VERSION "created by canmatrix"

NS_ :

BS_:

BU_: BDC_Body CHC DME1 EME FLA NiVi ZGW Kombi Kombi_Basis Diagnosetool_FA_CAN CDC_ZGW DME2 ELV Gliwa_T1_Host FA_CAN_Dummy

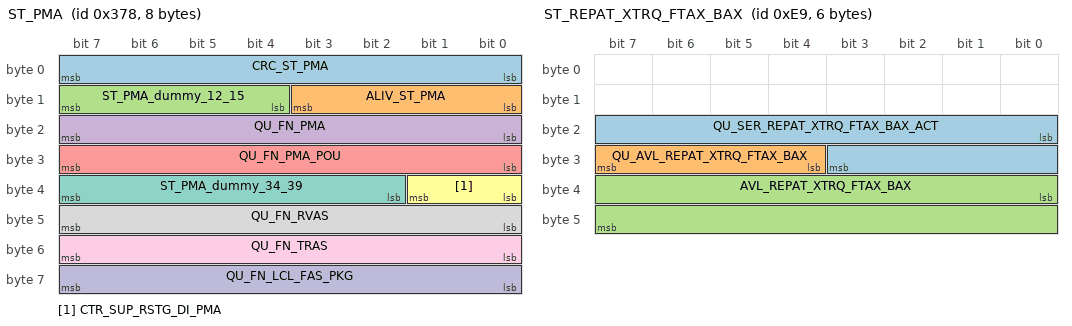
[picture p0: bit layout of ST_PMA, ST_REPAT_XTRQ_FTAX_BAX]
BO_ 888 ST_PMA: 8 ZGW
 SG_ CRC_ST_PMA : 0|8@1+ (1,0) [0|255] "This unit fulfills the required AUTOSAR reference to a unit. No real unit is defined." Vector__XXX
 SG_ ALIV_ST_PMA : 8|4@1+ (1,0) [0|15] "" Vector__XXX
 SG_ ST_PMA_dummy_12_15 : 12|4@1+ (1,0) [-8|7] "" Vector__XXX
 SG_ QU_FN_PMA : 16|8@1+ (1,0) [0|255] "" Vector__XXX
 SG_ QU_FN_PMA_POU : 24|8@1+ (1,0) [0|255] "" Vector__XXX
 SG_ CTR_SUP_RSTG_DI_PMA : 32|2@1+ (1,0) [0|3] "" Vector__XXX
 SG_ ST_PMA_dummy_34_39 : 34|6@1+ (1,0) [-32|31] "" Vector__XXX
 SG_ QU_FN_RVAS : 40|8@1+ (1,0) [0|255] "" Vector__XXX
 SG_ QU_FN_TRAS : 48|8@1+ (1,0) [0|255] "" Vector__XXX
 SG_ QU_FN_LCL_FAS_PKG : 56|8@1+ (1,0) [0|255] "" Vector__XXX

BO_ 1159 ST_PWF_CKM: 2 BDC_Body
 SG_ ST_PWF_SWO_LVG_CKM : 0|2@1+ (1,0) [0|3] "" ZGW

BO_ 669 ST_RCP: 8 ZGW
 SG_ RequestSBRandPreDriveCheck : 36|4@1+ (1,0) [0|15] "" Kombi,Kombi_Basis

BO_ 233 ST_REPAT_XTRQ_FTAX_BAX: 6 ZGW
 SG_ QU_SER_REPAT_XTRQ_FTAX_BAX_ACT : 16|12@1+ (1,0) [0|4095] "" DME1
 SG_ QU_AVL_REPAT_XTRQ_FTAX_BAX : 28|4@1+ (1,0) [0|15] "" DME1
 SG_ AVL_REPAT_XTRQ_FTAX_BAX : 32|16@1+ (1,-2500) [-5000|0] "Nm" DME1

BO_ 924 ST_RLS_ENGSTA_CARS: 8 ZGW
 SG_ ST_RLS_ENGSTA_CARS : 0|4@1+ (1,0) [0|15] "" BDC_Body

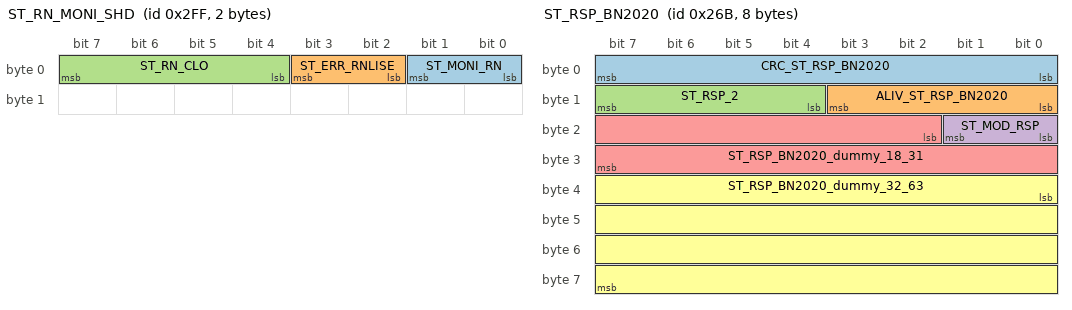
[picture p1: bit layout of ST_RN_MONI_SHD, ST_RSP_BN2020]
BO_ 767 ST_RN_MONI_SHD: 2 BDC_Body
 SG_ ST_MONI_RN : 0|2@1+ (1,0) [0|3] "" ZGW
 SG_ ST_ERR_RNLISE : 2|2@1+ (1,0) [0|3] "" ZGW
 SG_ ST_RN_CLO : 4|4@1+ (1,0) [0|15] "" ZGW

BO_ 619 ST_RSP_BN2020: 8 ZGW
 SG_ CRC_ST_RSP_BN2020 : 0|8@1+ (1,0) [0|255] "This unit fulfills the required AUTOSAR reference to a unit. No real unit is defined." Vector__XXX
 SG_ ALIV_ST_RSP_BN2020 : 8|4@1+ (1,0) [0|14] "This unit fulfills the required AUTOSAR reference to a unit. No real unit is defined." Vector__XXX
 SG_ ST_RSP_2 : 12|4@1+ (1,0) [0|15] "" Vector__XXX
 SG_ ST_MOD_RSP : 16|2@1+ (1,0) [0|3] "" Vector__XXX
 SG_ ST_RSP_BN2020_dummy_18_31 : 18|14@1+ (1,0) [-8192|8191] "" Vector__XXX
 SG_ ST_RSP_BN2020_dummy_32_63 : 32|32@1+ (1,0) [-2147483648|2147483647] "" Vector__XXX

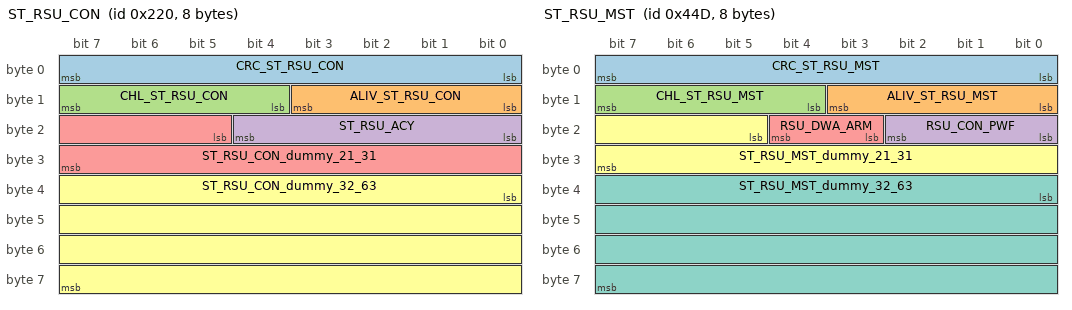
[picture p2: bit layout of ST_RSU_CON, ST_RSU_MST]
BO_ 544 ST_RSU_CON: 8 BDC_Body
 SG_ CRC_ST_RSU_CON : 0|8@1+ (1,0) [0|255] "This unit fulfills the required AUTOSAR reference to a unit. No real unit is defined." Vector__XXX
 SG_ ALIV_ST_RSU_CON : 8|4@1+ (1,0) [0|14] "This unit fulfills the required AUTOSAR reference to a unit. No real unit is defined." Vector__XXX
 SG_ CHL_ST_RSU_CON : 12|4@1+ (1,0) [0|14] "This unit fulfills the required AUTOSAR reference to a unit. No real unit is defined." Vector__XXX
 SG_ ST_RSU_ACY : 16|5@1+ (1,0) [0|31] "" Vector__XXX
 SG_ ST_RSU_CON_dummy_21_31 : 21|11@1+ (1,0) [-1024|1023] "" Vector__XXX
 SG_ ST_RSU_CON_dummy_32_63 : 32|32@1+ (1,0) [-2147483648|2147483647] "" Vector__XXX

BO_ 1101 ST_RSU_MST: 8 ZGW
 SG_ CRC_ST_RSU_MST : 0|8@1+ (1,0) [0|255] "This unit fulfills the required AUTOSAR reference to a unit. No real unit is defined." Vector__XXX
 SG_ ALIV_ST_RSU_MST : 8|4@1+ (1,0) [0|14] "This unit fulfills the required AUTOSAR reference to a unit. No real unit is defined." Vector__XXX
 SG_ CHL_ST_RSU_MST : 12|4@1+ (1,0) [0|14] "This unit fulfills the required AUTOSAR reference to a unit. No real unit is defined." Vector__XXX
 SG_ RSU_CON_PWF : 16|3@1+ (1,0) [0|7] "" Vector__XXX
 SG_ RSU_DWA_ARM : 19|2@1+ (1,0) [0|3] "" Vector__XXX
 SG_ ST_RSU_MST_dummy_21_31 : 21|11@1+ (1,0) [-1024|1023] "" Vector__XXX
 SG_ ST_RSU_MST_dummy_32_63 : 32|32@1+ (1,0) [-2147483648|2147483647] "" Vector__XXX

BO_ 1054 ST_SCHRG: 8 EME
 SG_ Multiplexor M : 0|8@1+ (1,0) [-128|127] "" Vector__XXX

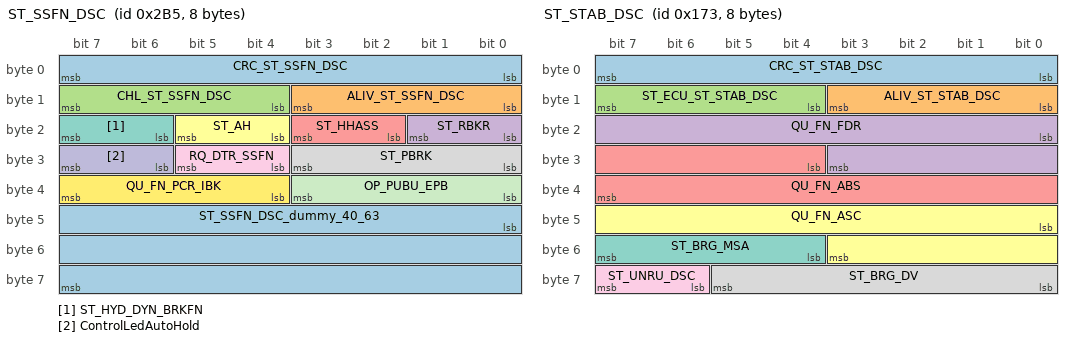
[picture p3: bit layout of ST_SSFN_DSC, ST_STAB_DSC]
BO_ 693 ST_SSFN_DSC: 8 ZGW
 SG_ CRC_ST_SSFN_DSC : 0|8@1+ (1,0) [0|255] "This unit fulfills the required AUTOSAR reference to a unit. No real unit is defined." Vector__XXX
 SG_ ALIV_ST_SSFN_DSC : 8|4@1+ (1,0) [0|14] "This unit fulfills the required AUTOSAR reference to a unit. No real unit is defined." Vector__XXX
 SG_ CHL_ST_SSFN_DSC : 12|4@1+ (1,0) [0|14] "This unit fulfills the required AUTOSAR reference to a unit. No real unit is defined." Vector__XXX
 SG_ ST_RBKR : 16|2@1+ (1,0) [0|3] "" Vector__XXX
 SG_ ST_HHASS : 18|2@1+ (1,0) [0|3] "" Vector__XXX
 SG_ ST_AH : 20|2@1+ (1,0) [0|3] "" Vector__XXX
 SG_ ST_HYD_DYN_BRKFN : 22|2@1+ (1,0) [0|3] "" Vector__XXX
 SG_ ST_PBRK : 24|4@1+ (1,0) [0|15] "" Vector__XXX
 SG_ RQ_DTR_SSFN : 28|2@1+ (1,0) [0|3] "" Vector__XXX
 SG_ ControlLedAutoHold : 30|2@1+ (1,0) [0|3] "" Vector__XXX
 SG_ OP_PUBU_EPB : 32|4@1+ (1,0) [0|15] "" Vector__XXX
 SG_ QU_FN_PCR_IBK : 36|4@1+ (1,0) [0|15] "" Vector__XXX
 SG_ ST_SSFN_DSC_dummy_40_63 : 40|24@1+ (1,0) [-8388608|8388607] "" Vector__XXX

BO_ 371 ST_STAB_DSC: 8 ZGW
 SG_ CRC_ST_STAB_DSC : 0|8@1+ (1,0) [0|255] "This unit fulfills the required AUTOSAR reference to a unit. No real unit is defined." Vector__XXX
 SG_ ALIV_ST_STAB_DSC : 8|4@1+ (1,0) [0|14] "This unit fulfills the required AUTOSAR reference to a unit. No real unit is defined." Vector__XXX
 SG_ ST_ECU_ST_STAB_DSC : 12|4@1+ (1,0) [0|15] "" Vector__XXX
 SG_ QU_FN_FDR : 16|12@1+ (1,0) [0|4095] "" Vector__XXX
 SG_ QU_FN_ABS : 28|12@1+ (1,0) [0|4095] "" Vector__XXX
 SG_ QU_FN_ASC : 40|12@1+ (1,0) [0|4095] "" Vector__XXX
 SG_ ST_BRG_MSA : 52|4@1+ (1,0) [0|15] "" Vector__XXX
 SG_ ST_BRG_DV : 56|6@1+ (1,0) [0|63] "" Vector__XXX
 SG_ ST_UNRU_DSC : 62|2@1+ (1,0) [0|3] "" Vector__XXX

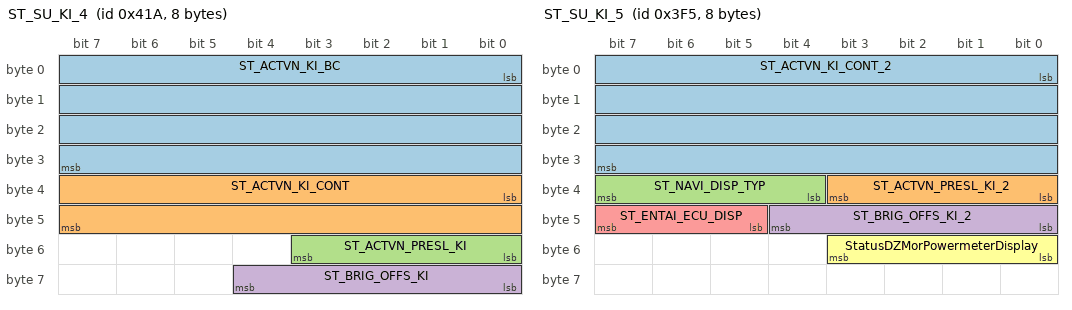
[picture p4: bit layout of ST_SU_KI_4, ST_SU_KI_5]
BO_ 1050 ST_SU_KI_4: 8 Kombi
 SG_ ST_ACTVN_KI_BC : 0|32@1+ (1,0) [0|4294967295] "" ZGW
 SG_ ST_ACTVN_KI_CONT : 32|16@1+ (1,0) [0|65535] "" ZGW
 SG_ ST_ACTVN_PRESL_KI : 48|4@1+ (1,0) [0|15] "" ZGW
 SG_ ST_BRIG_OFFS_KI : 56|5@1+ (1,0) [0|31] "" ZGW

BO_ 1013 ST_SU_KI_5: 8 Kombi
 SG_ ST_ACTVN_KI_CONT_2 : 0|32@1+ (1,0) [0|4294967295] "" ZGW
 SG_ ST_ACTVN_PRESL_KI_2 : 32|4@1+ (1,0) [0|15] "" ZGW
 SG_ ST_NAVI_DISP_TYP : 36|4@1+ (1,0) [0|15] "" ZGW
 SG_ ST_BRIG_OFFS_KI_2 : 40|5@1+ (1,0) [0|31] "" ZGW
 SG_ ST_ENTAI_ECU_DISP : 45|3@1+ (1,0) [0|7] "" ZGW
 SG_ StatusDZMorPowermeterDisplay : 48|4@1+ (1,0) [0|15] "" ZGW

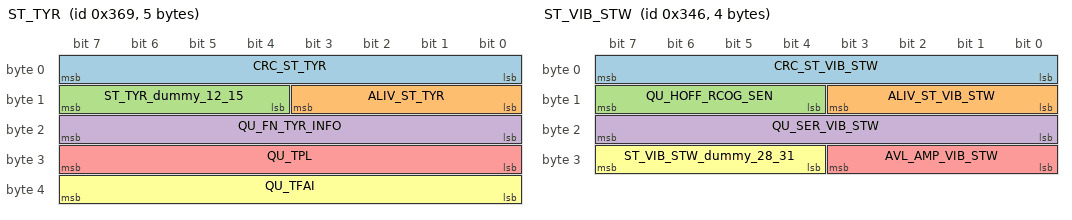
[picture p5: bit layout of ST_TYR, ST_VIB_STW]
BO_ 873 ST_TYR: 5 ZGW
 SG_ CRC_ST_TYR : 0|8@1+ (1,0) [0|255] "This unit fulfills the required AUTOSAR reference to a unit. No real unit is defined." Vector__XXX
 SG_ ALIV_ST_TYR : 8|4@1+ (1,0) [0|14] "This unit fulfills the required AUTOSAR reference to a unit. No real unit is defined." Vector__XXX
 SG_ ST_TYR_dummy_12_15 : 12|4@1+ (1,0) [-8|7] "" Vector__XXX
 SG_ QU_FN_TYR_INFO : 16|8@1+ (1,0) [0|255] "" Vector__XXX
 SG_ QU_TPL : 24|8@1+ (1,0) [0|255] "" Vector__XXX
 SG_ QU_TFAI : 32|8@1+ (1,0) [0|255] "" Vector__XXX

BO_ 905 ST_VA_HVBTC: 4 EME
 SG_ ST_CSOV_AIC : 8|4@1+ (1,0) [0|15] "" ZGW
 SG_ ST_PO_CSOV_AIC : 12|2@1+ (1,0) [0|3] "" ZGW

BO_ 895 ST_VEH_TONE: 2 ZGW
 SG_ ALIV_ST_VEH_TONE : 8|4@1+ (1,0) [0|14] "This unit fulfills the required AUTOSAR reference to a unit. No real unit is defined." Kombi
 SG_ ST_ACY_VEH_TONE : 12|2@1+ (1,0) [0|3] "" Kombi

BO_ 838 ST_VIB_STW: 4 BDC_Body
 SG_ CRC_ST_VIB_STW : 0|8@1+ (1,0) [0|255] "This unit fulfills the required AUTOSAR reference to a unit. No real unit is defined." Vector__XXX
 SG_ ALIV_ST_VIB_STW : 8|4@1+ (1,0) [0|15] "" Vector__XXX
 SG_ QU_HOFF_RCOG_SEN : 12|4@1+ (1,0) [0|15] "" Vector__XXX
 SG_ QU_SER_VIB_STW : 16|8@1+ (1,0) [0|255] "" Vector__XXX
 SG_ AVL_AMP_VIB_STW : 24|4@1+ (1,0) [0|15] "" Vector__XXX
 SG_ ST_VIB_STW_dummy_28_31 : 28|4@1+ (1,0) [-8|7] "" Vector__XXX

BO_ 271 ST_WBK: 8 ZGW
 SG_ QU_FN_BRCHAIN : 16|4@1+ (1,0) [0|15] "" NiVi
 SG_ QU_FN_WACHAIN : 20|4@1+ (1,0) [0|15] "" NiVi

BO_ 889 SU_CLE_DISP_DXP: 2 Kombi
 SG_ SU_FN_FRSG_ASST_DXP : 0|2@1+ (1,0) [0|3] "" FA_CAN_Dummy
 SG_ SU_VL_THO_ECS_DXP : 8|8@1+ (1,0) [1|250] "km/h" FA_CAN_Dummy

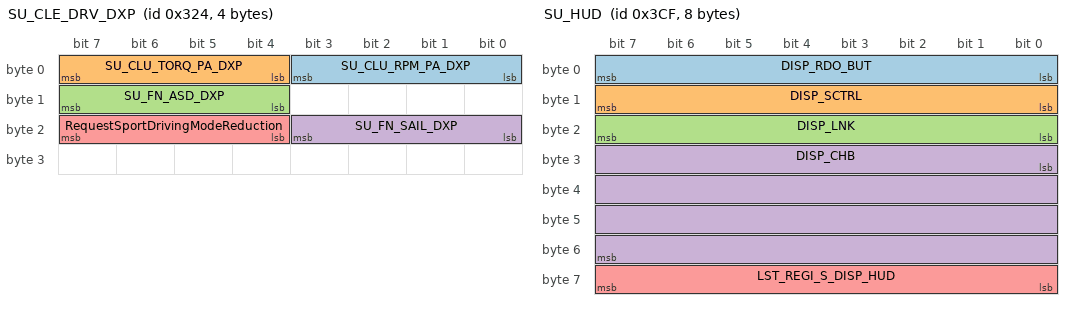
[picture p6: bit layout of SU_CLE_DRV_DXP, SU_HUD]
BO_ 804 SU_CLE_DRV_DXP: 4 DME1
 SG_ SU_CLU_RPM_PA_DXP : 0|4@1+ (1,0) [0|15] "" Vector__XXX
 SG_ SU_CLU_TORQ_PA_DXP : 4|4@1+ (1,0) [0|15] "" ZGW
 SG_ SU_FN_ASD_DXP : 12|4@1+ (1,0) [0|15] "" ZGW
 SG_ SU_FN_SAIL_DXP : 16|4@1+ (1,0) [0|15] "" Vector__XXX
 SG_ RequestSportDrivingModeReduction : 20|4@1+ (10,0) [0|1000] "%" Vector__XXX

BO_ 975 SU_HUD: 8 Kombi
 SG_ DISP_RDO_BUT : 0|8@1+ (1,0) [0|255] "" ZGW
 SG_ DISP_SCTRL : 8|8@1+ (1,0) [0|255] "" ZGW
 SG_ DISP_LNK : 16|8@1+ (1,0) [0|255] "" ZGW
 SG_ DISP_CHB : 24|32@1+ (1,0) [0|4294967295] "" ZGW
 SG_ LST_REGI_S_DISP_HUD : 56|8@1+ (1,0) [0|255] "" ZGW

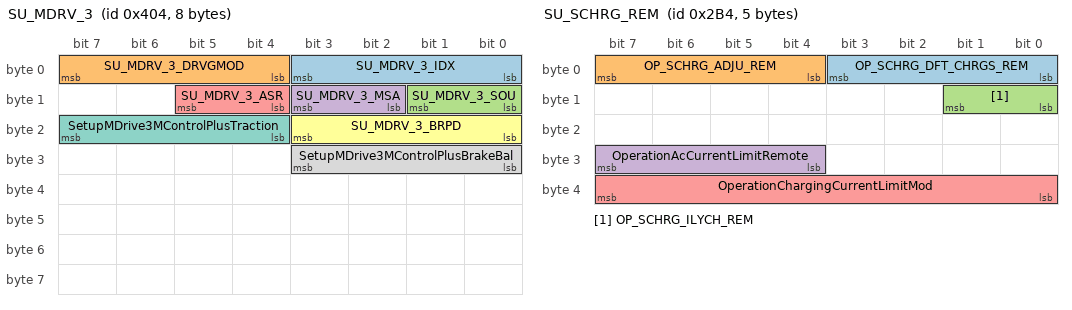
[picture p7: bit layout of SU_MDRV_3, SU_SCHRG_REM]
BO_ 1028 SU_MDRV_3: 8 ZGW
 SG_ SU_MDRV_3_IDX : 0|4@1+ (1,0) [0|15] "" DME2,DME1
 SG_ SU_MDRV_3_DRVGMOD : 4|4@1+ (1,0) [0|15] "" DME2,DME1
 SG_ SU_MDRV_3_SOU : 8|2@1+ (1,0) [0|3] "" DME2,DME1
 SG_ SU_MDRV_3_MSA : 10|2@1+ (1,0) [0|3] "" DME2,DME1
 SG_ SU_MDRV_3_ASR : 12|2@1+ (1,0) [0|3] "" DME2,DME1
 SG_ SU_MDRV_3_BRPD : 16|4@1+ (1,0) [0|15] "" DME2,DME1
 SG_ SetupMDrive3MControlPlusTraction : 20|4@1+ (1,0) [0|15] "" DME1
 SG_ SetupMDrive3MControlPlusBrakeBal : 24|4@1+ (1,0) [0|15] "" DME1

BO_ 1049 SU_PWF_CKM: 2 ZGW
 SG_ SU_PWF_SWO_LVG_CKM : 0|2@1+ (1,0) [0|3] "" BDC_Body

BO_ 737 SU_SCHRG: 8 ZGW
 SG_ Multiplexor M : 0|8@1+ (1,0) [-128|127] "" Vector__XXX

BO_ 646 SU_SCHRG_CERT: 8 ZGW
 SG_ Multiplexor M : 0|8@1+ (1,0) [-128|127] "" Vector__XXX

BO_ 717 SU_SCHRG_KEY: 2 BDC_Body
 SG_ OP_SCHRG_DFT_CHRGS_KEY : 0|4@1+ (1,0) [0|15] "" EME
 SG_ OP_SCHRG_ILYCH_KEY : 4|2@1+ (1,0) [0|3] "" EME

BO_ 692 SU_SCHRG_REM: 5 ZGW
 SG_ OP_SCHRG_DFT_CHRGS_REM : 0|4@1+ (1,0) [0|15] "" EME
 SG_ OP_SCHRG_ADJU_REM : 4|4@1+ (1,0) [0|15] "" EME
 SG_ OP_SCHRG_ILYCH_REM : 8|2@1+ (1,0) [0|3] "" EME
 SG_ OperationAcCurrentLimitRemote : 28|4@1+ (1,0) [0|15] "" EME
 SG_ OperationChargingCurrentLimitMod : 32|8@1+ (1,0) [0|250] "A" EME

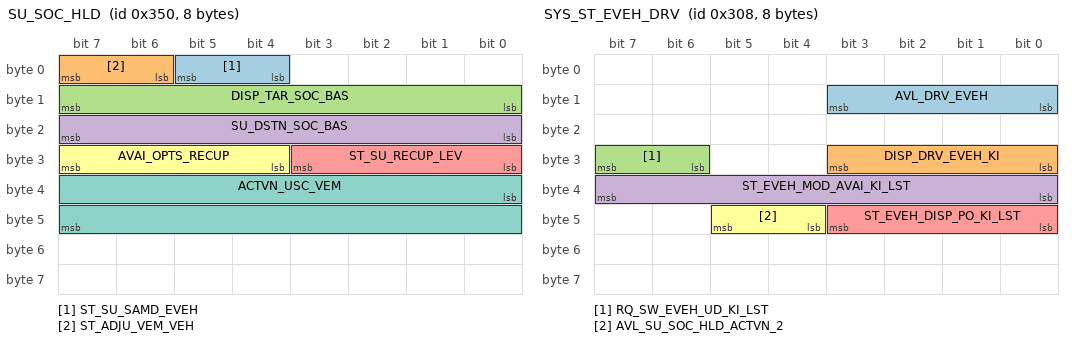
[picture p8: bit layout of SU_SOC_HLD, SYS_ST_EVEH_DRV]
BO_ 848 SU_SOC_HLD: 8 DME1
 SG_ ST_SU_SAMD_EVEH : 4|2@1+ (1,0) [0|3] "" ZGW
 SG_ ST_ADJU_VEM_VEH : 6|2@1+ (1,0) [0|3] "" ZGW
 SG_ DISP_TAR_SOC_BAS : 8|8@1+ (1,0) [0|100] "%" ZGW
 SG_ SU_DSTN_SOC_BAS : 16|8@1+ (1,0) [0|100] "%" EME
 SG_ ST_SU_RECUP_LEV : 24|4@1+ (1,0) [0|15] "" ZGW,Kombi,Kombi_Basis
 SG_ AVAI_OPTS_RECUP : 28|4@1+ (1,0) [0|15] "" ZGW,Kombi,Kombi_Basis
 SG_ ACTVN_USC_VEM : 32|16@1+ (1,0) [0|65535] "" EME

BO_ 776 SYS_ST_EVEH_DRV: 8 ZGW
 SG_ AVL_DRV_EVEH : 8|4@1+ (1,0) [0|15] "" Kombi,Kombi_Basis
 SG_ DISP_DRV_EVEH_KI : 24|4@1+ (1,0) [0|15] "" Kombi
 SG_ RQ_SW_EVEH_UD_KI_LST : 30|2@1+ (1,0) [0|3] "" Kombi,Kombi_Basis
 SG_ ST_EVEH_MOD_AVAI_KI_LST : 32|8@1+ (1,0) [0|255] "" Kombi,Kombi_Basis
 SG_ ST_EVEH_DISP_PO_KI_LST : 40|4@1+ (1,0) [0|15] "" Kombi,Kombi_Basis
 SG_ AVL_SU_SOC_HLD_ACTVN_2 : 44|2@1+ (1,0) [0|3] "" Kombi,Kombi_Basis

BO_ 129 SecurityStatus: 8 BDC_Body
 SG_ DataApplicationSecurityStatus : 0|64@1+ (1,0) [-9223372036854775808|9223372036854775807] "This unit fulfills the required AUTOSAR reference to a unit. No real unit is defined." Diagnosetool_FA_CAN

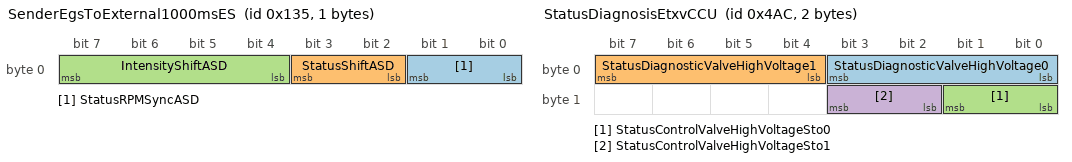
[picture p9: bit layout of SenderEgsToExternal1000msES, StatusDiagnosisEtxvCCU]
BO_ 309 SenderEgsToExternal1000msES: 1 DME1
 SG_ StatusRPMSyncASD : 0|2@1+ (1,0) [0|3] "" ZGW
 SG_ StatusShiftASD : 2|2@1+ (1,0) [0|3] "" ZGW
 SG_ IntensityShiftASD : 4|4@1+ (1,0) [0|10] "This unit fulfills the required AUTOSAR reference to a unit. No real unit is defined." ZGW

BO_ 750 ServiceBrake: 8 Kombi
 SG_ FunctionBrake : 0|4@1+ (1,0) [0|15] "" ZGW

BO_ 347 StatusAlcoholInterlockDevice: 8 BDC_Body
 SG_ StatusAlcoholInterlockDevice : 0|4@1+ (1,0) [0|15] "" Diagnosetool_FA_CAN
 SG_ StatusActivationAlcoholInterlock : 4|2@1+ (1,0) [0|3] "" Diagnosetool_FA_CAN

BO_ 1106 StatusCoolantLevel: 2 ZGW
 SG_ VoltageSensorCoolantLevel : 0|12@1+ (1.62,0) [0.00|10692.00] "mV" DME1

BO_ 1196 StatusDiagnosisEtxvCCU: 2 EME
 SG_ StatusDiagnosticValveHighVoltage0 : 0|4@1+ (1,0) [0|15] "" ZGW
 SG_ StatusDiagnosticValveHighVoltage1 : 4|4@1+ (1,0) [0|15] "" ZGW
 SG_ StatusControlValveHighVoltageSto0 : 8|2@1+ (1,0) [0|3] "" ZGW
 SG_ StatusControlValveHighVoltageSto1 : 10|2@1+ (1,0) [0|3] "" ZGW

BO_ 1095 StatusKeyAction: 8 BDC_Body
 SG_ StatusKeyFunction : 0|8@1+ (1,0) [0|255] "" ZGW
 SG_ StatusKeyId : 8|24@1+ (1,0) [0|16777215] "" ZGW

BO_ 702 StatusPowertrainErrorSourceInfor: 8 DME1
 SG_ StatusPowertrainErrorSource : 16|16@1+ (1,0) [0|65535] "" Diagnosetool_FA_CAN

BO_ 1197 StatusTemperatureAndDiagnosisFun: 8 EME
 SG_ StatusDiagnosisFunctionalValve1S0 : 0|8@1+ (1,0) [0|255] "" ZGW
 SG_ StatusDiagnosisFunctionalValve1S1 : 8|8@1+ (1,0) [0|255] "" ZGW
 SG_ StatusDiagnosisFunctionalCPIHigh : 16|8@1+ (1,0) [0|255] "" ZGW
 SG_ ActualValueTemperatureHighVoltag0 : 24|8@1+ (0.5,-40) [-60|3] "°C" ZGW
 SG_ ActualValueTemperatureHighVoltag1 : 32|8@1+ (0.5,-40) [-60|3] "°C" ZGW
 SG_ ActualValueTemperatureHighVoltag2 : 40|8@1+ (0.5,-40) [-60|3] "°C" ZGW
 SG_ ActualValueTemperatureHeatExchan : 48|10@1+ (0.125,-40) [-45.000|-29.250] "°C" ZGW
 SG_ RequestValveHighVoltageStorage1 : 58|2@1+ (1,0) [0|3] "" ZGW

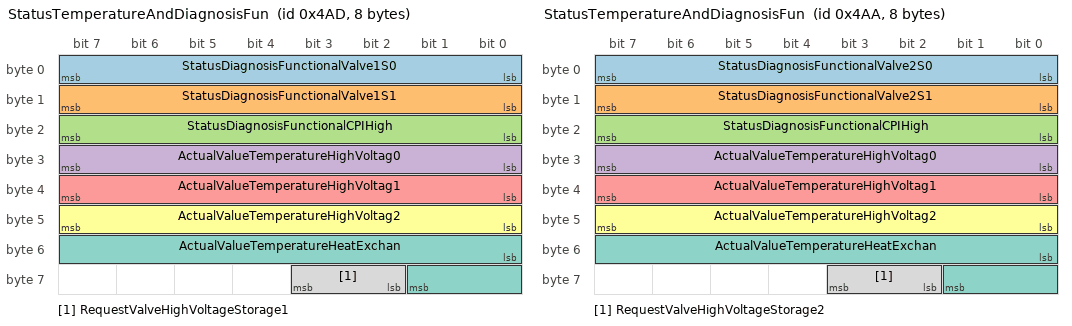
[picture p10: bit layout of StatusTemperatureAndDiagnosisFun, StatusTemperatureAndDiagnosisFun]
BO_ 1194 StatusTemperatureAndDiagnosisFun: 8 EME
 SG_ StatusDiagnosisFunctionalValve2S0 : 0|8@1+ (1,0) [0|255] "" ZGW
 SG_ StatusDiagnosisFunctionalValve2S1 : 8|8@1+ (1,0) [0|255] "" ZGW
 SG_ StatusDiagnosisFunctionalCPIHigh : 16|8@1+ (1,0) [0|255] "" ZGW
 SG_ ActualValueTemperatureHighVoltag0 : 24|8@1+ (0.5,-40) [-60|3] "°C" ZGW
 SG_ ActualValueTemperatureHighVoltag1 : 32|8@1+ (0.5,-40) [-60|3] "°C" ZGW
 SG_ ActualValueTemperatureHighVoltag2 : 40|8@1+ (0.5,-40) [-60|3] "°C" ZGW
 SG_ ActualValueTemperatureHeatExchan : 48|10@1+ (0.125,-40) [-45.000|-29.250] "°C" ZGW
 SG_ RequestValveHighVoltageStorage2 : 58|2@1+ (1,0) [0|3] "" ZGW

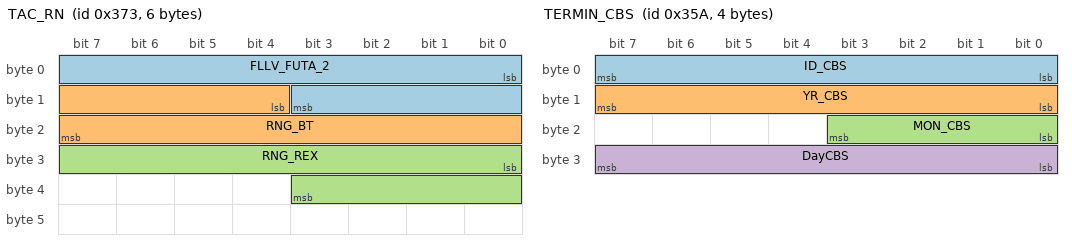
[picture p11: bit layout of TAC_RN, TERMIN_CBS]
BO_ 883 TAC_RN: 6 Kombi
 SG_ FLLV_FUTA_2 : 0|12@1+ (0.025,0) [0.000|2.550] "l" ZGW,DME2,DME1
 SG_ RNG_BT : 12|12@1+ (1,0) [0|4092] "km" ZGW,DME2,DME1
 SG_ RNG_REX : 24|12@1+ (1,0) [0|4092] "km" ZGW,DME2,DME1

BO_ 858 TERMIN_CBS: 4 ZGW
 SG_ ID_CBS : 0|8@1+ (1,0) [0|255] "" Kombi,Kombi_Basis
 SG_ YR_CBS : 8|8@1+ (1,0) [0|99] "This unit fulfills the required AUTOSAR reference to a unit. No real unit is defined." Kombi,Kombi_Basis
 SG_ MON_CBS : 16|4@1+ (1,0) [1|12] "This unit fulfills the required AUTOSAR reference to a unit. No real unit is defined." Kombi,Kombi_Basis
 SG_ DayCBS : 24|8@1+ (1,0) [1|31] "This unit fulfills the required AUTOSAR reference to a unit. No real unit is defined." Kombi,Kombi_Basis

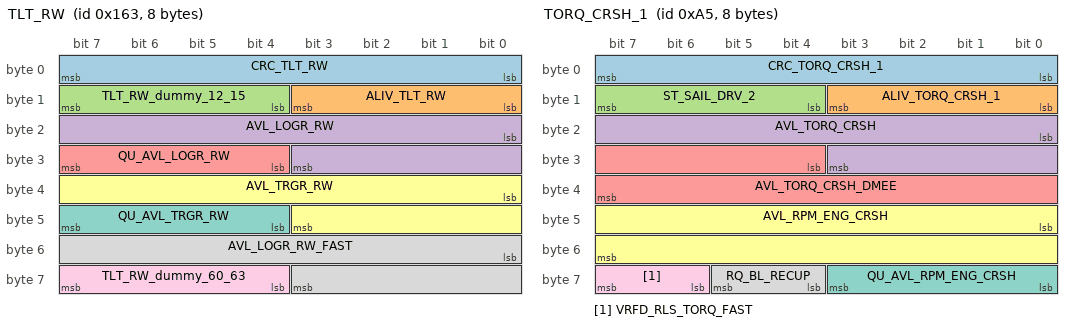
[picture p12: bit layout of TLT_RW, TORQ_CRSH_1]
BO_ 355 TLT_RW: 8 ZGW
 SG_ CRC_TLT_RW : 0|8@1+ (1,0) [0|255] "This unit fulfills the required AUTOSAR reference to a unit. No real unit is defined." Vector__XXX
 SG_ ALIV_TLT_RW : 8|4@1+ (1,0) [0|14] "This unit fulfills the required AUTOSAR reference to a unit. No real unit is defined." Vector__XXX
 SG_ TLT_RW_dummy_12_15 : 12|4@1+ (1,0) [-8|7] "" Vector__XXX
 SG_ AVL_LOGR_RW : 16|12@1+ (0.05,-64) [-67.20|-60.80] "°" Vector__XXX
 SG_ QU_AVL_LOGR_RW : 28|4@1+ (1,0) [0|15] "" Vector__XXX
 SG_ AVL_TRGR_RW : 32|12@1+ (0.05,-64) [-67.20|-60.80] "°" Vector__XXX
 SG_ QU_AVL_TRGR_RW : 44|4@1+ (1,0) [0|15] "" Vector__XXX
 SG_ AVL_LOGR_RW_FAST : 48|12@1+ (0.05,-64) [-67.20|-60.80] "°" Vector__XXX
 SG_ TLT_RW_dummy_60_63 : 60|4@1+ (1,0) [-8|7] "" Vector__XXX

BO_ 165 TORQ_CRSH_1: 8 DME1
 SG_ CRC_TORQ_CRSH_1 : 0|8@1+ (1,0) [0|255] "This unit fulfills the required AUTOSAR reference to a unit. No real unit is defined." Vector__XXX
 SG_ ALIV_TORQ_CRSH_1 : 8|4@1+ (1,0) [0|14] "This unit fulfills the required AUTOSAR reference to a unit. No real unit is defined." Vector__XXX
 SG_ ST_SAIL_DRV_2 : 12|4@1+ (1,0) [0|15] "" Vector__XXX
 SG_ AVL_TORQ_CRSH : 16|12@1+ (0.5,-1023.5) [-1535.25|-511.75] "Nm" Vector__XXX
 SG_ AVL_TORQ_CRSH_DMEE : 28|12@1+ (0.5,-1023.5) [-1535.25|-511.75] "Nm" Vector__XXX
 SG_ AVL_RPM_ENG_CRSH : 40|16@1+ (0.25,0) [0.00|3000.00] "1/min" Vector__XXX
 SG_ QU_AVL_RPM_ENG_CRSH : 56|4@1+ (1,0) [0|15] "" Vector__XXX
 SG_ RQ_BL_RECUP : 60|2@1+ (1,0) [0|3] "" Vector__XXX
 SG_ VRFD_RLS_TORQ_FAST : 62|2@1+ (1,0) [0|3] "" Vector__XXX

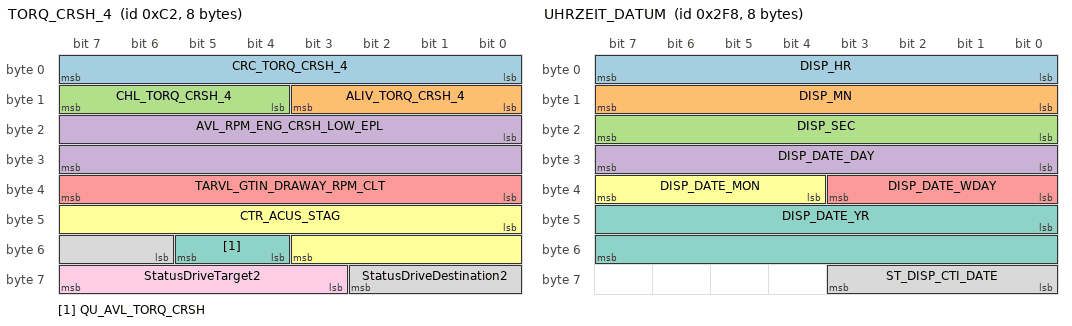
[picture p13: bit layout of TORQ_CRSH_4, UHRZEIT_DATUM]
BO_ 194 TORQ_CRSH_4: 8 DME1
 SG_ CRC_TORQ_CRSH_4 : 0|8@1+ (1,0) [0|255] "This unit fulfills the required AUTOSAR reference to a unit. No real unit is defined." Vector__XXX
 SG_ ALIV_TORQ_CRSH_4 : 8|4@1+ (1,0) [0|14] "This unit fulfills the required AUTOSAR reference to a unit. No real unit is defined." Vector__XXX
 SG_ CHL_TORQ_CRSH_4 : 12|4@1+ (1,0) [0|14] "This unit fulfills the required AUTOSAR reference to a unit. No real unit is defined." Vector__XXX
 SG_ AVL_RPM_ENG_CRSH_LOW_EPL : 16|16@1+ (1,-900) [-1800|63732] "1/min" Vector__XXX
 SG_ TARVL_GTIN_DRAWAY_RPM_CLT : 32|8@1+ (10,500) [5500|25500] "1/min" Vector__XXX
 SG_ CTR_ACUS_STAG : 40|12@1+ (1,0) [0|4092] "This unit fulfills the required AUTOSAR reference to a unit. No real unit is defined." Vector__XXX
 SG_ QU_AVL_TORQ_CRSH : 52|2@1+ (1,0) [0|3] "" Vector__XXX
 SG_ StatusDriveDestination2 : 54|5@1+ (1,0) [0|31] "" Vector__XXX
 SG_ StatusDriveTarget2 : 59|5@1+ (1,0) [0|31] "" Vector__XXX

BO_ 760 UHRZEIT_DATUM: 8 Kombi
 SG_ DISP_HR : 0|8@1+ (1,0) [0|23] "h" Vector__XXX
 SG_ DISP_MN : 8|8@1+ (1,0) [0|59] "min" Vector__XXX
 SG_ DISP_SEC : 16|8@1+ (1,0) [0|59] "s" Vector__XXX
 SG_ DISP_DATE_DAY : 24|8@1+ (1,0) [1|31] "This unit fulfills the required AUTOSAR reference to a unit. No real unit is defined." Vector__XXX
 SG_ DISP_DATE_WDAY : 32|4@1+ (1,0) [0|15] "" Vector__XXX
 SG_ DISP_DATE_MON : 36|4@1+ (1,0) [1|12] "This unit fulfills the required AUTOSAR reference to a unit. No real unit is defined." Vector__XXX
 SG_ DISP_DATE_YR : 40|16@1+ (1,0) [1|65534] "This unit fulfills the required AUTOSAR reference to a unit. No real unit is defined." Vector__XXX
 SG_ ST_DISP_CTI_DATE : 56|4@1+ (1,0) [0|15] "" Vector__XXX

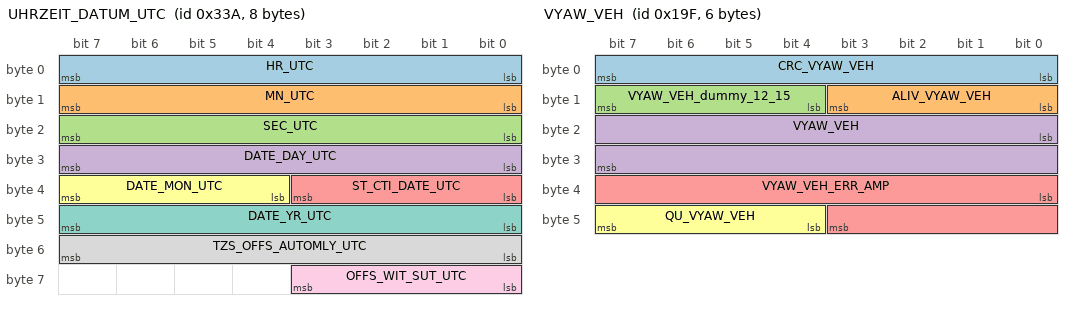
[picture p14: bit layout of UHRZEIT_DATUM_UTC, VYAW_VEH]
BO_ 826 UHRZEIT_DATUM_UTC: 8 Kombi
 SG_ HR_UTC : 0|8@1+ (1,0) [0|23] "h" CDC_ZGW,BDC_Body,ZGW
 SG_ MN_UTC : 8|8@1+ (1,0) [0|59] "min" CDC_ZGW,BDC_Body,ZGW
 SG_ SEC_UTC : 16|8@1+ (1,0) [0|59] "This unit fulfills the required AUTOSAR reference to a unit. No real unit is defined." CDC_ZGW,BDC_Body,ZGW
 SG_ DATE_DAY_UTC : 24|8@1+ (1,1) [2|32] "This unit fulfills the required AUTOSAR reference to a unit. No real unit is defined." CDC_ZGW,BDC_Body,ZGW
 SG_ ST_CTI_DATE_UTC : 32|4@1+ (1,0) [0|15] "" CDC_ZGW,BDC_Body,ZGW
 SG_ DATE_MON_UTC : 36|4@1+ (1,1) [2|13] "This unit fulfills the required AUTOSAR reference to a unit. No real unit is defined." CDC_ZGW,BDC_Body,ZGW
 SG_ DATE_YR_UTC : 40|8@1+ (1,1) [2|253] "This unit fulfills the required AUTOSAR reference to a unit. No real unit is defined." CDC_ZGW,BDC_Body,ZGW
 SG_ TZS_OFFS_AUTOMLY_UTC : 48|8@1+ (0.25,-20) [-25.00|-9.25] "h" ZGW
 SG_ OFFS_WIT_SUT_UTC : 56|4@1+ (0.5,-3) [-4.5|-1.5] "h" ZGW

BO_ 772 U_BN: 6 DME1
 SG_ U_IBS : 16|16@1+ (0.001,0) [0.000|0.065532] "V" ZGW,CHC
 SG_ ST_STRY_U_PWMG : 32|4@1+ (1,0) [0|15] "" ZGW,DME1

BO_ 415 VYAW_VEH: 6 ZGW
 SG_ CRC_VYAW_VEH : 0|8@1+ (1,0) [0|255] "This unit fulfills the required AUTOSAR reference to a unit. No real unit is defined." Vector__XXX
 SG_ ALIV_VYAW_VEH : 8|4@1+ (1,0) [0|14] "This unit fulfills the required AUTOSAR reference to a unit. No real unit is defined." Vector__XXX
 SG_ VYAW_VEH_dummy_12_15 : 12|4@1+ (1,0) [-8|7] "" Vector__XXX
 SG_ VYAW_VEH : 16|16@1+ (0.005,-163.84) [-164.65920|-163.02085] "°/s" Vector__XXX
 SG_ VYAW_VEH_ERR_AMP : 32|12@1+ (0.0125,0) [0.0000|0.6250] "°/s" Vector__XXX
 SG_ QU_VYAW_VEH : 44|4@1+ (1,0) [0|15] "" Vector__XXX

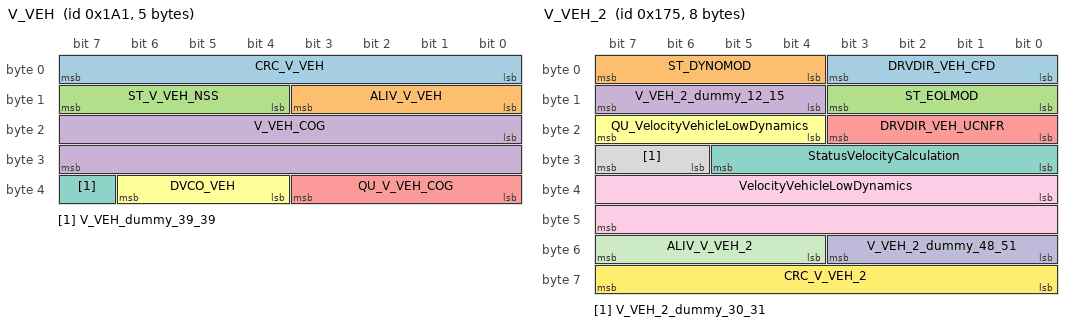
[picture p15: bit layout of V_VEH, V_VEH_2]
BO_ 417 V_VEH: 5 ZGW
 SG_ CRC_V_VEH : 0|8@1+ (1,0) [0|255] "This unit fulfills the required AUTOSAR reference to a unit. No real unit is defined." Vector__XXX
 SG_ ALIV_V_VEH : 8|4@1+ (1,0) [0|14] "This unit fulfills the required AUTOSAR reference to a unit. No real unit is defined." Vector__XXX
 SG_ ST_V_VEH_NSS : 12|4@1+ (1,0) [0|15] "" Vector__XXX
 SG_ V_VEH_COG : 16|16@1+ (0.015625,0) [0.000000|5.468750] "km/h" Vector__XXX
 SG_ QU_V_VEH_COG : 32|4@1+ (1,0) [0|15] "" Vector__XXX
 SG_ DVCO_VEH : 36|3@1+ (1,0) [0|7] "" Vector__XXX
 SG_ V_VEH_dummy_39_39 : 39|1@1+ (1,0) [-1|0] "" Vector__XXX

BO_ 373 V_VEH_2: 8 ZGW
 SG_ DRVDIR_VEH_CFD : 0|4@1+ (1,0) [0|15] "" Vector__XXX
 SG_ ST_DYNOMOD : 4|4@1+ (1,0) [0|15] "" Vector__XXX
 SG_ ST_EOLMOD : 8|4@1+ (1,0) [0|15] "" Vector__XXX
 SG_ V_VEH_2_dummy_12_15 : 12|4@1+ (1,0) [-8|7] "" Vector__XXX
 SG_ DRVDIR_VEH_UCNFR : 16|4@1+ (1,0) [0|15] "" Vector__XXX
 SG_ QU_VelocityVehicleLowDynamics : 20|4@1+ (1,0) [0|15] "" Vector__XXX
 SG_ StatusVelocityCalculation : 24|6@1+ (1,0) [0|63] "" Vector__XXX
 SG_ V_VEH_2_dummy_30_31 : 30|2@1+ (1,0) [-2|1] "" Vector__XXX
 SG_ VelocityVehicleLowDynamics : 32|16@1+ (0.015625,0) [0.000000|5.468750] "km/h" Vector__XXX
 SG_ V_VEH_2_dummy_48_51 : 48|4@1+ (1,0) [-8|7] "" Vector__XXX
 SG_ ALIV_V_VEH_2 : 52|4@1+ (1,0) [0|14] "This unit fulfills the required AUTOSAR reference to a unit. No real unit is defined." Vector__XXX
 SG_ CRC_V_VEH_2 : 56|8@1+ (1,0) [0|255] "This unit fulfills the required AUTOSAR reference to a unit. No real unit is defined." Vector__XXX

BO_ 1037 WEL_STAG: 8 Kombi
 SG_ ST_STAGMST : 0|8@1+ (1,0) [0|255] "" ZGW
 SG_ TR_STAG_HU : 8|8@1+ (1,0) [0|255] "" ZGW

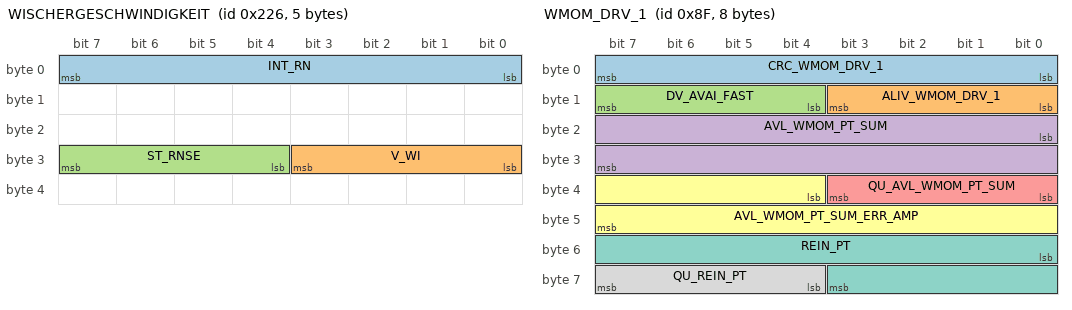
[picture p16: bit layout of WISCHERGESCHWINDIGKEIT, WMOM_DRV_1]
BO_ 550 WISCHERGESCHWINDIGKEIT: 5 BDC_Body
 SG_ INT_RN : 0|8@1+ (0.5,0) [0|63.5] "%" CDC_ZGW,ZGW,FLA
 SG_ V_WI : 24|4@1+ (2,33) [103|155] "1/min" CDC_ZGW,FLA,DME2,DME1,ZGW,NiVi
 SG_ ST_RNSE : 28|4@1+ (1,0) [0|15] "" ZGW,FLA

BO_ 143 WMOM_DRV_1: 8 DME1
 SG_ CRC_WMOM_DRV_1 : 0|8@1+ (1,0) [0|255] "This unit fulfills the required AUTOSAR reference to a unit. No real unit is defined." Vector__XXX
 SG_ ALIV_WMOM_DRV_1 : 8|4@1+ (1,0) [0|15] "" Vector__XXX
 SG_ DV_AVAI_FAST : 12|4@1+ (1,0) [0|15] "" Vector__XXX
 SG_ AVL_WMOM_PT_SUM : 16|16@1+ (1,-32000) [-64000|0] "Nm" Vector__XXX
 SG_ QU_AVL_WMOM_PT_SUM : 32|4@1+ (1,0) [0|15] "" Vector__XXX
 SG_ AVL_WMOM_PT_SUM_ERR_AMP : 36|12@1+ (4,0) [0|64000] "Nm" Vector__XXX
 SG_ REIN_PT : 48|12@1+ (0.125,0) [0.000|63.96875] "This unit fulfills the required AUTOSAR reference to a unit. No real unit is defined." Vector__XXX
 SG_ QU_REIN_PT : 60|4@1+ (1,0) [0|15] "" Vector__XXX

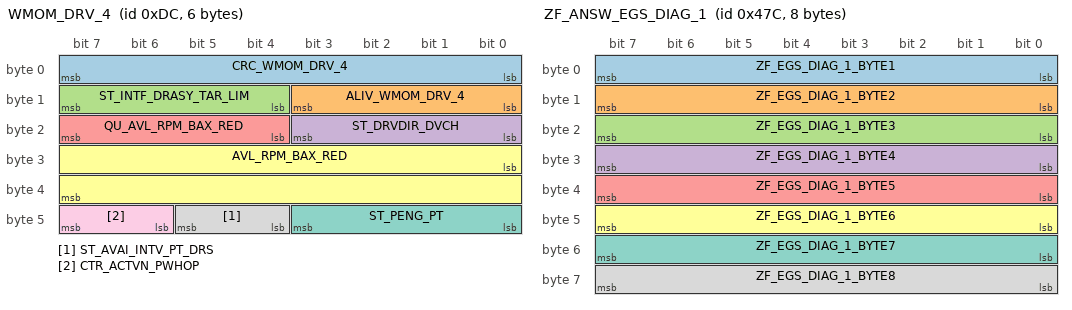
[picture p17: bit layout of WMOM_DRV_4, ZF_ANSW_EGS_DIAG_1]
BO_ 220 WMOM_DRV_4: 6 DME1
 SG_ CRC_WMOM_DRV_4 : 0|8@1+ (1,0) [0|255] "This unit fulfills the required AUTOSAR reference to a unit. No real unit is defined." Vector__XXX
 SG_ ALIV_WMOM_DRV_4 : 8|4@1+ (1,0) [0|14] "This unit fulfills the required AUTOSAR reference to a unit. No real unit is defined." Vector__XXX
 SG_ ST_INTF_DRASY_TAR_LIM : 12|4@1+ (1,0) [0|15] "" Vector__XXX
 SG_ ST_DRVDIR_DVCH : 16|4@1+ (1,0) [0|15] "" Vector__XXX
 SG_ QU_AVL_RPM_BAX_RED : 20|4@1+ (1,0) [0|15] "" Vector__XXX
 SG_ AVL_RPM_BAX_RED : 24|16@1+ (1,-2000) [-4000|12000] "1/min" Vector__XXX
 SG_ ST_PENG_PT : 40|4@1+ (1,0) [0|15] "" Vector__XXX
 SG_ ST_AVAI_INTV_PT_DRS : 44|2@1+ (1,0) [0|3] "" Vector__XXX
 SG_ CTR_ACTVN_PWHOP : 46|2@1+ (1,0) [0|3] "" Vector__XXX

BO_ 1985 XCPIFMDAQ1: 8 DME1
 SG_ XCPDummysignalIFMDAQ1 : 0|8@1+ (1,0) [0|255] "This unit fulfills the required AUTOSAR reference to a unit. No real unit is defined." ZGW

BO_ 1986 XCPIFMDAQ2: 8 DME1
 SG_ XCPDummysignalIFMDAQ2 : 0|8@1+ (1,0) [0|255] "This unit fulfills the required AUTOSAR reference to a unit. No real unit is defined." ZGW

BO_ 1987 XCPIFMDAQ3: 8 DME1
 SG_ XCPDummysignalIFMDAQ3 : 0|8@1+ (1,0) [0|255] "This unit fulfills the required AUTOSAR reference to a unit. No real unit is defined." ZGW

BO_ 1974 XCPIFMRequest: 8 ZGW
 SG_ XCPDummysignalIFMRequest : 0|8@1+ (1,0) [0|255] "This unit fulfills the required AUTOSAR reference to a unit. No real unit is defined." DME1

BO_ 1984 XCPIFMResponse: 8 DME1
 SG_ XCPDummysignalIFMResponse : 0|8@1+ (1,0) [0|255] "This unit fulfills the required AUTOSAR reference to a unit. No real unit is defined." ZGW

BO_ 1148 ZF_ANSW_EGS_DIAG_1: 8 DME1
 SG_ ZF_EGS_DIAG_1_BYTE1 : 0|8@1+ (1,0) [0|255] "This unit fulfills the required AUTOSAR reference to a unit. No real unit is defined." ZGW
 SG_ ZF_EGS_DIAG_1_BYTE2 : 8|8@1+ (1,0) [0|255] "This unit fulfills the required AUTOSAR reference to a unit. No real unit is defined." ZGW
 SG_ ZF_EGS_DIAG_1_BYTE3 : 16|8@1+ (1,0) [0|255] "This unit fulfills the required AUTOSAR reference to a unit. No real unit is defined." ZGW
 SG_ ZF_EGS_DIAG_1_BYTE4 : 24|8@1+ (1,0) [0|255] "This unit fulfills the required AUTOSAR reference to a unit. No real unit is defined." ZGW
 SG_ ZF_EGS_DIAG_1_BYTE5 : 32|8@1+ (1,0) [0|255] "This unit fulfills the required AUTOSAR reference to a unit. No real unit is defined." ZGW
 SG_ ZF_EGS_DIAG_1_BYTE6 : 40|8@1+ (1,0) [0|255] "This unit fulfills the required AUTOSAR reference to a unit. No real unit is defined." ZGW
 SG_ ZF_EGS_DIAG_1_BYTE7 : 48|8@1+ (1,0) [0|255] "This unit fulfills the required AUTOSAR reference to a unit. No real unit is defined." ZGW
 SG_ ZF_EGS_DIAG_1_BYTE8 : 56|8@1+ (1,0) [0|255] "This unit fulfills the required AUTOSAR reference to a unit. No real unit is defined." ZGW

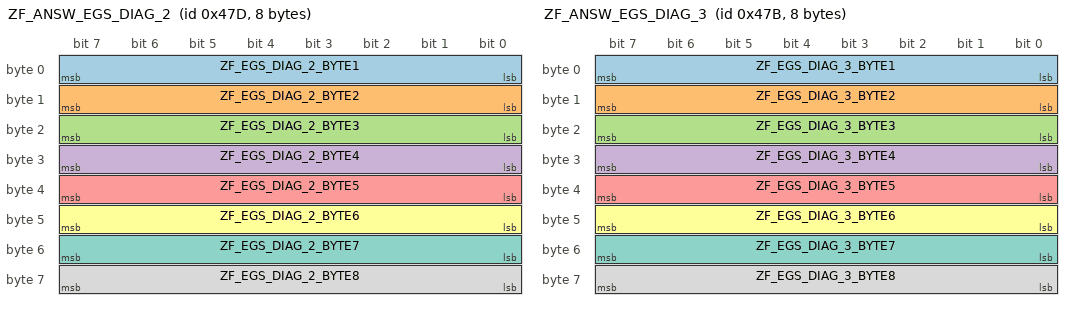
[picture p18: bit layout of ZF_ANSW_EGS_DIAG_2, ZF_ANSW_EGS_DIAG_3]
BO_ 1149 ZF_ANSW_EGS_DIAG_2: 8 DME1
 SG_ ZF_EGS_DIAG_2_BYTE1 : 0|8@1+ (1,0) [0|255] "This unit fulfills the required AUTOSAR reference to a unit. No real unit is defined." ZGW
 SG_ ZF_EGS_DIAG_2_BYTE2 : 8|8@1+ (1,0) [0|255] "This unit fulfills the required AUTOSAR reference to a unit. No real unit is defined." ZGW
 SG_ ZF_EGS_DIAG_2_BYTE3 : 16|8@1+ (1,0) [0|255] "This unit fulfills the required AUTOSAR reference to a unit. No real unit is defined." ZGW
 SG_ ZF_EGS_DIAG_2_BYTE4 : 24|8@1+ (1,0) [0|255] "This unit fulfills the required AUTOSAR reference to a unit. No real unit is defined." ZGW
 SG_ ZF_EGS_DIAG_2_BYTE5 : 32|8@1+ (1,0) [0|255] "This unit fulfills the required AUTOSAR reference to a unit. No real unit is defined." ZGW
 SG_ ZF_EGS_DIAG_2_BYTE6 : 40|8@1+ (1,0) [0|255] "This unit fulfills the required AUTOSAR reference to a unit. No real unit is defined." ZGW
 SG_ ZF_EGS_DIAG_2_BYTE7 : 48|8@1+ (1,0) [0|255] "This unit fulfills the required AUTOSAR reference to a unit. No real unit is defined." ZGW
 SG_ ZF_EGS_DIAG_2_BYTE8 : 56|8@1+ (1,0) [0|255] "This unit fulfills the required AUTOSAR reference to a unit. No real unit is defined." ZGW

BO_ 1147 ZF_ANSW_EGS_DIAG_3: 8 DME1
 SG_ ZF_EGS_DIAG_3_BYTE1 : 0|8@1+ (1,0) [0|255] "This unit fulfills the required AUTOSAR reference to a unit. No real unit is defined." ZGW
 SG_ ZF_EGS_DIAG_3_BYTE2 : 8|8@1+ (1,0) [0|255] "This unit fulfills the required AUTOSAR reference to a unit. No real unit is defined." ZGW
 SG_ ZF_EGS_DIAG_3_BYTE3 : 16|8@1+ (1,0) [0|255] "This unit fulfills the required AUTOSAR reference to a unit. No real unit is defined." ZGW
 SG_ ZF_EGS_DIAG_3_BYTE4 : 24|8@1+ (1,0) [0|255] "This unit fulfills the required AUTOSAR reference to a unit. No real unit is defined." ZGW
 SG_ ZF_EGS_DIAG_3_BYTE5 : 32|8@1+ (1,0) [0|255] "This unit fulfills the required AUTOSAR reference to a unit. No real unit is defined." ZGW
 SG_ ZF_EGS_DIAG_3_BYTE6 : 40|8@1+ (1,0) [0|255] "This unit fulfills the required AUTOSAR reference to a unit. No real unit is defined." ZGW
 SG_ ZF_EGS_DIAG_3_BYTE7 : 48|8@1+ (1,0) [0|255] "This unit fulfills the required AUTOSAR reference to a unit. No real unit is defined." ZGW
 SG_ ZF_EGS_DIAG_3_BYTE8 : 56|8@1+ (1,0) [0|255] "This unit fulfills the required AUTOSAR reference to a unit. No real unit is defined." ZGW

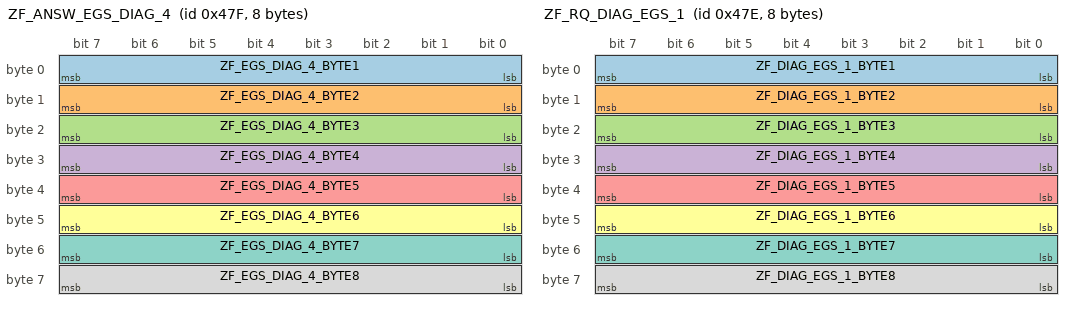
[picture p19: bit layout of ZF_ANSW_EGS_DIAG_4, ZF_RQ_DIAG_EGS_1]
BO_ 1151 ZF_ANSW_EGS_DIAG_4: 8 DME1
 SG_ ZF_EGS_DIAG_4_BYTE1 : 0|8@1+ (1,0) [0|255] "This unit fulfills the required AUTOSAR reference to a unit. No real unit is defined." ZGW
 SG_ ZF_EGS_DIAG_4_BYTE2 : 8|8@1+ (1,0) [0|255] "This unit fulfills the required AUTOSAR reference to a unit. No real unit is defined." ZGW
 SG_ ZF_EGS_DIAG_4_BYTE3 : 16|8@1+ (1,0) [0|255] "This unit fulfills the required AUTOSAR reference to a unit. No real unit is defined." ZGW
 SG_ ZF_EGS_DIAG_4_BYTE4 : 24|8@1+ (1,0) [0|255] "This unit fulfills the required AUTOSAR reference to a unit. No real unit is defined." ZGW
 SG_ ZF_EGS_DIAG_4_BYTE5 : 32|8@1+ (1,0) [0|255] "This unit fulfills the required AUTOSAR reference to a unit. No real unit is defined." ZGW
 SG_ ZF_EGS_DIAG_4_BYTE6 : 40|8@1+ (1,0) [0|255] "This unit fulfills the required AUTOSAR reference to a unit. No real unit is defined." ZGW
 SG_ ZF_EGS_DIAG_4_BYTE7 : 48|8@1+ (1,0) [0|255] "This unit fulfills the required AUTOSAR reference to a unit. No real unit is defined." ZGW
 SG_ ZF_EGS_DIAG_4_BYTE8 : 56|8@1+ (1,0) [0|255] "This unit fulfills the required AUTOSAR reference to a unit. No real unit is defined." ZGW

BO_ 1150 ZF_RQ_DIAG_EGS_1: 8 ZGW
 SG_ ZF_DIAG_EGS_1_BYTE1 : 0|8@1+ (1,0) [0|255] "This unit fulfills the required AUTOSAR reference to a unit. No real unit is defined." DME1
 SG_ ZF_DIAG_EGS_1_BYTE2 : 8|8@1+ (1,0) [0|255] "This unit fulfills the required AUTOSAR reference to a unit. No real unit is defined." DME1
 SG_ ZF_DIAG_EGS_1_BYTE3 : 16|8@1+ (1,0) [0|255] "This unit fulfills the required AUTOSAR reference to a unit. No real unit is defined." DME1
 SG_ ZF_DIAG_EGS_1_BYTE4 : 24|8@1+ (1,0) [0|255] "This unit fulfills the required AUTOSAR reference to a unit. No real unit is defined." DME1
 SG_ ZF_DIAG_EGS_1_BYTE5 : 32|8@1+ (1,0) [0|255] "This unit fulfills the required AUTOSAR reference to a unit. No real unit is defined." DME1
 SG_ ZF_DIAG_EGS_1_BYTE6 : 40|8@1+ (1,0) [0|255] "This unit fulfills the required AUTOSAR reference to a unit. No real unit is defined." DME1
 SG_ ZF_DIAG_EGS_1_BYTE7 : 48|8@1+ (1,0) [0|255] "This unit fulfills the required AUTOSAR reference to a unit. No real unit is defined." DME1
 SG_ ZF_DIAG_EGS_1_BYTE8 : 56|8@1+ (1,0) [0|255] "This unit fulfills the required AUTOSAR reference to a unit. No real unit is defined." DME1

BO_TX_BU_ 1050 : Kombi,Kombi_Basis;
BO_TX_BU_ 1013 : Kombi,Kombi_Basis;
BO_TX_BU_ 889 : Kombi,Kombi_Basis;
BO_TX_BU_ 975 : Kombi,Kombi_Basis;
BO_TX_BU_ 750 : Kombi,Kombi_Basis;
BO_TX_BU_ 760 : Kombi,Kombi_Basis;
BO_TX_BU_ 826 : Kombi,Kombi_Basis;
BO_TX_BU_ 772 : DME1,ZGW;
BO_TX_BU_ 1037 : Kombi,Kombi_Basis;
CM_ BO_ 737  "�bermittlung Benutzereinstellungen intelligentes Laden von HU an HvPM
==========
Transmission of user settings for Intelligent Charging from HU to HvPM";
CM_ BO_ 646  "Diese Schnittstelle wurde f�r die Funktion Intelligentes Laden 2.0 (mit PLC) eingef�hrt und wird in SP2015 nicht applikativ umgesetzt. Die Signale d�rfen in SP2015 nicht ausgewertet werden, da Signalinhalt nicht korrekt durch Sender bef�llt.
(Gilt f�r alle Signale der PDU)";
CM_ BO_ 826  "Mit der Nachricht wird die UTC-Zeit verteilt. Diese Zeit ist nicht f�r Anzeige bestimmt. Je nach Verf�gbarkeit der UTC-Signale kann es vorkommen, dass mit dieser Nachricht die lokale Werkszeit oder die vom Kunden eingestellte Zeit verteilt wird.
==========
The UTC time is distributed with the message. This time is not intended for display. Depending on the availability of the UTC signals, the local working time or the time set by the customer can be distributed with this message.";
CM_ BO_ 1985  "XCP-Dummyframe f�r die Kommunikation vom IFM zum Master
==========
XCP dummy frame for communication from IFM to master";
CM_ BO_ 1986  "XCP-Dummyframe f�r die Kommunikation vom IFM zum Master
==========
XCP dummy frame for communication from IFM to master";
CM_ BO_ 1987  "XCP-Dummyframe f�r die Kommunikation vom IFM zum Master
==========
XCP dummy frame for communication from IFM to master";
CM_ BO_ 1974  "XCP-Dummyframe f�r die Kommunikation vom Master zum IFM
==========
XCP dummy frame for communication from the master to IFM";
CM_ BO_ 1984  "XCP-Dummyframe f�r die Kommunikation vom IFM zum Master
==========
XCP dummy frame for communication from IFM to master";

BA_DEF_ BO_ "FrameTriggeringName" STRING;
BA_DEF_ BO_ "GenMsgCycleTime" INT 0 65535;
BA_DEF_ BO_ "GenMsgDelayTime" INT 0 65535;
BA_DEF_ BO_ "GenMsgSendType" ENUM  "cyclicX","spontanX","cyclicIfActiveX","spontanWithDelay","cyclicAndSpontanX","cyclicAndSpontanWithDelay","spontanWithRepitition","cyclicIfActiveAndSpontanWD","cyclicIfActiveFast","cyclicWithRepeatOnDemand","none";
BA_DEF_ BO_ "GenMsgStartValue" STRING;
BA_DEF_ BO_ "PduName" STRING;
BA_DEF_ BO_ "SystemMessageLongSymbol" STRING;
BA_DEF_ SG_ "CompuMethodName" STRING;
BA_DEF_ SG_ "GenSigStartValue" FLOAT 0 100000000000;
BA_DEF_ SG_ "ISignalName" STRING;
BA_DEF_ SG_ "LongName" STRING;
BA_DEF_ SG_ "SysSignalName" STRING;
BA_DEF_ SG_ "SystemSignalLongSymbol" STRING;
BA_ "FrameTriggeringName" BO_ 888 "frTrig_CAN_963411742_888_963393850_963411732_963424759_FA_CAN";
BA_ "GenMsgCycleTime" BO_ 888 500;
BA_ "GenMsgDelayTime" BO_ 888 50;
BA_ "GenMsgSendType" BO_ 888 4;
BA_ "GenMsgStartValue" BO_ 888 "0080000080000000";
BA_ "PduName" BO_ 888 "ST_PMA";
BA_ "FrameTriggeringName" BO_ 1159 "frTrig_CAN_963411872_1159_963389560_963411732_963424759_FA_CAN";
BA_ "GenMsgCycleTime" BO_ 1159 5000;
BA_ "GenMsgDelayTime" BO_ 1159 100;
BA_ "GenMsgSendType" BO_ 1159 4;
BA_ "GenMsgStartValue" BO_ 1159 "0000";
BA_ "PduName" BO_ 1159 "ST_PWF_CKM";
BA_ "FrameTriggeringName" BO_ 669 "frTrig_CAN_963412065_669_963391417_963411732_963424759_FA_CAN";
BA_ "GenMsgCycleTime" BO_ 669 100;
BA_ "GenMsgDelayTime" BO_ 669 100;
BA_ "GenMsgSendType" BO_ 669 4;
BA_ "GenMsgStartValue" BO_ 669 "0000000000000000";
BA_ "PduName" BO_ 669 "ST_RCP";
BA_ "FrameTriggeringName" BO_ 233 "frTrig_CAN_963411882_233_963402808_963411732_963424759_FA_CAN";
BA_ "GenMsgCycleTime" BO_ 233 20;
BA_ "GenMsgSendType" BO_ 233 0;
BA_ "GenMsgStartValue" BO_ 233 "00000000c409";
BA_ "PduName" BO_ 233 "ST_REPAT_XTRQ_FTAX_BAX";
BA_ "FrameTriggeringName" BO_ 924 "frTrig_CAN_963411913_924_963389563_963411732_963424759_FA_CAN";
BA_ "GenMsgDelayTime" BO_ 924 100;
BA_ "GenMsgSendType" BO_ 924 1;
BA_ "GenMsgStartValue" BO_ 924 "0000000000000000";
BA_ "PduName" BO_ 924 "ST_RLS_ENGSTA_CARS";
BA_ "FrameTriggeringName" BO_ 767 "frTrig_CAN_963411972_767_963391131_963411732_963424759_FA_CAN";
BA_ "GenMsgCycleTime" BO_ 767 5000;
BA_ "GenMsgDelayTime" BO_ 767 100;
BA_ "GenMsgSendType" BO_ 767 4;
BA_ "GenMsgStartValue" BO_ 767 "0000";
BA_ "PduName" BO_ 767 "ST_RN_MONI_SHD";
BA_ "FrameTriggeringName" BO_ 619 "frTrig_CAN_963412137_619_963402600_963411732_963424759_FA_CAN";
BA_ "GenMsgCycleTime" BO_ 619 250;
BA_ "GenMsgDelayTime" BO_ 619 50;
BA_ "GenMsgSendType" BO_ 619 4;
BA_ "GenMsgStartValue" BO_ 619 "0000008000000080";
BA_ "PduName" BO_ 619 "ST_RSP_BN2020";
BA_ "FrameTriggeringName" BO_ 544 "frTrig_CAN_963411754_544_963403189_963411732_963424759_FA_CAN";
BA_ "GenMsgCycleTime" BO_ 544 1000;
BA_ "GenMsgDelayTime" BO_ 544 100;
BA_ "GenMsgSendType" BO_ 544 4;
BA_ "GenMsgStartValue" BO_ 544 "0000008000000080";
BA_ "PduName" BO_ 544 "ST_RSU_CON";
BA_ "FrameTriggeringName" BO_ 1101 "frTrig_CAN_963411933_1101_963395958_963411732_963424759_FA_CAN";
BA_ "GenMsgCycleTime" BO_ 1101 1000;
BA_ "GenMsgDelayTime" BO_ 1101 100;
BA_ "GenMsgSendType" BO_ 1101 4;
BA_ "GenMsgStartValue" BO_ 1101 "0000008000000080";
BA_ "PduName" BO_ 1101 "ST_RSU_MST";
BA_ "FrameTriggeringName" BO_ 1054 "frTrig_CAN_963411969_1054_963401109_963411732_963424759_FA_CAN";
BA_ "GenMsgSendType" BO_ 1054 1;
BA_ "GenMsgStartValue" BO_ 1054 "0000000000000000";
BA_ "PduName" BO_ 1054 "ST_SCHRG";
BA_ "FrameTriggeringName" BO_ 693 "frTrig_CAN_963411782_693_963391189_963411732_963424759_FA_CAN";
BA_ "GenMsgCycleTime" BO_ 693 1000;
BA_ "GenMsgDelayTime" BO_ 693 40;
BA_ "GenMsgSendType" BO_ 693 4;
BA_ "GenMsgStartValue" BO_ 693 "0000000000000080";
BA_ "PduName" BO_ 693 "ST_SSFN_DSC";
BA_ "FrameTriggeringName" BO_ 371 "frTrig_CAN_963412083_371_963400653_963411732_963424759_FA_CAN";
BA_ "GenMsgCycleTime" BO_ 371 50;
BA_ "GenMsgDelayTime" BO_ 371 10;
BA_ "GenMsgSendType" BO_ 371 4;
BA_ "GenMsgStartValue" BO_ 371 "0000000000000000";
BA_ "PduName" BO_ 371 "ST_STAB_DSC";
BA_ "FrameTriggeringName" BO_ 1050 "frTrig_CAN_963411934_1050_963403059_963411732_963424759_FA_CAN";
BA_ "GenMsgCycleTime" BO_ 1050 5000;
BA_ "GenMsgDelayTime" BO_ 1050 200;
BA_ "GenMsgSendType" BO_ 1050 4;
BA_ "GenMsgStartValue" BO_ 1050 "0000000000000000";
BA_ "PduName" BO_ 1050 "ST_SU_KI_4";
BA_ "FrameTriggeringName" BO_ 1013 "frTrig_CAN_963412039_1013_963399079_963411732_963424759_FA_CAN";
BA_ "GenMsgCycleTime" BO_ 1013 5000;
BA_ "GenMsgDelayTime" BO_ 1013 200;
BA_ "GenMsgSendType" BO_ 1013 4;
BA_ "GenMsgStartValue" BO_ 1013 "0000000000000000";
BA_ "PduName" BO_ 1013 "ST_SU_KI_5";
BA_ "FrameTriggeringName" BO_ 873 "frTrig_CAN_963412162_873_963402771_963411732_963424759_FA_CAN";
BA_ "GenMsgCycleTime" BO_ 873 5000;
BA_ "GenMsgDelayTime" BO_ 873 200;
BA_ "GenMsgSendType" BO_ 873 4;
BA_ "GenMsgStartValue" BO_ 873 "0080000000";
BA_ "PduName" BO_ 873 "ST_TYR";
BA_ "FrameTriggeringName" BO_ 905 "frTrig_CAN_963411936_905_963394239_963411732_963424759_FA_CAN";
BA_ "GenMsgCycleTime" BO_ 905 1000;
BA_ "GenMsgDelayTime" BO_ 905 200;
BA_ "GenMsgSendType" BO_ 905 4;
BA_ "GenMsgStartValue" BO_ 905 "00000000";
BA_ "PduName" BO_ 905 "ST_VA_HVBTC";
BA_ "FrameTriggeringName" BO_ 895 "frTrig_CAN_963412139_895_963402831_963411732_963424759_FA_CAN";
BA_ "GenMsgCycleTime" BO_ 895 200;
BA_ "GenMsgSendType" BO_ 895 0;
BA_ "GenMsgStartValue" BO_ 895 "0000";
BA_ "PduName" BO_ 895 "ST_VEH_TONE";
BA_ "FrameTriggeringName" BO_ 838 "frTrig_CAN_963411939_838_963389155_963411732_963424759_FA_CAN";
BA_ "GenMsgCycleTime" BO_ 838 500;
BA_ "GenMsgDelayTime" BO_ 838 100;
BA_ "GenMsgSendType" BO_ 838 4;
BA_ "GenMsgStartValue" BO_ 838 "00000080";
BA_ "PduName" BO_ 838 "ST_VIB_STW";
BA_ "FrameTriggeringName" BO_ 271 "frTrig_CAN_963412147_271_963396221_963411732_963424759_FA_CAN";
BA_ "GenMsgCycleTime" BO_ 271 20;
BA_ "GenMsgSendType" BO_ 271 0;
BA_ "GenMsgStartValue" BO_ 271 "0000000000000000";
BA_ "PduName" BO_ 271 "ST_WBK";
BA_ "FrameTriggeringName" BO_ 889 "frTrig_CAN_963412049_889_963389575_963411732_963424759_FA_CAN";
BA_ "GenMsgCycleTime" BO_ 889 1000;
BA_ "GenMsgDelayTime" BO_ 889 200;
BA_ "GenMsgSendType" BO_ 889 4;
BA_ "GenMsgStartValue" BO_ 889 "0001";
BA_ "PduName" BO_ 889 "SU_CLE_DISP_DXP";
BA_ "FrameTriggeringName" BO_ 804 "frTrig_CAN_963411980_804_963405673_963411732_963424759_FA_CAN";
BA_ "GenMsgCycleTime" BO_ 804 1000;
BA_ "GenMsgDelayTime" BO_ 804 200;
BA_ "GenMsgSendType" BO_ 804 4;
BA_ "GenMsgStartValue" BO_ 804 "00000000";
BA_ "PduName" BO_ 804 "SU_CLE_DRV_DXP";
BA_ "FrameTriggeringName" BO_ 975 "frTrig_CAN_963412025_975_963401206_963411732_963424759_FA_CAN";
BA_ "GenMsgCycleTime" BO_ 975 5000;
BA_ "GenMsgDelayTime" BO_ 975 200;
BA_ "GenMsgSendType" BO_ 975 4;
BA_ "GenMsgStartValue" BO_ 975 "0000000000000000";
BA_ "PduName" BO_ 975 "SU_HUD";
BA_ "FrameTriggeringName" BO_ 1028 "frTrig_CAN_963412145_1028_963391840_963411732_963424759_FA_CAN";
BA_ "GenMsgDelayTime" BO_ 1028 200;
BA_ "GenMsgSendType" BO_ 1028 1;
BA_ "GenMsgStartValue" BO_ 1028 "0000000000000000";
BA_ "PduName" BO_ 1028 "SU_MDRV_3";
BA_ "FrameTriggeringName" BO_ 1049 "frTrig_CAN_963411857_1049_963391766_963411732_963424759_FA_CAN";
BA_ "GenMsgDelayTime" BO_ 1049 200;
BA_ "GenMsgSendType" BO_ 1049 1;
BA_ "GenMsgStartValue" BO_ 1049 "0000";
BA_ "PduName" BO_ 1049 "SU_PWF_CKM";
BA_ "FrameTriggeringName" BO_ 737 "frTrig_CAN_963411788_737_963389421_963411732_963424759_FA_CAN";
BA_ "GenMsgSendType" BO_ 737 1;
BA_ "GenMsgStartValue" BO_ 737 "0000000000000000";
BA_ "PduName" BO_ 737 "SU_SCHRG";
BA_ "FrameTriggeringName" BO_ 646 "frTrig_CAN_963412080_646_963399090_963411732_963424759_FA_CAN";
BA_ "GenMsgSendType" BO_ 646 1;
BA_ "GenMsgStartValue" BO_ 646 "0000000000000000";
BA_ "PduName" BO_ 646 "SU_SCHRG_CERT";
BA_ "FrameTriggeringName" BO_ 717 "frTrig_CAN_963411786_717_963389417_963411732_963424759_FA_CAN";
BA_ "GenMsgDelayTime" BO_ 717 100;
BA_ "GenMsgSendType" BO_ 717 1;
BA_ "GenMsgStartValue" BO_ 717 "0000";
BA_ "PduName" BO_ 717 "SU_SCHRG_KEY";
BA_ "FrameTriggeringName" BO_ 692 "frTrig_CAN_963411957_692_963398922_963411732_963424759_FA_CAN";
BA_ "GenMsgDelayTime" BO_ 692 100;
BA_ "GenMsgSendType" BO_ 692 1;
BA_ "GenMsgStartValue" BO_ 692 "0000000000";
BA_ "PduName" BO_ 692 "SU_SCHRG_REM";
BA_ "FrameTriggeringName" BO_ 848 "frTrig_CAN_963411898_848_963405202_963411732_963424759_FA_CAN";
BA_ "GenMsgCycleTime" BO_ 848 1000;
BA_ "GenMsgDelayTime" BO_ 848 20;
BA_ "GenMsgSendType" BO_ 848 4;
BA_ "GenMsgStartValue" BO_ 848 "0000000000000000";
BA_ "PduName" BO_ 848 "SU_SOC_HLD";
BA_ "FrameTriggeringName" BO_ 776 "frTrig_CAN_963412074_776_963400881_963411732_963424759_FA_CAN";
BA_ "GenMsgCycleTime" BO_ 776 1000;
BA_ "GenMsgDelayTime" BO_ 776 40;
BA_ "GenMsgSendType" BO_ 776 4;
BA_ "GenMsgStartValue" BO_ 776 "0000000000000000";
BA_ "PduName" BO_ 776 "SYS_ST_EVEH_DRV";
BA_ "FrameTriggeringName" BO_ 129 "frTrig_CAN_963412041_129_963399082_963411732_963424759_FA_CAN";
BA_ "GenMsgDelayTime" BO_ 129 5;
BA_ "GenMsgSendType" BO_ 129 1;
BA_ "GenMsgStartValue" BO_ 129 "0000000000000000";
BA_ "PduName" BO_ 129 "SecurityStatus";
BA_ "FrameTriggeringName" BO_ 309 "frTrig_CAN_963412121_309_963401225_963411732_963424759_FA_CAN";
BA_ "GenMsgCycleTime" BO_ 309 1000;
BA_ "GenMsgDelayTime" BO_ 309 10;
BA_ "GenMsgSendType" BO_ 309 4;
BA_ "GenMsgStartValue" BO_ 309 "00";
BA_ "PduName" BO_ 309 "SenderEgsToExternal1000msES";
BA_ "FrameTriggeringName" BO_ 750 "frTrig_CAN_963411886_750_963396213_963411732_963424759_FA_CAN";
BA_ "GenMsgDelayTime" BO_ 750 50;
BA_ "GenMsgSendType" BO_ 750 1;
BA_ "GenMsgStartValue" BO_ 750 "0000000000000000";
BA_ "PduName" BO_ 750 "ServiceBrake";
BA_ "FrameTriggeringName" BO_ 347 "frTrig_CAN_963412029_347_963393537_963411732_963424759_FA_CAN";
BA_ "GenMsgCycleTime" BO_ 347 10000;
BA_ "GenMsgDelayTime" BO_ 347 100;
BA_ "GenMsgSendType" BO_ 347 4;
BA_ "GenMsgStartValue" BO_ 347 "0000000000000000";
BA_ "PduName" BO_ 347 "StatusAlcoholInterlockDevice";
BA_ "FrameTriggeringName" BO_ 1106 "frTrig_CAN_963411905_1106_963403362_963411732_963424759_FA_CAN";
BA_ "GenMsgCycleTime" BO_ 1106 1000;
BA_ "GenMsgSendType" BO_ 1106 0;
BA_ "GenMsgStartValue" BO_ 1106 "0000";
BA_ "PduName" BO_ 1106 "StatusCoolantLevel";
BA_ "FrameTriggeringName" BO_ 1196 "frTrig_CAN_963412108_1196_963398929_963411732_963424759_FA_CAN";
BA_ "GenMsgCycleTime" BO_ 1196 1000;
BA_ "GenMsgSendType" BO_ 1196 0;
BA_ "GenMsgStartValue" BO_ 1196 "0000";
BA_ "PduName" BO_ 1196 "StatusDiagnosisEtxvCCU";
BA_ "FrameTriggeringName" BO_ 1095 "frTrig_CAN_963411821_1095_963389434_963411732_963424759_FA_CAN";
BA_ "GenMsgDelayTime" BO_ 1095 200;
BA_ "GenMsgSendType" BO_ 1095 1;
BA_ "GenMsgStartValue" BO_ 1095 "0000000000000000";
BA_ "PduName" BO_ 1095 "StatusKeyAction";
BA_ "FrameTriggeringName" BO_ 702 "frTrig_CAN_963412172_702_963389592_963411732_963424759_FA_CAN";
BA_ "GenMsgDelayTime" BO_ 702 100;
BA_ "GenMsgSendType" BO_ 702 1;
BA_ "GenMsgStartValue" BO_ 702 "0000000000000000";
BA_ "PduName" BO_ 702 "StatusPowertrainErrorSourceInformation";
BA_ "SystemMessageLongSymbol" BO_ 702 "StatusPowertrainErrorSourceInformation";
BA_ "FrameTriggeringName" BO_ 1197 "frTrig_CAN_963412109_1197_963396547_963411732_963424759_FA_CAN";
BA_ "GenMsgCycleTime" BO_ 1197 1000;
BA_ "GenMsgSendType" BO_ 1197 0;
BA_ "GenMsgStartValue" BO_ 1197 "000000505050d803";
BA_ "PduName" BO_ 1197 "StatusTemperatureAndDiagnosisFunctionalHVS1";
BA_ "SystemMessageLongSymbol" BO_ 1197 "StatusTemperatureAndDiagnosisFunctionalHVS1";
BA_ "FrameTriggeringName" BO_ 1194 "frTrig_CAN_963412110_1194_963398925_963411732_963424759_FA_CAN";
BA_ "GenMsgCycleTime" BO_ 1194 1000;
BA_ "GenMsgSendType" BO_ 1194 0;
BA_ "GenMsgStartValue" BO_ 1194 "000000505050d803";
BA_ "PduName" BO_ 1194 "StatusTemperatureAndDiagnosisFunctionalHVS2";
BA_ "SystemMessageLongSymbol" BO_ 1194 "StatusTemperatureAndDiagnosisFunctionalHVS2";
BA_ "FrameTriggeringName" BO_ 883 "frTrig_CAN_963412157_883_963389463_963411732_963424759_FA_CAN";
BA_ "GenMsgCycleTime" BO_ 883 1000;
BA_ "GenMsgDelayTime" BO_ 883 200;
BA_ "GenMsgSendType" BO_ 883 4;
BA_ "GenMsgStartValue" BO_ 883 "000000000000";
BA_ "PduName" BO_ 883 "TAC_RNG";
BA_ "FrameTriggeringName" BO_ 858 "frTrig_CAN_963412033_858_963391956_963411732_963424759_FA_CAN";
BA_ "GenMsgDelayTime" BO_ 858 100;
BA_ "GenMsgSendType" BO_ 858 1;
BA_ "GenMsgStartValue" BO_ 858 "00000101";
BA_ "PduName" BO_ 858 "TERMIN_CBS";
BA_ "FrameTriggeringName" BO_ 355 "frTrig_CAN_963411986_355_963388941_963411732_963424759_FA_CAN";
BA_ "GenMsgCycleTime" BO_ 355 100;
BA_ "GenMsgSendType" BO_ 355 0;
BA_ "GenMsgStartValue" BO_ 355 "0080c00fc00fc08f";
BA_ "PduName" BO_ 355 "TLT_RW";
BA_ "FrameTriggeringName" BO_ 165 "frTrig_CAN_963412169_165_963393483_963411732_963424759_FA_CAN";
BA_ "GenMsgCycleTime" BO_ 165 10;
BA_ "GenMsgSendType" BO_ 165 0;
BA_ "GenMsgStartValue" BO_ 165 "0000000cc0000000";
BA_ "PduName" BO_ 165 "TORQ_CRSH_1";
BA_ "FrameTriggeringName" BO_ 194 "frTrig_CAN_963412062_194_963401009_963411732_963424759_FA_CAN";
BA_ "GenMsgCycleTime" BO_ 194 20;
BA_ "GenMsgSendType" BO_ 194 0;
BA_ "GenMsgStartValue" BO_ 194 "00008403f4000000";
BA_ "PduName" BO_ 194 "TORQ_CRSH_4";
BA_ "FrameTriggeringName" BO_ 760 "frTrig_CAN_963412007_760_963391212_963411732_963424759_FA_CAN";
BA_ "GenMsgCycleTime" BO_ 760 5000;
BA_ "GenMsgDelayTime" BO_ 760 200;
BA_ "GenMsgSendType" BO_ 760 4;
BA_ "GenMsgStartValue" BO_ 760 "0000000110010000";
BA_ "PduName" BO_ 760 "UHRZEIT_DATUM";
BA_ "FrameTriggeringName" BO_ 826 "frTrig_CAN_963412089_826_963396538_963411732_963424759_FA_CAN";
BA_ "GenMsgDelayTime" BO_ 826 200;
BA_ "GenMsgSendType" BO_ 826 1;
BA_ "GenMsgStartValue" BO_ 826 "000000011001ec0d";
BA_ "PduName" BO_ 826 "UHRZEIT_DATUM_UTC";
BA_ "FrameTriggeringName" BO_ 772 "frTrig_CAN_963411777_772_963405065_963411732_963424759_FA_CAN";
BA_ "GenMsgCycleTime" BO_ 772 200;
BA_ "GenMsgSendType" BO_ 772 0;
BA_ "GenMsgStartValue" BO_ 772 "000000000000";
BA_ "PduName" BO_ 772 "U_BN";
BA_ "FrameTriggeringName" BO_ 415 "frTrig_CAN_963412044_415_963396138_963411732_963424759_FA_CAN";
BA_ "GenMsgCycleTime" BO_ 415 20;
BA_ "GenMsgSendType" BO_ 415 0;
BA_ "GenMsgStartValue" BO_ 415 "00805cff0000";
BA_ "PduName" BO_ 415 "VYAW_VEH";
BA_ "FrameTriggeringName" BO_ 417 "frTrig_CAN_963411917_417_963400649_963411732_963424759_FA_CAN";
BA_ "GenMsgCycleTime" BO_ 417 20;
BA_ "GenMsgSendType" BO_ 417 0;
BA_ "GenMsgStartValue" BO_ 417 "0000000080";
BA_ "PduName" BO_ 417 "V_VEH";
BA_ "FrameTriggeringName" BO_ 373 "frTrig_CAN_963411867_373_963388859_963411732_963424759_FA_CAN";
BA_ "GenMsgCycleTime" BO_ 373 1000;
BA_ "GenMsgSendType" BO_ 373 0;
BA_ "GenMsgStartValue" BO_ 373 "0080008000000800";
BA_ "PduName" BO_ 373 "V_VEH_2";
BA_ "FrameTriggeringName" BO_ 1037 "frTrig_CAN_963411908_1037_963399060_963411732_963424759_FA_CAN";
BA_ "GenMsgCycleTime" BO_ 1037 1000;
BA_ "GenMsgDelayTime" BO_ 1037 200;
BA_ "GenMsgSendType" BO_ 1037 4;
BA_ "GenMsgStartValue" BO_ 1037 "0000000000000000";
BA_ "PduName" BO_ 1037 "WEL_STAG";
BA_ "FrameTriggeringName" BO_ 550 "frTrig_CAN_963411848_550_963398371_963411732_963424759_FA_CAN";
BA_ "GenMsgCycleTime" BO_ 550 8000;
BA_ "GenMsgDelayTime" BO_ 550 100;
BA_ "GenMsgSendType" BO_ 550 4;
BA_ "GenMsgStartValue" BO_ 550 "0000000300";
BA_ "PduName" BO_ 550 "WISCHERGESCHWINDIGKEIT";
BA_ "FrameTriggeringName" BO_ 143 "frTrig_CAN_963412032_143_963398936_963411732_963424759_FA_CAN";
BA_ "GenMsgCycleTime" BO_ 143 40;
BA_ "GenMsgSendType" BO_ 143 0;
BA_ "GenMsgStartValue" BO_ 143 "0000007d00000000";
BA_ "PduName" BO_ 143 "WMOM_DRV_1";
BA_ "FrameTriggeringName" BO_ 220 "frTrig_CAN_963411746_220_963391425_963411732_963424759_FA_CAN";
BA_ "GenMsgCycleTime" BO_ 220 20;
BA_ "GenMsgSendType" BO_ 220 0;
BA_ "GenMsgStartValue" BO_ 220 "000000d00700";
BA_ "PduName" BO_ 220 "WMOM_DRV_4";
BA_ "FrameTriggeringName" BO_ 1985 "frTrig_CAN_963411756_1985_963396385_963411732_963424759_FA_CAN";
BA_ "GenMsgDelayTime" BO_ 1985 10;
BA_ "GenMsgSendType" BO_ 1985 1;
BA_ "GenMsgStartValue" BO_ 1985 "0000000000000000";
BA_ "PduName" BO_ 1985 "XCPIFMDAQ1";
BA_ "FrameTriggeringName" BO_ 1986 "frTrig_CAN_963411757_1986_963389324_963411732_963424759_FA_CAN";
BA_ "GenMsgDelayTime" BO_ 1986 10;
BA_ "GenMsgSendType" BO_ 1986 1;
BA_ "GenMsgStartValue" BO_ 1986 "0000000000000000";
BA_ "PduName" BO_ 1986 "XCPIFMDAQ2";
BA_ "FrameTriggeringName" BO_ 1987 "frTrig_CAN_963411758_1987_963391662_963411732_963424759_FA_CAN";
BA_ "GenMsgDelayTime" BO_ 1987 10;
BA_ "GenMsgSendType" BO_ 1987 1;
BA_ "GenMsgStartValue" BO_ 1987 "0000000000000000";
BA_ "PduName" BO_ 1987 "XCPIFMDAQ3";
BA_ "FrameTriggeringName" BO_ 1974 "frTrig_CAN_963411759_1974_963398778_963411732_963424759_FA_CAN";
BA_ "GenMsgDelayTime" BO_ 1974 10;
BA_ "GenMsgSendType" BO_ 1974 1;
BA_ "GenMsgStartValue" BO_ 1974 "0000000000000000";
BA_ "PduName" BO_ 1974 "XCPIFMRequest";
BA_ "FrameTriggeringName" BO_ 1984 "frTrig_CAN_963411760_1984_963403109_963411732_963424759_FA_CAN";
BA_ "GenMsgDelayTime" BO_ 1984 10;
BA_ "GenMsgSendType" BO_ 1984 1;
BA_ "GenMsgStartValue" BO_ 1984 "0000000000000000";
BA_ "PduName" BO_ 1984 "XCPIFMResponse";
BA_ "FrameTriggeringName" BO_ 1148 "frTrig_CAN_963412002_1148_963396398_963411732_963424759_FA_CAN";
BA_ "GenMsgDelayTime" BO_ 1148 10;
BA_ "GenMsgSendType" BO_ 1148 1;
BA_ "GenMsgStartValue" BO_ 1148 "0000000000000000";
BA_ "PduName" BO_ 1148 "ZF_ANSW_EGS_DIAG_1";
BA_ "FrameTriggeringName" BO_ 1149 "frTrig_CAN_963412090_1149_963403127_963411732_963424759_FA_CAN";
BA_ "GenMsgDelayTime" BO_ 1149 10;
BA_ "GenMsgSendType" BO_ 1149 1;
BA_ "GenMsgStartValue" BO_ 1149 "0000000000000000";
BA_ "PduName" BO_ 1149 "ZF_ANSW_EGS_DIAG_2";
BA_ "FrameTriggeringName" BO_ 1147 "frTrig_CAN_963411824_1147_963401025_963411732_963424759_FA_CAN";
BA_ "GenMsgDelayTime" BO_ 1147 10;
BA_ "GenMsgSendType" BO_ 1147 1;
BA_ "GenMsgStartValue" BO_ 1147 "0000000000000000";
BA_ "PduName" BO_ 1147 "ZF_ANSW_EGS_DIAG_3";
BA_ "FrameTriggeringName" BO_ 1151 "frTrig_CAN_963412012_1151_963403123_963411732_963424759_FA_CAN";
BA_ "GenMsgDelayTime" BO_ 1151 10;
BA_ "GenMsgSendType" BO_ 1151 1;
BA_ "GenMsgStartValue" BO_ 1151 "0000000000000000";
BA_ "PduName" BO_ 1151 "ZF_ANSW_EGS_DIAG_4";
BA_ "FrameTriggeringName" BO_ 1150 "frTrig_CAN_963411893_1150_963389346_963411732_963424759_FA_CAN";
BA_ "GenMsgDelayTime" BO_ 1150 10;
BA_ "GenMsgSendType" BO_ 1150 1;
BA_ "GenMsgStartValue" BO_ 1150 "0000000000000000";
BA_ "PduName" BO_ 1150 "ZF_RQ_DIAG_EGS_1";
BA_ "CompuMethodName" SG_ 888 CRC_ST_PMA "CRC8";
BA_ "ISignalName" SG_ 888 CRC_ST_PMA "CRC_ST_PMA";
BA_ "LongName" SG_ 888 CRC_ST_PMA "CRC_Status_Parkassistent";
BA_ "SysSignalName" SG_ 888 CRC_ST_PMA "CRC_ST_PMA";
BA_ "CompuMethodName" SG_ 888 ALIV_ST_PMA "ALIV_COU_4";
BA_ "ISignalName" SG_ 888 ALIV_ST_PMA "ALIV_ST_PMA";
BA_ "LongName" SG_ 888 ALIV_ST_PMA "Alive_Status_Parkassistent";
BA_ "SysSignalName" SG_ 888 ALIV_ST_PMA "ALIV_ST_PMA";
BA_ "ISignalName" SG_ 888 ST_PMA_dummy_12_15 "ST_PMA_dummy_12_15";
BA_ "LongName" SG_ 888 ST_PMA_dummy_12_15 "ST_PMA_dummy_12_15";
BA_ "SysSignalName" SG_ 888 ST_PMA_dummy_12_15 "ST_PMA_dummy_12_15";
BA_ "CompuMethodName" SG_ 888 QU_FN_PMA "QU_FN_PMA";
BA_ "ISignalName" SG_ 888 QU_FN_PMA "QU_FN_PMA";
BA_ "LongName" SG_ 888 QU_FN_PMA "Qualifier_Funktion_Parkassistent";
BA_ "SysSignalName" SG_ 888 QU_FN_PMA "QU_FN_PMA";
BA_ "CompuMethodName" SG_ 888 QU_FN_PMA_POU "QU_FN_PMA_POU";
BA_ "ISignalName" SG_ 888 QU_FN_PMA_POU "QU_FN_PMA_POU";
BA_ "LongName" SG_ 888 QU_FN_PMA_POU "Qualifier_Funktion_Parkassistent_Ausparken";
BA_ "SysSignalName" SG_ 888 QU_FN_PMA_POU "QU_FN_PMA_POU";
BA_ "CompuMethodName" SG_ 888 CTR_SUP_RSTG_DI_PMA "CTR_SUP_RSTG_DI_PMA";
BA_ "ISignalName" SG_ 888 CTR_SUP_RSTG_DI_PMA "CTR_SUP_RSTG_DI_PMA";
BA_ "LongName" SG_ 888 CTR_SUP_RSTG_DI_PMA "Steuerung_Unterdrückung_Rückstellung_Blinker_Parkassistent";
BA_ "SysSignalName" SG_ 888 CTR_SUP_RSTG_DI_PMA "CTR_SUP_RSTG_DI_PMA";
BA_ "ISignalName" SG_ 888 ST_PMA_dummy_34_39 "ST_PMA_dummy_34_39";
BA_ "LongName" SG_ 888 ST_PMA_dummy_34_39 "ST_PMA_dummy_34_39";
BA_ "SysSignalName" SG_ 888 ST_PMA_dummy_34_39 "ST_PMA_dummy_34_39";
BA_ "CompuMethodName" SG_ 888 QU_FN_RVAS "QU_FN_RVAS";
BA_ "ISignalName" SG_ 888 QU_FN_RVAS "QU_FN_RVAS";
BA_ "LongName" SG_ 888 QU_FN_RVAS "Qualifier_Funktion_Rueckfahrassistent";
BA_ "SysSignalName" SG_ 888 QU_FN_RVAS "QU_FN_RVAS";
BA_ "CompuMethodName" SG_ 888 QU_FN_TRAS "QU_FN_TRAS";
BA_ "ISignalName" SG_ 888 QU_FN_TRAS "QU_FN_TRAS";
BA_ "LongName" SG_ 888 QU_FN_TRAS "Qualifier_Funktion_Anhängerassistent";
BA_ "SysSignalName" SG_ 888 QU_FN_TRAS "QU_FN_TRAS";
BA_ "CompuMethodName" SG_ 888 QU_FN_LCL_FAS_PKG "QU_FN_LCL_FAS_PKG";
BA_ "ISignalName" SG_ 888 QU_FN_LCL_FAS_PKG "QU_FN_LCL_FAS_PKG";
BA_ "LongName" SG_ 888 QU_FN_LCL_FAS_PKG "Qualifier_Funktion_Lokal_Fahrerassistenz_Parken";
BA_ "SysSignalName" SG_ 888 QU_FN_LCL_FAS_PKG "QU_FN_LCL_FAS_PKG";
BA_ "CompuMethodName" SG_ 1159 ST_PWF_SWO_LVG_CKM "PWF_SWO_LVG_CKM";
BA_ "ISignalName" SG_ 1159 ST_PWF_SWO_LVG_CKM "ST_PWF_SWO_LVG_CKM";
BA_ "LongName" SG_ 1159 ST_PWF_SWO_LVG_CKM "Status_PWF_Abschaltung_Wohnen_CKM";
BA_ "SysSignalName" SG_ 1159 ST_PWF_SWO_LVG_CKM "ST_PWF_SWO_LVG_CKM";
BA_ "CompuMethodName" SG_ 669 RequestSBRandPreDriveCheck "RequestSBRandPreDriveCheck";
BA_ "ISignalName" SG_ 669 RequestSBRandPreDriveCheck "RequestSBRandPreDriveCheck";
BA_ "LongName" SG_ 669 RequestSBRandPreDriveCheck "RequestSBRandPreDriveCheck";
BA_ "SysSignalName" SG_ 669 RequestSBRandPreDriveCheck "RequestSBRandPreDriveCheck";
BA_ "CompuMethodName" SG_ 233 QU_SER_REPAT_XTRQ_FTAX_BAX_ACT "QU_SER_REPAT_XTRQ_FTAX_BAX_ACT";
BA_ "ISignalName" SG_ 233 QU_SER_REPAT_XTRQ_FTAX_BAX_ACT "QU_SER_REPAT_XTRQ_FTAX_BAX_ACT";
BA_ "LongName" SG_ 233 QU_SER_REPAT_XTRQ_FTAX_BAX_ACT "Qualifier_Service_Verteilung_Längsmoment_Vorderachse_Hinterachse_Stellglied";
BA_ "SysSignalName" SG_ 233 QU_SER_REPAT_XTRQ_FTAX_BAX_ACT "QU_SER_REPAT_XTRQ_FTAX_BAX_ACT";
BA_ "CompuMethodName" SG_ 233 QU_AVL_REPAT_XTRQ_FTAX_BAX "QU_AVL_REPAT_XTRQ_FTAX_BAX";
BA_ "ISignalName" SG_ 233 QU_AVL_REPAT_XTRQ_FTAX_BAX "QU_AVL_REPAT_XTRQ_FTAX_BAX";
BA_ "LongName" SG_ 233 QU_AVL_REPAT_XTRQ_FTAX_BAX "Qualifier_Ist_Verteilung_Längsmoment_Vorderachse_Hinterachse";
BA_ "SysSignalName" SG_ 233 QU_AVL_REPAT_XTRQ_FTAX_BAX "QU_AVL_REPAT_XTRQ_FTAX_BAX";
BA_ "CompuMethodName" SG_ 233 AVL_REPAT_XTRQ_FTAX_BAX "AVL_REPAT_TORQ_LN";
BA_ "GenSigStartValue" SG_ 233 AVL_REPAT_XTRQ_FTAX_BAX 2500;
BA_ "ISignalName" SG_ 233 AVL_REPAT_XTRQ_FTAX_BAX "AVL_REPAT_XTRQ_FTAX_BAX";
BA_ "LongName" SG_ 233 AVL_REPAT_XTRQ_FTAX_BAX "Ist_Verteilung_Längsmoment_Vorderachse_Hinterachse";
BA_ "SysSignalName" SG_ 233 AVL_REPAT_XTRQ_FTAX_BAX "AVL_REPAT_XTRQ_FTAX_BAX";
BA_ "CompuMethodName" SG_ 924 ST_RLS_ENGSTA_CARS "ST_RLS_ENGSTA_CARS";
BA_ "ISignalName" SG_ 924 ST_RLS_ENGSTA_CARS "ST_RLS_ENGSTA_CARS";
BA_ "LongName" SG_ 924 ST_RLS_ENGSTA_CARS "Status_Freigabe_Motorstart_CarSharing";
BA_ "SysSignalName" SG_ 924 ST_RLS_ENGSTA_CARS "ST_RLS_ENGSTA_CARS";
BA_ "CompuMethodName" SG_ 767 ST_MONI_RN "ST_MONI_RN";
BA_ "ISignalName" SG_ 767 ST_MONI_RN "ST_MONI_RN";
BA_ "LongName" SG_ 767 ST_MONI_RN "Status_Überwachung_Regen";
BA_ "SysSignalName" SG_ 767 ST_MONI_RN "ST_MONI_RN";
BA_ "CompuMethodName" SG_ 767 ST_ERR_RNLISE "ST_ERR_RNLISE";
BA_ "ISignalName" SG_ 767 ST_ERR_RNLISE "ST_ERR_RNLISE";
BA_ "LongName" SG_ 767 ST_ERR_RNLISE "Status_Fehler_Regen-Licht-Sensor";
BA_ "SysSignalName" SG_ 767 ST_ERR_RNLISE "ST_ERR_RNLISE";
BA_ "CompuMethodName" SG_ 767 ST_RN_CLO "ST_RN_CLO";
BA_ "ISignalName" SG_ 767 ST_RN_CLO "ST_RN_CLO";
BA_ "LongName" SG_ 767 ST_RN_CLO "Status_Regen_Schließen";
BA_ "SysSignalName" SG_ 767 ST_RN_CLO "ST_RN_CLO";
BA_ "CompuMethodName" SG_ 619 CRC_ST_RSP_BN2020 "CRC8";
BA_ "ISignalName" SG_ 619 CRC_ST_RSP_BN2020 "CRC_ST_RSP_BN2020";
BA_ "LongName" SG_ 619 CRC_ST_RSP_BN2020 "CRC_Status_Heckspoiler_BN2020";
BA_ "SysSignalName" SG_ 619 CRC_ST_RSP_BN2020 "CRC_ST_RSP_BN2020";
BA_ "CompuMethodName" SG_ 619 ALIV_ST_RSP_BN2020 "ALIV_4_BIT_UInt";
BA_ "ISignalName" SG_ 619 ALIV_ST_RSP_BN2020 "ALIV_ST_RSP_BN2020";
BA_ "LongName" SG_ 619 ALIV_ST_RSP_BN2020 "Alive_Status_Heckspoiler_BN2020";
BA_ "SysSignalName" SG_ 619 ALIV_ST_RSP_BN2020 "ALIV_ST_RSP_BN2020";
BA_ "CompuMethodName" SG_ 619 ST_RSP_2 "ST_RSP_2";
BA_ "ISignalName" SG_ 619 ST_RSP_2 "ST_RSP_2";
BA_ "LongName" SG_ 619 ST_RSP_2 "Status_Heckspoiler_2";
BA_ "SysSignalName" SG_ 619 ST_RSP_2 "ST_RSP_2";
BA_ "CompuMethodName" SG_ 619 ST_MOD_RSP "ST_MOD_RSP";
BA_ "ISignalName" SG_ 619 ST_MOD_RSP "ST_MOD_RSP";
BA_ "LongName" SG_ 619 ST_MOD_RSP "Status_Modus_Heckspoiler";
BA_ "SysSignalName" SG_ 619 ST_MOD_RSP "ST_MOD_RSP";
BA_ "ISignalName" SG_ 619 ST_RSP_BN2020_dummy_18_31 "ST_RSP_BN2020_dummy_18_31";
BA_ "LongName" SG_ 619 ST_RSP_BN2020_dummy_18_31 "ST_RSP_BN2020_dummy_18_31";
BA_ "SysSignalName" SG_ 619 ST_RSP_BN2020_dummy_18_31 "ST_RSP_BN2020_dummy_18_31";
BA_ "ISignalName" SG_ 619 ST_RSP_BN2020_dummy_32_63 "ST_RSP_BN2020_dummy_32_63";
BA_ "LongName" SG_ 619 ST_RSP_BN2020_dummy_32_63 "ST_RSP_BN2020_dummy_32_63";
BA_ "SysSignalName" SG_ 619 ST_RSP_BN2020_dummy_32_63 "ST_RSP_BN2020_dummy_32_63";
BA_ "CompuMethodName" SG_ 544 CRC_ST_RSU_CON "CRC8";
BA_ "ISignalName" SG_ 544 CRC_ST_RSU_CON "CRC_ST_RSU_CON";
BA_ "LongName" SG_ 544 CRC_ST_RSU_CON "CRC_Status_RSU_Zustand";
BA_ "SysSignalName" SG_ 544 CRC_ST_RSU_CON "CRC_ST_RSU_CON";
BA_ "CompuMethodName" SG_ 544 ALIV_ST_RSU_CON "ALIV_4_BIT_Unsigned_Integer";
BA_ "ISignalName" SG_ 544 ALIV_ST_RSU_CON "ALIV_ST_RSU_CON";
BA_ "LongName" SG_ 544 ALIV_ST_RSU_CON "Alive_Status_RSU_Zustand";
BA_ "SysSignalName" SG_ 544 ALIV_ST_RSU_CON "ALIV_ST_RSU_CON";
BA_ "CompuMethodName" SG_ 544 CHL_ST_RSU_CON "CHL_4_UInt";
BA_ "ISignalName" SG_ 544 CHL_ST_RSU_CON "CHL_ST_RSU_CON";
BA_ "LongName" SG_ 544 CHL_ST_RSU_CON "CHL_Status_RSU_Zustand";
BA_ "SysSignalName" SG_ 544 CHL_ST_RSU_CON "CHL_ST_RSU_CON";
BA_ "CompuMethodName" SG_ 544 ST_RSU_ACY "ST_RSU_ACY";
BA_ "ISignalName" SG_ 544 ST_RSU_ACY "ST_RSU_ACY";
BA_ "LongName" SG_ 544 ST_RSU_ACY "Status_RSU_Aktivität";
BA_ "SysSignalName" SG_ 544 ST_RSU_ACY "ST_RSU_ACY";
BA_ "ISignalName" SG_ 544 ST_RSU_CON_dummy_21_31 "ST_RSU_CON_dummy_21_31";
BA_ "LongName" SG_ 544 ST_RSU_CON_dummy_21_31 "ST_RSU_CON_dummy_21_31";
BA_ "SysSignalName" SG_ 544 ST_RSU_CON_dummy_21_31 "ST_RSU_CON_dummy_21_31";
BA_ "ISignalName" SG_ 544 ST_RSU_CON_dummy_32_63 "ST_RSU_CON_dummy_32_63";
BA_ "LongName" SG_ 544 ST_RSU_CON_dummy_32_63 "ST_RSU_CON_dummy_32_63";
BA_ "SysSignalName" SG_ 544 ST_RSU_CON_dummy_32_63 "ST_RSU_CON_dummy_32_63";
BA_ "CompuMethodName" SG_ 1101 CRC_ST_RSU_MST "CRC8";
BA_ "ISignalName" SG_ 1101 CRC_ST_RSU_MST "CRC_ST_RSU_MST";
BA_ "LongName" SG_ 1101 CRC_ST_RSU_MST "CRC_Status_RSU_Master";
BA_ "SysSignalName" SG_ 1101 CRC_ST_RSU_MST "CRC_ST_RSU_MST";
BA_ "CompuMethodName" SG_ 1101 ALIV_ST_RSU_MST "ALIV_4_BIT_Unsigned_Integer";
BA_ "ISignalName" SG_ 1101 ALIV_ST_RSU_MST "ALIV_ST_RSU_MST";
BA_ "LongName" SG_ 1101 ALIV_ST_RSU_MST "Alive_Status_RSU_Master";
BA_ "SysSignalName" SG_ 1101 ALIV_ST_RSU_MST "ALIV_ST_RSU_MST";
BA_ "CompuMethodName" SG_ 1101 CHL_ST_RSU_MST "CHL_4_UInt";
BA_ "ISignalName" SG_ 1101 CHL_ST_RSU_MST "CHL_ST_RSU_MST";
BA_ "LongName" SG_ 1101 CHL_ST_RSU_MST "CHL_Status_RSU_Master";
BA_ "SysSignalName" SG_ 1101 CHL_ST_RSU_MST "CHL_ST_RSU_MST";
BA_ "CompuMethodName" SG_ 1101 RSU_CON_PWF "RSU_CON_PWF";
BA_ "ISignalName" SG_ 1101 RSU_CON_PWF "RSU_CON_PWF";
BA_ "LongName" SG_ 1101 RSU_CON_PWF "RSU_Zustand_PWF";
BA_ "SysSignalName" SG_ 1101 RSU_CON_PWF "RSU_CON_PWF";
BA_ "CompuMethodName" SG_ 1101 RSU_DWA_ARM "RSU_DWA_ARM";
BA_ "ISignalName" SG_ 1101 RSU_DWA_ARM "RSU_DWA_ARM";
BA_ "LongName" SG_ 1101 RSU_DWA_ARM "RSU_DWA_Schärfen";
BA_ "SysSignalName" SG_ 1101 RSU_DWA_ARM "RSU_DWA_ARM";
BA_ "ISignalName" SG_ 1101 ST_RSU_MST_dummy_21_31 "ST_RSU_MST_dummy_21_31";
BA_ "LongName" SG_ 1101 ST_RSU_MST_dummy_21_31 "ST_RSU_MST_dummy_21_31";
BA_ "SysSignalName" SG_ 1101 ST_RSU_MST_dummy_21_31 "ST_RSU_MST_dummy_21_31";
BA_ "ISignalName" SG_ 1101 ST_RSU_MST_dummy_32_63 "ST_RSU_MST_dummy_32_63";
BA_ "LongName" SG_ 1101 ST_RSU_MST_dummy_32_63 "ST_RSU_MST_dummy_32_63";
BA_ "SysSignalName" SG_ 1101 ST_RSU_MST_dummy_32_63 "ST_RSU_MST_dummy_32_63";
BA_ "CompuMethodName" SG_ 693 CRC_ST_SSFN_DSC "CRC8";
BA_ "ISignalName" SG_ 693 CRC_ST_SSFN_DSC "CRC_ST_SSFN_DSC";
BA_ "LongName" SG_ 693 CRC_ST_SSFN_DSC "CRC_Status_Stillstandsfunktionen_DSC";
BA_ "SysSignalName" SG_ 693 CRC_ST_SSFN_DSC "CRC_ST_SSFN_DSC";
BA_ "CompuMethodName" SG_ 693 ALIV_ST_SSFN_DSC "ALIV_4_BIT_Unsigned_Integer";
BA_ "ISignalName" SG_ 693 ALIV_ST_SSFN_DSC "ALIV_ST_SSFN_DSC";
BA_ "LongName" SG_ 693 ALIV_ST_SSFN_DSC "Alive_Status_Stillstandsfunktionen_DSC";
BA_ "SysSignalName" SG_ 693 ALIV_ST_SSFN_DSC "ALIV_ST_SSFN_DSC";
BA_ "CompuMethodName" SG_ 693 CHL_ST_SSFN_DSC "CHL_4_UInt";
BA_ "ISignalName" SG_ 693 CHL_ST_SSFN_DSC "CHL_ST_SSFN_DSC";
BA_ "LongName" SG_ 693 CHL_ST_SSFN_DSC "CHL_Status_Stillstandsfunktionen_DSC";
BA_ "SysSignalName" SG_ 693 CHL_ST_SSFN_DSC "CHL_ST_SSFN_DSC";
BA_ "CompuMethodName" SG_ 693 ST_RBKR "ST_RBKR";
BA_ "ISignalName" SG_ 693 ST_RBKR "ST_RBKR";
BA_ "LongName" SG_ 693 ST_RBKR "Status_Rückrollgefahr";
BA_ "SysSignalName" SG_ 693 ST_RBKR "ST_RBKR";
BA_ "CompuMethodName" SG_ 693 ST_HHASS "ST_HHASS";
BA_ "ISignalName" SG_ 693 ST_HHASS "ST_HHASS";
BA_ "LongName" SG_ 693 ST_HHASS "Status_Anfahrassistent";
BA_ "SysSignalName" SG_ 693 ST_HHASS "ST_HHASS";
BA_ "CompuMethodName" SG_ 693 ST_AH "ST_AH";
BA_ "ISignalName" SG_ 693 ST_AH "ST_AH";
BA_ "LongName" SG_ 693 ST_AH "Status_AutoH";
BA_ "SysSignalName" SG_ 693 ST_AH "ST_AH";
BA_ "CompuMethodName" SG_ 693 ST_HYD_DYN_BRKFN "ST_HYD_DYN_BRKFN";
BA_ "ISignalName" SG_ 693 ST_HYD_DYN_BRKFN "ST_HYD_DYN_BRKFN";
BA_ "LongName" SG_ 693 ST_HYD_DYN_BRKFN "Status_Hydraulik_Dynamisch_Bremsfunktion";
BA_ "SysSignalName" SG_ 693 ST_HYD_DYN_BRKFN "ST_HYD_DYN_BRKFN";
BA_ "CompuMethodName" SG_ 693 ST_PBRK "ST_PBRK";
BA_ "ISignalName" SG_ 693 ST_PBRK "ST_PBRK";
BA_ "LongName" SG_ 693 ST_PBRK "Status_Parkbremse";
BA_ "SysSignalName" SG_ 693 ST_PBRK "ST_PBRK";
BA_ "CompuMethodName" SG_ 693 RQ_DTR_SSFN "RQ_DTR_SSFN";
BA_ "ISignalName" SG_ 693 RQ_DTR_SSFN "RQ_DTR_SSFN";
BA_ "LongName" SG_ 693 RQ_DTR_SSFN "Anforderung_Antriebsmomentenreduzierung_Stillstandsfunktionen";
BA_ "SysSignalName" SG_ 693 RQ_DTR_SSFN "RQ_DTR_SSFN";
BA_ "CompuMethodName" SG_ 693 ControlLedAutoHold "ControlLedAutoHold";
BA_ "ISignalName" SG_ 693 ControlLedAutoHold "ControlLedAutoHold";
BA_ "LongName" SG_ 693 ControlLedAutoHold "ControlLedAutoHold";
BA_ "SysSignalName" SG_ 693 ControlLedAutoHold "ControlLedAutoHold";
BA_ "CompuMethodName" SG_ 693 OP_PUBU_EPB "OP_PUBU_EPB";
BA_ "ISignalName" SG_ 693 OP_PUBU_EPB "OP_PUBU_EPB";
BA_ "LongName" SG_ 693 OP_PUBU_EPB "Bedienung_Taster_EPB";
BA_ "SysSignalName" SG_ 693 OP_PUBU_EPB "OP_PUBU_EPB";
BA_ "CompuMethodName" SG_ 693 QU_FN_PCR_IBK "QU_FN_PCR_IBK";
BA_ "ISignalName" SG_ 693 QU_FN_PCR_IBK "QU_FN_PCR_IBK";
BA_ "LongName" SG_ 693 QU_FN_PCR_IBK "Qualifier_Funktion_PostCrash_iBrake";
BA_ "SysSignalName" SG_ 693 QU_FN_PCR_IBK "QU_FN_PCR_IBK";
BA_ "ISignalName" SG_ 693 ST_SSFN_DSC_dummy_40_63 "ST_SSFN_DSC_dummy_40_63";
BA_ "LongName" SG_ 693 ST_SSFN_DSC_dummy_40_63 "ST_SSFN_DSC_dummy_40_63";
BA_ "SysSignalName" SG_ 693 ST_SSFN_DSC_dummy_40_63 "ST_SSFN_DSC_dummy_40_63";
BA_ "CompuMethodName" SG_ 371 CRC_ST_STAB_DSC "CRC8";
BA_ "ISignalName" SG_ 371 CRC_ST_STAB_DSC "CRC_ST_STAB_DSC";
BA_ "LongName" SG_ 371 CRC_ST_STAB_DSC "CRC_Status_Stabilisierung_DSC";
BA_ "SysSignalName" SG_ 371 CRC_ST_STAB_DSC "CRC_ST_STAB_DSC";
BA_ "CompuMethodName" SG_ 371 ALIV_ST_STAB_DSC "Aliv_4";
BA_ "ISignalName" SG_ 371 ALIV_ST_STAB_DSC "ALIV_ST_STAB_DSC";
BA_ "LongName" SG_ 371 ALIV_ST_STAB_DSC "Alive_Status_Stabilisierung_DSC";
BA_ "SysSignalName" SG_ 371 ALIV_ST_STAB_DSC "ALIV_ST_STAB_DSC";
BA_ "CompuMethodName" SG_ 371 ST_ECU_ST_STAB_DSC "ST_ECU_RES";
BA_ "ISignalName" SG_ 371 ST_ECU_ST_STAB_DSC "ST_ECU_ST_STAB_DSC";
BA_ "LongName" SG_ 371 ST_ECU_ST_STAB_DSC "Status_STG_Status_Stabilisierung_DSC";
BA_ "SysSignalName" SG_ 371 ST_ECU_ST_STAB_DSC "ST_ECU_ST_STAB_DSC";
BA_ "CompuMethodName" SG_ 371 QU_FN_FDR "QU_FN_FDR";
BA_ "ISignalName" SG_ 371 QU_FN_FDR "QU_FN_FDR";
BA_ "LongName" SG_ 371 QU_FN_FDR "Qualifier_Funktion_FDR";
BA_ "SysSignalName" SG_ 371 QU_FN_FDR "QU_FN_FDR";
BA_ "CompuMethodName" SG_ 371 QU_FN_ABS "QU_FN_ABS";
BA_ "ISignalName" SG_ 371 QU_FN_ABS "QU_FN_ABS";
BA_ "LongName" SG_ 371 QU_FN_ABS "Qualifier_Funktion_ABS";
BA_ "SysSignalName" SG_ 371 QU_FN_ABS "QU_FN_ABS";
BA_ "CompuMethodName" SG_ 371 QU_FN_ASC "QU_FN_ASC";
BA_ "ISignalName" SG_ 371 QU_FN_ASC "QU_FN_ASC";
BA_ "LongName" SG_ 371 QU_FN_ASC "Qualifier_Funktion_ASC";
BA_ "SysSignalName" SG_ 371 QU_FN_ASC "QU_FN_ASC";
BA_ "CompuMethodName" SG_ 371 ST_BRG_MSA "ST_BRG_MSA";
BA_ "ISignalName" SG_ 371 ST_BRG_MSA "ST_BRG_MSA";
BA_ "LongName" SG_ 371 ST_BRG_MSA "Status_Bremsung_MSA";
BA_ "SysSignalName" SG_ 371 ST_BRG_MSA "ST_BRG_MSA";
BA_ "CompuMethodName" SG_ 371 ST_BRG_DV "ST_BRG_DV";
BA_ "ISignalName" SG_ 371 ST_BRG_DV "ST_BRG_DV";
BA_ "LongName" SG_ 371 ST_BRG_DV "Status_Bremsung_Fahrer";
BA_ "SysSignalName" SG_ 371 ST_BRG_DV "ST_BRG_DV";
BA_ "CompuMethodName" SG_ 371 ST_UNRU_DSC "ST_UNRU_DSC";
BA_ "ISignalName" SG_ 371 ST_UNRU_DSC "ST_UNRU_DSC";
BA_ "LongName" SG_ 371 ST_UNRU_DSC "Status_Aggregatlauf_DSC";
BA_ "SysSignalName" SG_ 371 ST_UNRU_DSC "ST_UNRU_DSC";
BA_ "CompuMethodName" SG_ 1050 ST_ACTVN_KI_BC "ACTVN_KI_BC";
BA_ "ISignalName" SG_ 1050 ST_ACTVN_KI_BC "ST_ACTVN_KI_BC";
BA_ "LongName" SG_ 1050 ST_ACTVN_KI_BC "Status_Aktivierung_Kombi_BC";
BA_ "SysSignalName" SG_ 1050 ST_ACTVN_KI_BC "ST_ACTVN_KI_BC";
BA_ "CompuMethodName" SG_ 1050 ST_ACTVN_KI_CONT "ST_ACTVN_KI_CONT";
BA_ "ISignalName" SG_ 1050 ST_ACTVN_KI_CONT "ST_ACTVN_KI_CONT";
BA_ "LongName" SG_ 1050 ST_ACTVN_KI_CONT "Status_Aktivierung_Kombi_Inhalt";
BA_ "SysSignalName" SG_ 1050 ST_ACTVN_KI_CONT "ST_ACTVN_KI_CONT";
BA_ "CompuMethodName" SG_ 1050 ST_ACTVN_PRESL_KI "ACTVN_PRESL_KI";
BA_ "ISignalName" SG_ 1050 ST_ACTVN_PRESL_KI "ST_ACTVN_PRESL_KI";
BA_ "LongName" SG_ 1050 ST_ACTVN_PRESL_KI "Status_Aktivierung_Vorwahl_Kombi";
BA_ "SysSignalName" SG_ 1050 ST_ACTVN_PRESL_KI "ST_ACTVN_PRESL_KI";
BA_ "CompuMethodName" SG_ 1050 ST_BRIG_OFFS_KI "BRIG_OFFS_KI";
BA_ "ISignalName" SG_ 1050 ST_BRIG_OFFS_KI "ST_BRIG_OFFS_KI";
BA_ "LongName" SG_ 1050 ST_BRIG_OFFS_KI "Status_Helligkeit_Offset_Kombi";
BA_ "SysSignalName" SG_ 1050 ST_BRIG_OFFS_KI "ST_BRIG_OFFS_KI";
BA_ "CompuMethodName" SG_ 1013 ST_ACTVN_KI_CONT_2 "ST_ACTVN_KI_CONT_2";
BA_ "ISignalName" SG_ 1013 ST_ACTVN_KI_CONT_2 "ST_ACTVN_KI_CONT_2";
BA_ "LongName" SG_ 1013 ST_ACTVN_KI_CONT_2 "Status_Aktivierung_Kombi_Inhalt_2";
BA_ "SysSignalName" SG_ 1013 ST_ACTVN_KI_CONT_2 "ST_ACTVN_KI_CONT_2";
BA_ "CompuMethodName" SG_ 1013 ST_ACTVN_PRESL_KI_2 "ST_ACTVN_PRESL_KI_2";
BA_ "ISignalName" SG_ 1013 ST_ACTVN_PRESL_KI_2 "ST_ACTVN_PRESL_KI_2";
BA_ "LongName" SG_ 1013 ST_ACTVN_PRESL_KI_2 "Status_Aktivierung_Vorwahl_Kombi_2";
BA_ "SysSignalName" SG_ 1013 ST_ACTVN_PRESL_KI_2 "ST_ACTVN_PRESL_KI_2";
BA_ "CompuMethodName" SG_ 1013 ST_NAVI_DISP_TYP "ST_NAVI_DISP_TYP";
BA_ "ISignalName" SG_ 1013 ST_NAVI_DISP_TYP "ST_NAVI_DISP_TYP";
BA_ "LongName" SG_ 1013 ST_NAVI_DISP_TYP "Status_Navigation_Anzeige_Typ";
BA_ "SysSignalName" SG_ 1013 ST_NAVI_DISP_TYP "ST_NAVI_DISP_TYP";
BA_ "CompuMethodName" SG_ 1013 ST_BRIG_OFFS_KI_2 "BRIG_OFFS_KI_2";
BA_ "ISignalName" SG_ 1013 ST_BRIG_OFFS_KI_2 "ST_BRIG_OFFS_KI_2";
BA_ "LongName" SG_ 1013 ST_BRIG_OFFS_KI_2 "Status_Helligkeit_Offset_Kombi_2";
BA_ "SysSignalName" SG_ 1013 ST_BRIG_OFFS_KI_2 "ST_BRIG_OFFS_KI_2";
BA_ "CompuMethodName" SG_ 1013 ST_ENTAI_ECU_DISP "ST_ENTAI_ECU_DISP";
BA_ "ISignalName" SG_ 1013 ST_ENTAI_ECU_DISP "ST_ENTAI_ECU_DISP";
BA_ "LongName" SG_ 1013 ST_ENTAI_ECU_DISP "Status_Entertainment_STG_Anzeige";
BA_ "SysSignalName" SG_ 1013 ST_ENTAI_ECU_DISP "ST_ENTAI_ECU_DISP";
BA_ "CompuMethodName" SG_ 1013 StatusDZMorPowermeterDisplay "DZMorPowermeterDisplay";
BA_ "ISignalName" SG_ 1013 StatusDZMorPowermeterDisplay "StatusDZMorPowermeterDisplay";
BA_ "LongName" SG_ 1013 StatusDZMorPowermeterDisplay "StatusDZMorPowermeterDisplay";
BA_ "SysSignalName" SG_ 1013 StatusDZMorPowermeterDisplay "StatusDZMorPowermeterDisplay";
BA_ "CompuMethodName" SG_ 873 CRC_ST_TYR "CRC8_P_TYR";
BA_ "ISignalName" SG_ 873 CRC_ST_TYR "CRC_ST_TYR";
BA_ "LongName" SG_ 873 CRC_ST_TYR "CRC_Status_Reifen";
BA_ "SysSignalName" SG_ 873 CRC_ST_TYR "CRC_ST_TYR";
BA_ "CompuMethodName" SG_ 873 ALIV_ST_TYR "Aliv_4";
BA_ "ISignalName" SG_ 873 ALIV_ST_TYR "ALIV_ST_TYR";
BA_ "LongName" SG_ 873 ALIV_ST_TYR "Alive_Status_Reifen";
BA_ "SysSignalName" SG_ 873 ALIV_ST_TYR "ALIV_ST_TYR";
BA_ "ISignalName" SG_ 873 ST_TYR_dummy_12_15 "ST_TYR_dummy_12_15";
BA_ "LongName" SG_ 873 ST_TYR_dummy_12_15 "ST_TYR_dummy_12_15";
BA_ "SysSignalName" SG_ 873 ST_TYR_dummy_12_15 "ST_TYR_dummy_12_15";
BA_ "CompuMethodName" SG_ 873 QU_FN_TYR_INFO "QU_FN_TYR_INFO";
BA_ "ISignalName" SG_ 873 QU_FN_TYR_INFO "QU_FN_TYR_INFO";
BA_ "LongName" SG_ 873 QU_FN_TYR_INFO "Qualifier_Funktion_Reifen_Information";
BA_ "SysSignalName" SG_ 873 QU_FN_TYR_INFO "QU_FN_TYR_INFO";
BA_ "CompuMethodName" SG_ 873 QU_TPL "QU_TPL";
BA_ "ISignalName" SG_ 873 QU_TPL "QU_TPL";
BA_ "LongName" SG_ 873 QU_TPL "Qualifier_Reifendruckverlust";
BA_ "SysSignalName" SG_ 873 QU_TPL "QU_TPL";
BA_ "CompuMethodName" SG_ 873 QU_TFAI "QU_TFAI";
BA_ "ISignalName" SG_ 873 QU_TFAI "QU_TFAI";
BA_ "LongName" SG_ 873 QU_TFAI "Qualifier_Reifenplatten";
BA_ "SysSignalName" SG_ 873 QU_TFAI "QU_TFAI";
BA_ "CompuMethodName" SG_ 905 ST_CSOV_AIC "ST_VA_COOL";
BA_ "ISignalName" SG_ 905 ST_CSOV_AIC "ST_CSOV_AIC";
BA_ "LongName" SG_ 905 ST_CSOV_AIC "Status_Kälteabsperrventil_Klima";
BA_ "SysSignalName" SG_ 905 ST_CSOV_AIC "ST_CSOV_AIC";
BA_ "CompuMethodName" SG_ 905 ST_PO_CSOV_AIC "ST_PO_CSOV_AIC";
BA_ "ISignalName" SG_ 905 ST_PO_CSOV_AIC "ST_PO_CSOV_AIC";
BA_ "LongName" SG_ 905 ST_PO_CSOV_AIC "Status_Position_Kälteabsperrventil_Klima";
BA_ "SysSignalName" SG_ 905 ST_PO_CSOV_AIC "ST_PO_CSOV_AIC";
BA_ "CompuMethodName" SG_ 895 ALIV_ST_VEH_TONE "ALIV_4_BIT_Unsigned_Integer";
BA_ "ISignalName" SG_ 895 ALIV_ST_VEH_TONE "ALIV_ST_VEH_TONE";
BA_ "LongName" SG_ 895 ALIV_ST_VEH_TONE "Alive_Status_Fahrzeug_Klang";
BA_ "SysSignalName" SG_ 895 ALIV_ST_VEH_TONE "ALIV_ST_VEH_TONE";
BA_ "CompuMethodName" SG_ 895 ST_ACY_VEH_TONE "ACY_VEH_TONE";
BA_ "ISignalName" SG_ 895 ST_ACY_VEH_TONE "ST_ACY_VEH_TONE";
BA_ "LongName" SG_ 895 ST_ACY_VEH_TONE "Status_Aktivität_Fahrzeug_Klang";
BA_ "SysSignalName" SG_ 895 ST_ACY_VEH_TONE "ST_ACY_VEH_TONE";
BA_ "CompuMethodName" SG_ 838 CRC_ST_VIB_STW "CRC8";
BA_ "ISignalName" SG_ 838 CRC_ST_VIB_STW "CRC_ST_VIB_STW";
BA_ "LongName" SG_ 838 CRC_ST_VIB_STW "CRC_Status_Vibration_Lenkrad";
BA_ "SysSignalName" SG_ 838 CRC_ST_VIB_STW "CRC_ST_VIB_STW";
BA_ "CompuMethodName" SG_ 838 ALIV_ST_VIB_STW "ALIV_COU_4";
BA_ "ISignalName" SG_ 838 ALIV_ST_VIB_STW "ALIV_ST_VIB_STW";
BA_ "LongName" SG_ 838 ALIV_ST_VIB_STW "Alive_Status_Vibration_Lenkrad";
BA_ "SysSignalName" SG_ 838 ALIV_ST_VIB_STW "ALIV_ST_VIB_STW";
BA_ "CompuMethodName" SG_ 838 QU_HOFF_RCOG_SEN "QU_HOFF_RCOG_SEN";
BA_ "ISignalName" SG_ 838 QU_HOFF_RCOG_SEN "QU_HOFF_RCOG_SEN";
BA_ "LongName" SG_ 838 QU_HOFF_RCOG_SEN "Qualifier_Hands-Off_Erkennung_Sensor";
BA_ "SysSignalName" SG_ 838 QU_HOFF_RCOG_SEN "QU_HOFF_RCOG_SEN";
BA_ "CompuMethodName" SG_ 838 QU_SER_VIB_STW "QU_SER_VIB_STW";
BA_ "ISignalName" SG_ 838 QU_SER_VIB_STW "QU_SER_VIB_STW";
BA_ "LongName" SG_ 838 QU_SER_VIB_STW "Qualifier_Service_Vibration_Lenkrad";
BA_ "SysSignalName" SG_ 838 QU_SER_VIB_STW "QU_SER_VIB_STW";
BA_ "CompuMethodName" SG_ 838 AVL_AMP_VIB_STW "AMP_VIB_STW";
BA_ "ISignalName" SG_ 838 AVL_AMP_VIB_STW "AVL_AMP_VIB_STW";
BA_ "LongName" SG_ 838 AVL_AMP_VIB_STW "Ist_Amplitude_Vibration_Lenkrad";
BA_ "SysSignalName" SG_ 838 AVL_AMP_VIB_STW "AVL_AMP_VIB_STW";
BA_ "ISignalName" SG_ 838 ST_VIB_STW_dummy_28_31 "ST_VIB_STW_dummy_28_31";
BA_ "LongName" SG_ 838 ST_VIB_STW_dummy_28_31 "ST_VIB_STW_dummy_28_31";
BA_ "SysSignalName" SG_ 838 ST_VIB_STW_dummy_28_31 "ST_VIB_STW_dummy_28_31";
BA_ "CompuMethodName" SG_ 271 QU_FN_BRCHAIN "QU_FN_BRCHAIN";
BA_ "ISignalName" SG_ 271 QU_FN_BRCHAIN "QU_FN_BRCHAIN";
BA_ "LongName" SG_ 271 QU_FN_BRCHAIN "Qualifier_Funktion_Bremskette";
BA_ "SysSignalName" SG_ 271 QU_FN_BRCHAIN "QU_FN_BRCHAIN";
BA_ "CompuMethodName" SG_ 271 QU_FN_WACHAIN "QU_FN_WACHAIN";
BA_ "ISignalName" SG_ 271 QU_FN_WACHAIN "QU_FN_WACHAIN";
BA_ "LongName" SG_ 271 QU_FN_WACHAIN "Qualifier_Funktion_Warnkette";
BA_ "SysSignalName" SG_ 271 QU_FN_WACHAIN "QU_FN_WACHAIN";
BA_ "CompuMethodName" SG_ 889 SU_FN_FRSG_ASST_DXP "SU_FN_FRSG_ASST_DXP";
BA_ "ISignalName" SG_ 889 SU_FN_FRSG_ASST_DXP "SU_FN_FRSG_ASST_DXP";
BA_ "LongName" SG_ 889 SU_FN_FRSG_ASST_DXP "Konfiguration_Funktion_Vorausschau_Assistent_Fahrerlebnis";
BA_ "SysSignalName" SG_ 889 SU_FN_FRSG_ASST_DXP "SU_FN_FRSG_ASST_DXP";
BA_ "CompuMethodName" SG_ 889 SU_VL_THO_ECS_DXP "SU_VL_THO_ECS_DXP";
BA_ "GenSigStartValue" SG_ 889 SU_VL_THO_ECS_DXP 1;
BA_ "ISignalName" SG_ 889 SU_VL_THO_ECS_DXP "SU_VL_THO_ECS_DXP";
BA_ "LongName" SG_ 889 SU_VL_THO_ECS_DXP "Konfiguration_Wert_Schwelle_ECOGeschwindigkeit_Fahrerlebnis";
BA_ "SysSignalName" SG_ 889 SU_VL_THO_ECS_DXP "SU_VL_THO_ECS_DXP";
BA_ "CompuMethodName" SG_ 804 SU_CLU_RPM_PA_DXP "SU_CLU_RPM_PA_DXP";
BA_ "ISignalName" SG_ 804 SU_CLU_RPM_PA_DXP "SU_CLU_RPM_PA_DXP";
BA_ "LongName" SG_ 804 SU_CLU_RPM_PA_DXP "Konfiguration_Cluster_Drehzahl_Pfad_Fahrerlebnis";
BA_ "SysSignalName" SG_ 804 SU_CLU_RPM_PA_DXP "SU_CLU_RPM_PA_DXP";
BA_ "CompuMethodName" SG_ 804 SU_CLU_TORQ_PA_DXP "SU_CLU_TORQ_PA_DXP";
BA_ "ISignalName" SG_ 804 SU_CLU_TORQ_PA_DXP "SU_CLU_TORQ_PA_DXP";
BA_ "LongName" SG_ 804 SU_CLU_TORQ_PA_DXP "Konfiguration_Cluster_Drehmoment_Pfad_Fahrerlebnis";
BA_ "SysSignalName" SG_ 804 SU_CLU_TORQ_PA_DXP "SU_CLU_TORQ_PA_DXP";
BA_ "CompuMethodName" SG_ 804 SU_FN_ASD_DXP "SU_FN_ASD_DXP";
BA_ "ISignalName" SG_ 804 SU_FN_ASD_DXP "SU_FN_ASD_DXP";
BA_ "LongName" SG_ 804 SU_FN_ASD_DXP "Konfiguration_Funktion_ASD_Fahrerlebnis";
BA_ "SysSignalName" SG_ 804 SU_FN_ASD_DXP "SU_FN_ASD_DXP";
BA_ "CompuMethodName" SG_ 804 SU_FN_SAIL_DXP "SU_FN_SAIL_DXP";
BA_ "ISignalName" SG_ 804 SU_FN_SAIL_DXP "SU_FN_SAIL_DXP";
BA_ "LongName" SG_ 804 SU_FN_SAIL_DXP "setup_function_sailing_driving-experience";
BA_ "SysSignalName" SG_ 804 SU_FN_SAIL_DXP "SU_FN_SAIL_DXP";
BA_ "CompuMethodName" SG_ 804 RequestSportDrivingModeReduction "RequestSportDrivingModeReductionRate";
BA_ "ISignalName" SG_ 804 RequestSportDrivingModeReduction "RequestSportDrivingModeReductionRate";
BA_ "LongName" SG_ 804 RequestSportDrivingModeReduction "RequestSportDrivingModeReductionRate";
BA_ "SysSignalName" SG_ 804 RequestSportDrivingModeReduction "RequestSportDrivingModeReductionRate";
BA_ "SystemSignalLongSymbol" SG_ 804 RequestSportDrivingModeReduction "RequestSportDrivingModeReductionRate";
BA_ "CompuMethodName" SG_ 975 DISP_RDO_BUT "DISP_RDO_BUT";
BA_ "ISignalName" SG_ 975 DISP_RDO_BUT "DISP_RDO_BUT";
BA_ "LongName" SG_ 975 DISP_RDO_BUT "Anzeige_Radio_Taste";
BA_ "SysSignalName" SG_ 975 DISP_RDO_BUT "DISP_RDO_BUT";
BA_ "CompuMethodName" SG_ 975 DISP_SCTRL "DISP_SCTRL";
BA_ "ISignalName" SG_ 975 DISP_SCTRL "DISP_SCTRL";
BA_ "LongName" SG_ 975 DISP_SCTRL "Anzeige_Schieberegler";
BA_ "SysSignalName" SG_ 975 DISP_SCTRL "DISP_SCTRL";
BA_ "CompuMethodName" SG_ 975 DISP_LNK "DISP_LNK";
BA_ "ISignalName" SG_ 975 DISP_LNK "DISP_LNK";
BA_ "LongName" SG_ 975 DISP_LNK "Anzeige_Verknuepfung";
BA_ "SysSignalName" SG_ 975 DISP_LNK "DISP_LNK";
BA_ "CompuMethodName" SG_ 975 DISP_CHB "DISP_CHB";
BA_ "ISignalName" SG_ 975 DISP_CHB "DISP_CHB";
BA_ "LongName" SG_ 975 DISP_CHB "Anzeige_Checkbox";
BA_ "SysSignalName" SG_ 975 DISP_CHB "DISP_CHB";
BA_ "CompuMethodName" SG_ 975 LST_REGI_S_DISP_HUD "LST_REGI_S_DISP_HUD";
BA_ "ISignalName" SG_ 975 LST_REGI_S_DISP_HUD "LST_REGI_S_DISP_HUD";
BA_ "LongName" SG_ 975 LST_REGI_S_DISP_HUD "Liste_Eintrag_Sport_Anzeige_HUD";
BA_ "SysSignalName" SG_ 975 LST_REGI_S_DISP_HUD "LST_REGI_S_DISP_HUD";
BA_ "CompuMethodName" SG_ 1028 SU_MDRV_3_IDX "MDRV_3_IDX";
BA_ "ISignalName" SG_ 1028 SU_MDRV_3_IDX "SU_MDRV_3_IDX";
BA_ "LongName" SG_ 1028 SU_MDRV_3_IDX "Konfiguration_M-Drive_3_Index";
BA_ "SysSignalName" SG_ 1028 SU_MDRV_3_IDX "SU_MDRV_3_IDX";
BA_ "CompuMethodName" SG_ 1028 SU_MDRV_3_DRVGMOD "SU_MDRV_3_DRVGMOD";
BA_ "ISignalName" SG_ 1028 SU_MDRV_3_DRVGMOD "SU_MDRV_3_DRVGMOD";
BA_ "LongName" SG_ 1028 SU_MDRV_3_DRVGMOD "Konfiguration_M-Drive_3_Fahrmodus";
BA_ "SysSignalName" SG_ 1028 SU_MDRV_3_DRVGMOD "SU_MDRV_3_DRVGMOD";
BA_ "CompuMethodName" SG_ 1028 SU_MDRV_3_SOU "SU_MDRV_3_SOU";
BA_ "ISignalName" SG_ 1028 SU_MDRV_3_SOU "SU_MDRV_3_SOU";
BA_ "LongName" SG_ 1028 SU_MDRV_3_SOU "Konfiguration_M-Drive_3_Ton";
BA_ "SysSignalName" SG_ 1028 SU_MDRV_3_SOU "SU_MDRV_3_SOU";
BA_ "CompuMethodName" SG_ 1028 SU_MDRV_3_MSA "SU_MDRV_3_MSA";
BA_ "ISignalName" SG_ 1028 SU_MDRV_3_MSA "SU_MDRV_3_MSA";
BA_ "LongName" SG_ 1028 SU_MDRV_3_MSA "Konfiguration_M-Drive_3_MSA";
BA_ "SysSignalName" SG_ 1028 SU_MDRV_3_MSA "SU_MDRV_3_MSA";
BA_ "CompuMethodName" SG_ 1028 SU_MDRV_3_ASR "SU_MDRV_3_ASR";
BA_ "ISignalName" SG_ 1028 SU_MDRV_3_ASR "SU_MDRV_3_ASR";
BA_ "LongName" SG_ 1028 SU_MDRV_3_ASR "Konfiguration_M-Drive_3_ASR";
BA_ "SysSignalName" SG_ 1028 SU_MDRV_3_ASR "SU_MDRV_3_ASR";
BA_ "CompuMethodName" SG_ 1028 SU_MDRV_3_BRPD "CTR_BRPD_SU";
BA_ "ISignalName" SG_ 1028 SU_MDRV_3_BRPD "SU_MDRV_3_BRPD";
BA_ "LongName" SG_ 1028 SU_MDRV_3_BRPD "Konfiguration_M-Drive_3_Bremspedal";
BA_ "SysSignalName" SG_ 1028 SU_MDRV_3_BRPD "SU_MDRV_3_BRPD";
BA_ "CompuMethodName" SG_ 1028 SetupMDrive3MControlPlusTraction "SetupTractionLevel";
BA_ "ISignalName" SG_ 1028 SetupMDrive3MControlPlusTraction "SetupMDrive3MControlPlusTraction";
BA_ "LongName" SG_ 1028 SetupMDrive3MControlPlusTraction "SetupMDrive3MControlPlusTraction";
BA_ "SysSignalName" SG_ 1028 SetupMDrive3MControlPlusTraction "SetupMDrive3MControlPlusTraction";
BA_ "CompuMethodName" SG_ 1028 SetupMDrive3MControlPlusBrakeBal "SetupBalanceLevel";
BA_ "ISignalName" SG_ 1028 SetupMDrive3MControlPlusBrakeBal "SetupMDrive3MControlPlusBrakeBalance";
BA_ "LongName" SG_ 1028 SetupMDrive3MControlPlusBrakeBal "SetupMDrive3MControlPlusBrakeBalance";
BA_ "SysSignalName" SG_ 1028 SetupMDrive3MControlPlusBrakeBal "SetupMDrive3MControlPlusBrakeBalance";
BA_ "SystemSignalLongSymbol" SG_ 1028 SetupMDrive3MControlPlusBrakeBal "SetupMDrive3MControlPlusBrakeBalance";
BA_ "CompuMethodName" SG_ 1049 SU_PWF_SWO_LVG_CKM "PWF_SWO_LVG_CKM";
BA_ "ISignalName" SG_ 1049 SU_PWF_SWO_LVG_CKM "SU_PWF_SWO_LVG_CKM";
BA_ "LongName" SG_ 1049 SU_PWF_SWO_LVG_CKM "Konfiguration_PWF_Abschaltung_Wohnen_CKM";
BA_ "SysSignalName" SG_ 1049 SU_PWF_SWO_LVG_CKM "SU_PWF_SWO_LVG_CKM";
BA_ "CompuMethodName" SG_ 717 OP_SCHRG_DFT_CHRGS_KEY "OP_SCHRG_DFT_CHRGS_KEY";
BA_ "ISignalName" SG_ 717 OP_SCHRG_DFT_CHRGS_KEY "OP_SCHRG_DFT_CHRGS_KEY";
BA_ "LongName" SG_ 717 OP_SCHRG_DFT_CHRGS_KEY "Bedienung_SCharge_Voreinstellung_Ladeplan_Schlüssel";
BA_ "SysSignalName" SG_ 717 OP_SCHRG_DFT_CHRGS_KEY "OP_SCHRG_DFT_CHRGS_KEY";
BA_ "CompuMethodName" SG_ 717 OP_SCHRG_ILYCH_KEY "OP_SCHRG_ILYCH_KEY";
BA_ "ISignalName" SG_ 717 OP_SCHRG_ILYCH_KEY "OP_SCHRG_ILYCH_KEY";
BA_ "LongName" SG_ 717 OP_SCHRG_ILYCH_KEY "Bedienung_SCharge_Sofortladen_Schlüssel";
BA_ "SysSignalName" SG_ 717 OP_SCHRG_ILYCH_KEY "OP_SCHRG_ILYCH_KEY";
BA_ "CompuMethodName" SG_ 692 OP_SCHRG_DFT_CHRGS_REM "BedienungSChargeVoreinstellungLadeplanRemote";
BA_ "ISignalName" SG_ 692 OP_SCHRG_DFT_CHRGS_REM "OP_SCHRG_DFT_CHRGS_REM";
BA_ "LongName" SG_ 692 OP_SCHRG_DFT_CHRGS_REM "Bedienung_SCharge_Voreinstellung_Ladeplan_Remote";
BA_ "SysSignalName" SG_ 692 OP_SCHRG_DFT_CHRGS_REM "OP_SCHRG_DFT_CHRGS_REM";
BA_ "CompuMethodName" SG_ 692 OP_SCHRG_ADJU_REM "OP_SCHRG_ADJU_REM";
BA_ "ISignalName" SG_ 692 OP_SCHRG_ADJU_REM "OP_SCHRG_ADJU_REM";
BA_ "LongName" SG_ 692 OP_SCHRG_ADJU_REM "Bedienung_SCharge_Einstellung_Remote";
BA_ "SysSignalName" SG_ 692 OP_SCHRG_ADJU_REM "OP_SCHRG_ADJU_REM";
BA_ "CompuMethodName" SG_ 692 OP_SCHRG_ILYCH_REM "OP_SCHRG_ILYCH_REM";
BA_ "ISignalName" SG_ 692 OP_SCHRG_ILYCH_REM "OP_SCHRG_ILYCH_REM";
BA_ "LongName" SG_ 692 OP_SCHRG_ILYCH_REM "Bedienung_SCharge_Sofortladen_Remote";
BA_ "SysSignalName" SG_ 692 OP_SCHRG_ILYCH_REM "OP_SCHRG_ILYCH_REM";
BA_ "CompuMethodName" SG_ 692 OperationAcCurrentLimitRemote "OperationAcCurrentLimitRemote";
BA_ "ISignalName" SG_ 692 OperationAcCurrentLimitRemote "OperationAcCurrentLimitRemote";
BA_ "LongName" SG_ 692 OperationAcCurrentLimitRemote "OperationAcCurrentLimitRemote";
BA_ "SysSignalName" SG_ 692 OperationAcCurrentLimitRemote "OperationAcCurrentLimitRemote";
BA_ "CompuMethodName" SG_ 692 OperationChargingCurrentLimitMod "OperationChargingCurrentLimitMode2Remote";
BA_ "ISignalName" SG_ 692 OperationChargingCurrentLimitMod "OperationChargingCurrentLimitMode2Remote";
BA_ "LongName" SG_ 692 OperationChargingCurrentLimitMod "OperationChargingCurrentLimitMode2Remote";
BA_ "SysSignalName" SG_ 692 OperationChargingCurrentLimitMod "OperationChargingCurrentLimitMode2Remote";
BA_ "SystemSignalLongSymbol" SG_ 692 OperationChargingCurrentLimitMod "OperationChargingCurrentLimitMode2Remote";
BA_ "CompuMethodName" SG_ 848 ST_SU_SAMD_EVEH "SU_SAMD_EVEH";
BA_ "ISignalName" SG_ 848 ST_SU_SAMD_EVEH "ST_SU_SAMD_EVEH";
BA_ "LongName" SG_ 848 ST_SU_SAMD_EVEH "Status_Konfiguration_Aufstartmodus_Elektrisches-Fahrzeug";
BA_ "SysSignalName" SG_ 848 ST_SU_SAMD_EVEH "ST_SU_SAMD_EVEH";
BA_ "CompuMethodName" SG_ 848 ST_ADJU_VEM_VEH "ST_ADJU_VEM_VEH";
BA_ "ISignalName" SG_ 848 ST_ADJU_VEM_VEH "ST_ADJU_VEM_VEH";
BA_ "LongName" SG_ 848 ST_ADJU_VEM_VEH "Status_Einstellung_VEM_Fahrzeug";
BA_ "SysSignalName" SG_ 848 ST_ADJU_VEM_VEH "ST_ADJU_VEM_VEH";
BA_ "CompuMethodName" SG_ 848 DISP_TAR_SOC_BAS "DSTN_SOC_BAS";
BA_ "ISignalName" SG_ 848 DISP_TAR_SOC_BAS "DISP_TAR_SOC_BAS";
BA_ "LongName" SG_ 848 DISP_TAR_SOC_BAS "Anzeige_Soll_SOC_Batterysave";
BA_ "SysSignalName" SG_ 848 DISP_TAR_SOC_BAS "DISP_TAR_SOC_BAS";
BA_ "CompuMethodName" SG_ 848 SU_DSTN_SOC_BAS "SU_DSTN_SOC_BAS";
BA_ "ISignalName" SG_ 848 SU_DSTN_SOC_BAS "SU_DSTN_SOC_BAS";
BA_ "LongName" SG_ 848 SU_DSTN_SOC_BAS "Konfiguration_Ziel_SOC_Batterysave";
BA_ "SysSignalName" SG_ 848 SU_DSTN_SOC_BAS "SU_DSTN_SOC_BAS";
BA_ "CompuMethodName" SG_ 848 ST_SU_RECUP_LEV "SU_RECUP_LEV";
BA_ "ISignalName" SG_ 848 ST_SU_RECUP_LEV "ST_SU_RECUP_LEV";
BA_ "LongName" SG_ 848 ST_SU_RECUP_LEV "Status_Konfiguration_Rekuperation_Niveau";
BA_ "SysSignalName" SG_ 848 ST_SU_RECUP_LEV "ST_SU_RECUP_LEV";
BA_ "CompuMethodName" SG_ 848 AVAI_OPTS_RECUP "AVAI_OPTS_RECUP";
BA_ "ISignalName" SG_ 848 AVAI_OPTS_RECUP "AVAI_OPTS_RECUP";
BA_ "LongName" SG_ 848 AVAI_OPTS_RECUP "Verfügbarkeit_Optionen_Rekuperation";
BA_ "SysSignalName" SG_ 848 AVAI_OPTS_RECUP "AVAI_OPTS_RECUP";
BA_ "CompuMethodName" SG_ 848 ACTVN_USC_VEM "ACTVN_USC_VEM";
BA_ "ISignalName" SG_ 848 ACTVN_USC_VEM "ACTVN_USC_VEM";
BA_ "LongName" SG_ 848 ACTVN_USC_VEM "Aktivierung_Usecase_VEM";
BA_ "SysSignalName" SG_ 848 ACTVN_USC_VEM "ACTVN_USC_VEM";
BA_ "CompuMethodName" SG_ 776 AVL_DRV_EVEH "AVL_DRV_EVEH";
BA_ "ISignalName" SG_ 776 AVL_DRV_EVEH "AVL_DRV_EVEH";
BA_ "LongName" SG_ 776 AVL_DRV_EVEH "Ist_Antrieb_Elektrisches-Fahrzeug";
BA_ "SysSignalName" SG_ 776 AVL_DRV_EVEH "AVL_DRV_EVEH";
BA_ "CompuMethodName" SG_ 776 DISP_DRV_EVEH_KI "DISP_DRV_EVEH_KI";
BA_ "ISignalName" SG_ 776 DISP_DRV_EVEH_KI "DISP_DRV_EVEH_KI";
BA_ "LongName" SG_ 776 DISP_DRV_EVEH_KI "display_drive_electric-vehicle_instrument-pack";
BA_ "SysSignalName" SG_ 776 DISP_DRV_EVEH_KI "DISP_DRV_EVEH_KI";
BA_ "CompuMethodName" SG_ 776 RQ_SW_EVEH_UD_KI_LST "RQ_SW_EVEH_UD_KI_LST";
BA_ "ISignalName" SG_ 776 RQ_SW_EVEH_UD_KI_LST "RQ_SW_EVEH_UD_KI_LST";
BA_ "LongName" SG_ 776 RQ_SW_EVEH_UD_KI_LST "Anforderung_Schalter_Elektrisches-Fahrzeug_Update_Kombi_Liste";
BA_ "SysSignalName" SG_ 776 RQ_SW_EVEH_UD_KI_LST "RQ_SW_EVEH_UD_KI_LST";
BA_ "CompuMethodName" SG_ 776 ST_EVEH_MOD_AVAI_KI_LST "ST_EVEH_MOD_AVAI_KI_LST";
BA_ "ISignalName" SG_ 776 ST_EVEH_MOD_AVAI_KI_LST "ST_EVEH_MOD_AVAI_KI_LST";
BA_ "LongName" SG_ 776 ST_EVEH_MOD_AVAI_KI_LST "Status_Elektrisches-Fahrzeug_Modus_Verfügbarkeit_Kombi_Liste";
BA_ "SysSignalName" SG_ 776 ST_EVEH_MOD_AVAI_KI_LST "ST_EVEH_MOD_AVAI_KI_LST";
BA_ "CompuMethodName" SG_ 776 ST_EVEH_DISP_PO_KI_LST "ST_EVEH_DISP_PO_KI_LST";
BA_ "ISignalName" SG_ 776 ST_EVEH_DISP_PO_KI_LST "ST_EVEH_DISP_PO_KI_LST";
BA_ "LongName" SG_ 776 ST_EVEH_DISP_PO_KI_LST "Status_Elektrisches-Fahrzeug_Anzeige_Position_Kombi_Liste";
BA_ "SysSignalName" SG_ 776 ST_EVEH_DISP_PO_KI_LST "ST_EVEH_DISP_PO_KI_LST";
BA_ "CompuMethodName" SG_ 776 AVL_SU_SOC_HLD_ACTVN_2 "AVL_SU_SOC_HLD_ACTVN_2";
BA_ "ISignalName" SG_ 776 AVL_SU_SOC_HLD_ACTVN_2 "AVL_SU_SOC_HLD_ACTVN_2";
BA_ "LongName" SG_ 776 AVL_SU_SOC_HLD_ACTVN_2 "Ist_Konfiguration_SOC_Hold_Aktivierung_2";
BA_ "SysSignalName" SG_ 776 AVL_SU_SOC_HLD_ACTVN_2 "AVL_SU_SOC_HLD_ACTVN_2";
BA_ "CompuMethodName" SG_ 129 DataApplicationSecurityStatus "DataApplicationSecurityStatus";
BA_ "ISignalName" SG_ 129 DataApplicationSecurityStatus "DataApplicationSecurityStatus";
BA_ "LongName" SG_ 129 DataApplicationSecurityStatus "DataApplicationSecurityStatus";
BA_ "SysSignalName" SG_ 129 DataApplicationSecurityStatus "DataApplicationSecurityStatus";
BA_ "CompuMethodName" SG_ 309 StatusRPMSyncASD "StatusRPMSyncASD";
BA_ "ISignalName" SG_ 309 StatusRPMSyncASD "StatusRPMSyncASD";
BA_ "LongName" SG_ 309 StatusRPMSyncASD "StatusRPMSyncASD";
BA_ "SysSignalName" SG_ 309 StatusRPMSyncASD "StatusRPMSyncASD";
BA_ "CompuMethodName" SG_ 309 StatusShiftASD "StatusShiftASD";
BA_ "ISignalName" SG_ 309 StatusShiftASD "StatusShiftASD";
BA_ "LongName" SG_ 309 StatusShiftASD "StatusShiftASD";
BA_ "SysSignalName" SG_ 309 StatusShiftASD "StatusShiftASD";
BA_ "CompuMethodName" SG_ 309 IntensityShiftASD "IntensityShiftASD";
BA_ "ISignalName" SG_ 309 IntensityShiftASD "IntensityShiftASD";
BA_ "LongName" SG_ 309 IntensityShiftASD "IntensityShiftASD";
BA_ "SysSignalName" SG_ 309 IntensityShiftASD "IntensityShiftASD";
BA_ "CompuMethodName" SG_ 750 FunctionBrake "FunctionBrake";
BA_ "ISignalName" SG_ 750 FunctionBrake "FunctionBrake";
BA_ "LongName" SG_ 750 FunctionBrake "FunctionBrake";
BA_ "SysSignalName" SG_ 750 FunctionBrake "FunctionBrake";
BA_ "CompuMethodName" SG_ 347 StatusAlcoholInterlockDevice "StatusAlcoholInterlockDevice";
BA_ "ISignalName" SG_ 347 StatusAlcoholInterlockDevice "StatusAlcoholInterlockDevice";
BA_ "LongName" SG_ 347 StatusAlcoholInterlockDevice "StatusAlcoholInterlockDevice";
BA_ "SysSignalName" SG_ 347 StatusAlcoholInterlockDevice "StatusAlcoholInterlockDevice";
BA_ "CompuMethodName" SG_ 347 StatusActivationAlcoholInterlock "StatusActivationAlcoholInterlockDevice";
BA_ "ISignalName" SG_ 347 StatusActivationAlcoholInterlock "StatusActivationAlcoholInterlockDevice";
BA_ "LongName" SG_ 347 StatusActivationAlcoholInterlock "StatusActivationAlcoholInterlockDevice";
BA_ "SysSignalName" SG_ 347 StatusActivationAlcoholInterlock "StatusActivationAlcoholInterlockDevice";
BA_ "SystemSignalLongSymbol" SG_ 347 StatusActivationAlcoholInterlock "StatusActivationAlcoholInterlockDevice";
BA_ "CompuMethodName" SG_ 1106 VoltageSensorCoolantLevel "VoltageSensorCoolantLevel";
BA_ "ISignalName" SG_ 1106 VoltageSensorCoolantLevel "VoltageSensorCoolantLevel";
BA_ "LongName" SG_ 1106 VoltageSensorCoolantLevel "VoltageSensorCoolantLevel";
BA_ "SysSignalName" SG_ 1106 VoltageSensorCoolantLevel "VoltageSensorCoolantLevel";
BA_ "CompuMethodName" SG_ 1196 StatusDiagnosticValveHighVoltage0 "StatusDiagnosticValveHighVoltageStorage";
BA_ "ISignalName" SG_ 1196 StatusDiagnosticValveHighVoltage0 "StatusDiagnosticValveHighVoltageStorage1";
BA_ "LongName" SG_ 1196 StatusDiagnosticValveHighVoltage0 "StatusDiagnosticValveHighVoltageStorage1";
BA_ "SysSignalName" SG_ 1196 StatusDiagnosticValveHighVoltage0 "StatusDiagnosticValveHighVoltageStorage1";
BA_ "SystemSignalLongSymbol" SG_ 1196 StatusDiagnosticValveHighVoltage0 "StatusDiagnosticValveHighVoltageStorage1";
BA_ "CompuMethodName" SG_ 1196 StatusDiagnosticValveHighVoltage1 "StatusDiagnosticValveHighVoltageStorage";
BA_ "ISignalName" SG_ 1196 StatusDiagnosticValveHighVoltage1 "StatusDiagnosticValveHighVoltageStorage2";
BA_ "LongName" SG_ 1196 StatusDiagnosticValveHighVoltage1 "StatusDiagnosticValveHighVoltageStorage2";
BA_ "SysSignalName" SG_ 1196 StatusDiagnosticValveHighVoltage1 "StatusDiagnosticValveHighVoltageStorage2";
BA_ "SystemSignalLongSymbol" SG_ 1196 StatusDiagnosticValveHighVoltage1 "StatusDiagnosticValveHighVoltageStorage2";
BA_ "CompuMethodName" SG_ 1196 StatusControlValveHighVoltageSto0 "StatusControlValveHighVoltageStorage";
BA_ "ISignalName" SG_ 1196 StatusControlValveHighVoltageSto0 "StatusControlValveHighVoltageStorage1";
BA_ "LongName" SG_ 1196 StatusControlValveHighVoltageSto0 "StatusControlValveHighVoltageStorage1";
BA_ "SysSignalName" SG_ 1196 StatusControlValveHighVoltageSto0 "StatusControlValveHighVoltageStorage1";
BA_ "SystemSignalLongSymbol" SG_ 1196 StatusControlValveHighVoltageSto0 "StatusControlValveHighVoltageStorage1";
BA_ "CompuMethodName" SG_ 1196 StatusControlValveHighVoltageSto1 "StatusControlValveHighVoltageStorage";
BA_ "ISignalName" SG_ 1196 StatusControlValveHighVoltageSto1 "StatusControlValveHighVoltageStorage2";
BA_ "LongName" SG_ 1196 StatusControlValveHighVoltageSto1 "StatusControlValveHighVoltageStorage2";
BA_ "SysSignalName" SG_ 1196 StatusControlValveHighVoltageSto1 "StatusControlValveHighVoltageStorage2";
BA_ "SystemSignalLongSymbol" SG_ 1196 StatusControlValveHighVoltageSto1 "StatusControlValveHighVoltageStorage2";
BA_ "CompuMethodName" SG_ 1095 StatusKeyFunction "StatusKeyFunction";
BA_ "ISignalName" SG_ 1095 StatusKeyFunction "StatusKeyFunction";
BA_ "LongName" SG_ 1095 StatusKeyFunction "StatusKeyFunction";
BA_ "SysSignalName" SG_ 1095 StatusKeyFunction "StatusKeyFunction";
BA_ "CompuMethodName" SG_ 1095 StatusKeyId "StatusKeyId";
BA_ "ISignalName" SG_ 1095 StatusKeyId "StatusKeyId";
BA_ "LongName" SG_ 1095 StatusKeyId "StatusKeyId";
BA_ "SysSignalName" SG_ 1095 StatusKeyId "StatusKeyId";
BA_ "CompuMethodName" SG_ 702 StatusPowertrainErrorSource "StatusPowertrainErrorSource";
BA_ "ISignalName" SG_ 702 StatusPowertrainErrorSource "StatusPowertrainErrorSource";
BA_ "LongName" SG_ 702 StatusPowertrainErrorSource "StatusPowertrainErrorSource";
BA_ "SysSignalName" SG_ 702 StatusPowertrainErrorSource "StatusPowertrainErrorSource";
BA_ "CompuMethodName" SG_ 1197 StatusDiagnosisFunctionalValve1S0 "StatusDiagnosisFunctional";
BA_ "ISignalName" SG_ 1197 StatusDiagnosisFunctionalValve1S0 "StatusDiagnosisFunctionalValve1StuckUp";
BA_ "LongName" SG_ 1197 StatusDiagnosisFunctionalValve1S0 "StatusDiagnosisFunctionalValve1StuckUp";
BA_ "SysSignalName" SG_ 1197 StatusDiagnosisFunctionalValve1S0 "StatusDiagnosisFunctionalValve1StuckUp";
BA_ "SystemSignalLongSymbol" SG_ 1197 StatusDiagnosisFunctionalValve1S0 "StatusDiagnosisFunctionalValve1StuckUp";
BA_ "CompuMethodName" SG_ 1197 StatusDiagnosisFunctionalValve1S1 "StatusDiagnosisFunctional";
BA_ "ISignalName" SG_ 1197 StatusDiagnosisFunctionalValve1S1 "StatusDiagnosisFunctionalValve1StuckDown";
BA_ "LongName" SG_ 1197 StatusDiagnosisFunctionalValve1S1 "StatusDiagnosisFunctionalValve1StuckDown";
BA_ "SysSignalName" SG_ 1197 StatusDiagnosisFunctionalValve1S1 "StatusDiagnosisFunctionalValve1StuckDown";
BA_ "SystemSignalLongSymbol" SG_ 1197 StatusDiagnosisFunctionalValve1S1 "StatusDiagnosisFunctionalValve1StuckDown";
BA_ "CompuMethodName" SG_ 1197 StatusDiagnosisFunctionalCPIHigh "StatusDiagnosisFunctional";
BA_ "ISignalName" SG_ 1197 StatusDiagnosisFunctionalCPIHigh "StatusDiagnosisFunctionalCPIHighVoltageStorage1";
BA_ "LongName" SG_ 1197 StatusDiagnosisFunctionalCPIHigh "StatusDiagnosisFunctionalCPIHighVoltageStorage1";
BA_ "SysSignalName" SG_ 1197 StatusDiagnosisFunctionalCPIHigh "StatusDiagnosisFunctionalCPIHighVoltageStorage1";
BA_ "SystemSignalLongSymbol" SG_ 1197 StatusDiagnosisFunctionalCPIHigh "StatusDiagnosisFunctionalCPIHighVoltageStorage1";
BA_ "CompuMethodName" SG_ 1197 ActualValueTemperatureHighVoltag0 "ActualValueTemperatureHighVoltageStorage";
BA_ "GenSigStartValue" SG_ 1197 ActualValueTemperatureHighVoltag0 80;
BA_ "ISignalName" SG_ 1197 ActualValueTemperatureHighVoltag0 "ActualValueTemperatureHighVoltageStorageMean1";
BA_ "LongName" SG_ 1197 ActualValueTemperatureHighVoltag0 "ActualValueTemperatureHighVoltageStorageMean1";
BA_ "SysSignalName" SG_ 1197 ActualValueTemperatureHighVoltag0 "ActualValueTemperatureHighVoltageStorageMean1";
BA_ "SystemSignalLongSymbol" SG_ 1197 ActualValueTemperatureHighVoltag0 "ActualValueTemperatureHighVoltageStorageMean1";
BA_ "CompuMethodName" SG_ 1197 ActualValueTemperatureHighVoltag1 "ActualValueTemperatureHighVoltageStorage";
BA_ "GenSigStartValue" SG_ 1197 ActualValueTemperatureHighVoltag1 80;
BA_ "ISignalName" SG_ 1197 ActualValueTemperatureHighVoltag1 "ActualValueTemperatureHighVoltageStorageMinimum1";
BA_ "LongName" SG_ 1197 ActualValueTemperatureHighVoltag1 "ActualValueTemperatureHighVoltageStorageMinimum1";
BA_ "SysSignalName" SG_ 1197 ActualValueTemperatureHighVoltag1 "ActualValueTemperatureHighVoltageStorageMinimum1";
BA_ "SystemSignalLongSymbol" SG_ 1197 ActualValueTemperatureHighVoltag1 "ActualValueTemperatureHighVoltageStorageMinimum1";
BA_ "CompuMethodName" SG_ 1197 ActualValueTemperatureHighVoltag2 "ActualValueTemperatureHighVoltageStorage";
BA_ "GenSigStartValue" SG_ 1197 ActualValueTemperatureHighVoltag2 80;
BA_ "ISignalName" SG_ 1197 ActualValueTemperatureHighVoltag2 "ActualValueTemperatureHighVoltageStorageMaximum1";
BA_ "LongName" SG_ 1197 ActualValueTemperatureHighVoltag2 "ActualValueTemperatureHighVoltageStorageMaximum1";
BA_ "SysSignalName" SG_ 1197 ActualValueTemperatureHighVoltag2 "ActualValueTemperatureHighVoltageStorageMaximum1";
BA_ "SystemSignalLongSymbol" SG_ 1197 ActualValueTemperatureHighVoltag2 "ActualValueTemperatureHighVoltageStorageMaximum1";
BA_ "CompuMethodName" SG_ 1197 ActualValueTemperatureHeatExchan "ActualValueTemperatureHeatExchangerHighVoltageStorage1";
BA_ "GenSigStartValue" SG_ 1197 ActualValueTemperatureHeatExchan -40;
BA_ "ISignalName" SG_ 1197 ActualValueTemperatureHeatExchan "ActualValueTemperatureHeatExchangerHighVoltageStorage1";
BA_ "LongName" SG_ 1197 ActualValueTemperatureHeatExchan "ActualValueTemperatureHeatExchangerHighVoltageStorage1";
BA_ "SysSignalName" SG_ 1197 ActualValueTemperatureHeatExchan "ActualValueTemperatureHeatExchangerHighVoltageStorage1";
BA_ "SystemSignalLongSymbol" SG_ 1197 ActualValueTemperatureHeatExchan "ActualValueTemperatureHeatExchangerHighVoltageStorage1";
BA_ "CompuMethodName" SG_ 1197 RequestValveHighVoltageStorage1 "RequestValveHighVoltageStorage1";
BA_ "ISignalName" SG_ 1197 RequestValveHighVoltageStorage1 "RequestValveHighVoltageStorage1";
BA_ "LongName" SG_ 1197 RequestValveHighVoltageStorage1 "RequestValveHighVoltageStorage1";
BA_ "SysSignalName" SG_ 1197 RequestValveHighVoltageStorage1 "RequestValveHighVoltageStorage1";
BA_ "CompuMethodName" SG_ 1194 StatusDiagnosisFunctionalValve2S0 "StatusDiagnosisFunctional";
BA_ "ISignalName" SG_ 1194 StatusDiagnosisFunctionalValve2S0 "StatusDiagnosisFunctionalValve2StuckUp";
BA_ "LongName" SG_ 1194 StatusDiagnosisFunctionalValve2S0 "StatusDiagnosisFunctionalValve2StuckUp";
BA_ "SysSignalName" SG_ 1194 StatusDiagnosisFunctionalValve2S0 "StatusDiagnosisFunctionalValve2StuckUp";
BA_ "SystemSignalLongSymbol" SG_ 1194 StatusDiagnosisFunctionalValve2S0 "StatusDiagnosisFunctionalValve2StuckUp";
BA_ "CompuMethodName" SG_ 1194 StatusDiagnosisFunctionalValve2S1 "StatusDiagnosisFunctional";
BA_ "ISignalName" SG_ 1194 StatusDiagnosisFunctionalValve2S1 "StatusDiagnosisFunctionalValve2StuckDown";
BA_ "LongName" SG_ 1194 StatusDiagnosisFunctionalValve2S1 "StatusDiagnosisFunctionalValve2StuckDown";
BA_ "SysSignalName" SG_ 1194 StatusDiagnosisFunctionalValve2S1 "StatusDiagnosisFunctionalValve2StuckDown";
BA_ "SystemSignalLongSymbol" SG_ 1194 StatusDiagnosisFunctionalValve2S1 "StatusDiagnosisFunctionalValve2StuckDown";
BA_ "CompuMethodName" SG_ 1194 StatusDiagnosisFunctionalCPIHigh "StatusDiagnosisFunctional";
BA_ "ISignalName" SG_ 1194 StatusDiagnosisFunctionalCPIHigh "StatusDiagnosisFunctionalCPIHighVoltageStorage2";
BA_ "LongName" SG_ 1194 StatusDiagnosisFunctionalCPIHigh "StatusDiagnosisFunctionalCPIHighVoltageStorage2";
BA_ "SysSignalName" SG_ 1194 StatusDiagnosisFunctionalCPIHigh "StatusDiagnosisFunctionalCPIHighVoltageStorage2";
BA_ "SystemSignalLongSymbol" SG_ 1194 StatusDiagnosisFunctionalCPIHigh "StatusDiagnosisFunctionalCPIHighVoltageStorage2";
BA_ "CompuMethodName" SG_ 1194 ActualValueTemperatureHighVoltag0 "ActualValueTemperatureHighVoltageStorage";
BA_ "GenSigStartValue" SG_ 1194 ActualValueTemperatureHighVoltag0 80;
BA_ "ISignalName" SG_ 1194 ActualValueTemperatureHighVoltag0 "ActualValueTemperatureHighVoltageStorageMean2";
BA_ "LongName" SG_ 1194 ActualValueTemperatureHighVoltag0 "ActualValueTemperatureHighVoltageStorageMean2";
BA_ "SysSignalName" SG_ 1194 ActualValueTemperatureHighVoltag0 "ActualValueTemperatureHighVoltageStorageMean2";
BA_ "SystemSignalLongSymbol" SG_ 1194 ActualValueTemperatureHighVoltag0 "ActualValueTemperatureHighVoltageStorageMean2";
BA_ "CompuMethodName" SG_ 1194 ActualValueTemperatureHighVoltag1 "ActualValueTemperatureHighVoltageStorage";
BA_ "GenSigStartValue" SG_ 1194 ActualValueTemperatureHighVoltag1 80;
BA_ "ISignalName" SG_ 1194 ActualValueTemperatureHighVoltag1 "ActualValueTemperatureHighVoltageStorageMinimum2";
BA_ "LongName" SG_ 1194 ActualValueTemperatureHighVoltag1 "ActualValueTemperatureHighVoltageStorageMinimum2";
BA_ "SysSignalName" SG_ 1194 ActualValueTemperatureHighVoltag1 "ActualValueTemperatureHighVoltageStorageMinimum2";
BA_ "SystemSignalLongSymbol" SG_ 1194 ActualValueTemperatureHighVoltag1 "ActualValueTemperatureHighVoltageStorageMinimum2";
BA_ "CompuMethodName" SG_ 1194 ActualValueTemperatureHighVoltag2 "ActualValueTemperatureHighVoltageStorage";
BA_ "GenSigStartValue" SG_ 1194 ActualValueTemperatureHighVoltag2 80;
BA_ "ISignalName" SG_ 1194 ActualValueTemperatureHighVoltag2 "ActualValueTemperatureHighVoltageStorageMaximum2";
BA_ "LongName" SG_ 1194 ActualValueTemperatureHighVoltag2 "ActualValueTemperatureHighVoltageStorageMaximum2";
BA_ "SysSignalName" SG_ 1194 ActualValueTemperatureHighVoltag2 "ActualValueTemperatureHighVoltageStorageMaximum2";
BA_ "SystemSignalLongSymbol" SG_ 1194 ActualValueTemperatureHighVoltag2 "ActualValueTemperatureHighVoltageStorageMaximum2";
BA_ "CompuMethodName" SG_ 1194 ActualValueTemperatureHeatExchan "ActualValueTemperatureHeatExchangerHighVoltageStorage1";
BA_ "GenSigStartValue" SG_ 1194 ActualValueTemperatureHeatExchan -40;
BA_ "ISignalName" SG_ 1194 ActualValueTemperatureHeatExchan "ActualValueTemperatureHeatExchangerHighVoltageStorage2";
BA_ "LongName" SG_ 1194 ActualValueTemperatureHeatExchan "ActualValueTemperatureHeatExchangerHighVoltageStorage2";
BA_ "SysSignalName" SG_ 1194 ActualValueTemperatureHeatExchan "ActualValueTemperatureHeatExchangerHighVoltageStorage2";
BA_ "SystemSignalLongSymbol" SG_ 1194 ActualValueTemperatureHeatExchan "ActualValueTemperatureHeatExchangerHighVoltageStorage2";
BA_ "CompuMethodName" SG_ 1194 RequestValveHighVoltageStorage2 "RequestValveHighVoltageStorage1";
BA_ "ISignalName" SG_ 1194 RequestValveHighVoltageStorage2 "RequestValveHighVoltageStorage2";
BA_ "LongName" SG_ 1194 RequestValveHighVoltageStorage2 "RequestValveHighVoltageStorage2";
BA_ "SysSignalName" SG_ 1194 RequestValveHighVoltageStorage2 "RequestValveHighVoltageStorage2";
BA_ "CompuMethodName" SG_ 883 FLLV_FUTA_2 "FLLV_FUTA_2";
BA_ "ISignalName" SG_ 883 FLLV_FUTA_2 "FLLV_FUTA_2";
BA_ "LongName" SG_ 883 FLLV_FUTA_2 "Füllstand_Tank_2";
BA_ "SysSignalName" SG_ 883 FLLV_FUTA_2 "FLLV_FUTA_2";
BA_ "CompuMethodName" SG_ 883 RNG_BT "RNG_BT";
BA_ "ISignalName" SG_ 883 RNG_BT "RNG_BT";
BA_ "LongName" SG_ 883 RNG_BT "Reichweite_Batterie";
BA_ "SysSignalName" SG_ 883 RNG_BT "RNG_BT";
BA_ "CompuMethodName" SG_ 883 RNG_REX "RNG_REX";
BA_ "ISignalName" SG_ 883 RNG_REX "RNG_REX";
BA_ "LongName" SG_ 883 RNG_REX "Reichweite_Range-Extender";
BA_ "SysSignalName" SG_ 883 RNG_REX "RNG_REX";
BA_ "CompuMethodName" SG_ 858 ID_CBS "ID_CBS";
BA_ "ISignalName" SG_ 858 ID_CBS "ID_CBS";
BA_ "LongName" SG_ 858 ID_CBS "ID_CBS";
BA_ "SysSignalName" SG_ 858 ID_CBS "ID_CBS";
BA_ "CompuMethodName" SG_ 858 YR_CBS "YR_CBS";
BA_ "ISignalName" SG_ 858 YR_CBS "YR_CBS";
BA_ "LongName" SG_ 858 YR_CBS "Jahr_CBS";
BA_ "SysSignalName" SG_ 858 YR_CBS "YR_CBS";
BA_ "CompuMethodName" SG_ 858 MON_CBS "MON_CBS";
BA_ "GenSigStartValue" SG_ 858 MON_CBS 1;
BA_ "ISignalName" SG_ 858 MON_CBS "MON_CBS";
BA_ "LongName" SG_ 858 MON_CBS "Monat_CBS";
BA_ "SysSignalName" SG_ 858 MON_CBS "MON_CBS";
BA_ "CompuMethodName" SG_ 858 DayCBS "DayCBS";
BA_ "GenSigStartValue" SG_ 858 DayCBS 1;
BA_ "ISignalName" SG_ 858 DayCBS "DayCBS";
BA_ "LongName" SG_ 858 DayCBS "DayCBS";
BA_ "SysSignalName" SG_ 858 DayCBS "DayCBS";
BA_ "CompuMethodName" SG_ 355 CRC_TLT_RW "CRC8";
BA_ "ISignalName" SG_ 355 CRC_TLT_RW "CRC_TLT_RW";
BA_ "LongName" SG_ 355 CRC_TLT_RW "CRC_Neigung_Fahrbahn";
BA_ "SysSignalName" SG_ 355 CRC_TLT_RW "CRC_TLT_RW";
BA_ "CompuMethodName" SG_ 355 ALIV_TLT_RW "Aliv_4";
BA_ "ISignalName" SG_ 355 ALIV_TLT_RW "ALIV_TLT_RW";
BA_ "LongName" SG_ 355 ALIV_TLT_RW "Alive_Neigung_Fahrbahn";
BA_ "SysSignalName" SG_ 355 ALIV_TLT_RW "ALIV_TLT_RW";
BA_ "ISignalName" SG_ 355 TLT_RW_dummy_12_15 "TLT_RW_dummy_12_15";
BA_ "LongName" SG_ 355 TLT_RW_dummy_12_15 "TLT_RW_dummy_12_15";
BA_ "SysSignalName" SG_ 355 TLT_RW_dummy_12_15 "TLT_RW_dummy_12_15";
BA_ "CompuMethodName" SG_ 355 AVL_LOGR_RW "AVL_LOGR_RW";
BA_ "GenSigStartValue" SG_ 355 AVL_LOGR_RW -64;
BA_ "ISignalName" SG_ 355 AVL_LOGR_RW "AVL_LOGR_RW";
BA_ "LongName" SG_ 355 AVL_LOGR_RW "Ist_Längsneigung_Fahrbahn";
BA_ "SysSignalName" SG_ 355 AVL_LOGR_RW "AVL_LOGR_RW";
BA_ "CompuMethodName" SG_ 355 QU_AVL_LOGR_RW "QU_AVL_LOGR_RW";
BA_ "ISignalName" SG_ 355 QU_AVL_LOGR_RW "QU_AVL_LOGR_RW";
BA_ "LongName" SG_ 355 QU_AVL_LOGR_RW "Qualifier_Ist_Längsneigung_Fahrbahn";
BA_ "SysSignalName" SG_ 355 QU_AVL_LOGR_RW "QU_AVL_LOGR_RW";
BA_ "CompuMethodName" SG_ 355 AVL_TRGR_RW "AVL_TRGR_VEH";
BA_ "GenSigStartValue" SG_ 355 AVL_TRGR_RW -64;
BA_ "ISignalName" SG_ 355 AVL_TRGR_RW "AVL_TRGR_RW";
BA_ "LongName" SG_ 355 AVL_TRGR_RW "Ist_Querneigung_Fahrbahn";
BA_ "SysSignalName" SG_ 355 AVL_TRGR_RW "AVL_TRGR_RW";
BA_ "CompuMethodName" SG_ 355 QU_AVL_TRGR_RW "QU_AVL_TRGR_RW";
BA_ "ISignalName" SG_ 355 QU_AVL_TRGR_RW "QU_AVL_TRGR_RW";
BA_ "LongName" SG_ 355 QU_AVL_TRGR_RW "Qualifier_Ist_Querneigung_Fahrbahn";
BA_ "SysSignalName" SG_ 355 QU_AVL_TRGR_RW "QU_AVL_TRGR_RW";
BA_ "CompuMethodName" SG_ 355 AVL_LOGR_RW_FAST "AVL_LOGR_RW_FAST";
BA_ "GenSigStartValue" SG_ 355 AVL_LOGR_RW_FAST -64;
BA_ "ISignalName" SG_ 355 AVL_LOGR_RW_FAST "AVL_LOGR_RW_FAST";
BA_ "LongName" SG_ 355 AVL_LOGR_RW_FAST "Ist_Längsneigung_Fahrbahn_Schnell";
BA_ "SysSignalName" SG_ 355 AVL_LOGR_RW_FAST "AVL_LOGR_RW_FAST";
BA_ "ISignalName" SG_ 355 TLT_RW_dummy_60_63 "TLT_RW_dummy_60_63";
BA_ "LongName" SG_ 355 TLT_RW_dummy_60_63 "TLT_RW_dummy_60_63";
BA_ "SysSignalName" SG_ 355 TLT_RW_dummy_60_63 "TLT_RW_dummy_60_63";
BA_ "CompuMethodName" SG_ 165 CRC_TORQ_CRSH_1 "CRC8";
BA_ "ISignalName" SG_ 165 CRC_TORQ_CRSH_1 "CRC_TORQ_CRSH_1";
BA_ "LongName" SG_ 165 CRC_TORQ_CRSH_1 "CRC_Drehmoment_Kurbelwelle_1";
BA_ "SysSignalName" SG_ 165 CRC_TORQ_CRSH_1 "CRC_TORQ_CRSH_1";
BA_ "CompuMethodName" SG_ 165 ALIV_TORQ_CRSH_1 "Aliv_4";
BA_ "ISignalName" SG_ 165 ALIV_TORQ_CRSH_1 "ALIV_TORQ_CRSH_1";
BA_ "LongName" SG_ 165 ALIV_TORQ_CRSH_1 "Alive_Drehmoment_Kurbelwelle_1";
BA_ "SysSignalName" SG_ 165 ALIV_TORQ_CRSH_1 "ALIV_TORQ_CRSH_1";
BA_ "CompuMethodName" SG_ 165 ST_SAIL_DRV_2 "ST_SAIL_DRV_2";
BA_ "ISignalName" SG_ 165 ST_SAIL_DRV_2 "ST_SAIL_DRV_2";
BA_ "LongName" SG_ 165 ST_SAIL_DRV_2 "Status_Segeln_Antrieb_2";
BA_ "SysSignalName" SG_ 165 ST_SAIL_DRV_2 "ST_SAIL_DRV_2";
BA_ "CompuMethodName" SG_ 165 AVL_TORQ_CRSH "TORQ_CRSH_MOST";
BA_ "GenSigStartValue" SG_ 165 AVL_TORQ_CRSH -1024;
BA_ "ISignalName" SG_ 165 AVL_TORQ_CRSH "AVL_TORQ_CRSH";
BA_ "LongName" SG_ 165 AVL_TORQ_CRSH "Ist_Drehmoment_Kurbelwelle";
BA_ "SysSignalName" SG_ 165 AVL_TORQ_CRSH "AVL_TORQ_CRSH";
BA_ "CompuMethodName" SG_ 165 AVL_TORQ_CRSH_DMEE "TORQ_CRSH_neu";
BA_ "GenSigStartValue" SG_ 165 AVL_TORQ_CRSH_DMEE -1024;
BA_ "ISignalName" SG_ 165 AVL_TORQ_CRSH_DMEE "AVL_TORQ_CRSH_DMEE";
BA_ "LongName" SG_ 165 AVL_TORQ_CRSH_DMEE "Ist_Drehmoment_Kurbelwelle_DME/EGS";
BA_ "SysSignalName" SG_ 165 AVL_TORQ_CRSH_DMEE "AVL_TORQ_CRSH_DMEE";
BA_ "CompuMethodName" SG_ 165 AVL_RPM_ENG_CRSH "RPM_ENG";
BA_ "ISignalName" SG_ 165 AVL_RPM_ENG_CRSH "AVL_RPM_ENG_CRSH";
BA_ "LongName" SG_ 165 AVL_RPM_ENG_CRSH "Ist_Drehzahl_Motor_Kurbelwelle";
BA_ "SysSignalName" SG_ 165 AVL_RPM_ENG_CRSH "AVL_RPM_ENG_CRSH";
BA_ "CompuMethodName" SG_ 165 QU_AVL_RPM_ENG_CRSH "QU_AVL_RPM_MOT_CRSH";
BA_ "ISignalName" SG_ 165 QU_AVL_RPM_ENG_CRSH "QU_AVL_RPM_ENG_CRSH";
BA_ "LongName" SG_ 165 QU_AVL_RPM_ENG_CRSH "Qualifier_Ist_Drehzahl_Motor_Kurbelwelle";
BA_ "SysSignalName" SG_ 165 QU_AVL_RPM_ENG_CRSH "QU_AVL_RPM_ENG_CRSH";
BA_ "CompuMethodName" SG_ 165 RQ_BL_RECUP "RQ_BL_RECUP";
BA_ "ISignalName" SG_ 165 RQ_BL_RECUP "RQ_BL_RECUP";
BA_ "LongName" SG_ 165 RQ_BL_RECUP "Anforderung_Bremslicht_Rekuperation";
BA_ "SysSignalName" SG_ 165 RQ_BL_RECUP "RQ_BL_RECUP";
BA_ "CompuMethodName" SG_ 165 VRFD_RLS_TORQ_FAST "VRFD_RLS_TORQ_FAST";
BA_ "ISignalName" SG_ 165 VRFD_RLS_TORQ_FAST "VRFD_RLS_TORQ_FAST";
BA_ "LongName" SG_ 165 VRFD_RLS_TORQ_FAST "Abgesichert_Freigabe_Drehmoment_Schnell";
BA_ "SysSignalName" SG_ 165 VRFD_RLS_TORQ_FAST "VRFD_RLS_TORQ_FAST";
BA_ "CompuMethodName" SG_ 194 CRC_TORQ_CRSH_4 "CRC8";
BA_ "ISignalName" SG_ 194 CRC_TORQ_CRSH_4 "CRC_TORQ_CRSH_4";
BA_ "LongName" SG_ 194 CRC_TORQ_CRSH_4 "CRC_Drehmoment_Kurbelwelle_4";
BA_ "SysSignalName" SG_ 194 CRC_TORQ_CRSH_4 "CRC_TORQ_CRSH_4";
BA_ "CompuMethodName" SG_ 194 ALIV_TORQ_CRSH_4 "ALIV_4_BIT_Unsigned_Integer";
BA_ "ISignalName" SG_ 194 ALIV_TORQ_CRSH_4 "ALIV_TORQ_CRSH_4";
BA_ "LongName" SG_ 194 ALIV_TORQ_CRSH_4 "Alive_Drehmoment_Kurbelwelle_4";
BA_ "SysSignalName" SG_ 194 ALIV_TORQ_CRSH_4 "ALIV_TORQ_CRSH_4";
BA_ "CompuMethodName" SG_ 194 CHL_TORQ_CRSH_4 "CHL_4_UInt";
BA_ "ISignalName" SG_ 194 CHL_TORQ_CRSH_4 "CHL_TORQ_CRSH_4";
BA_ "LongName" SG_ 194 CHL_TORQ_CRSH_4 "CHL_Drehmoment_Kurbelwelle_4";
BA_ "SysSignalName" SG_ 194 CHL_TORQ_CRSH_4 "CHL_TORQ_CRSH_4";
BA_ "CompuMethodName" SG_ 194 AVL_RPM_ENG_CRSH_LOW_EPL "AVL_RPM_ENG_CRSH_LOW_EPL";
BA_ "GenSigStartValue" SG_ 194 AVL_RPM_ENG_CRSH_LOW_EPL 900;
BA_ "ISignalName" SG_ 194 AVL_RPM_ENG_CRSH_LOW_EPL "AVL_RPM_ENG_CRSH_LOW_EPL";
BA_ "LongName" SG_ 194 AVL_RPM_ENG_CRSH_LOW_EPL "Ist_Drehzahl_Motor_Kurbelwelle_Low_extrapoliert";
BA_ "SysSignalName" SG_ 194 AVL_RPM_ENG_CRSH_LOW_EPL "AVL_RPM_ENG_CRSH_LOW_EPL";
BA_ "CompuMethodName" SG_ 194 TARVL_GTIN_DRAWAY_RPM_CLT "TARVL_GTIN_DRAWAY_RPM_CLT";
BA_ "GenSigStartValue" SG_ 194 TARVL_GTIN_DRAWAY_RPM_CLT 500;
BA_ "ISignalName" SG_ 194 TARVL_GTIN_DRAWAY_RPM_CLT "TARVL_GTIN_DRAWAY_RPM_CLT";
BA_ "LongName" SG_ 194 TARVL_GTIN_DRAWAY_RPM_CLT "Sollwert_Einstieg_Anfahren_Drehzahl_Kupplung";
BA_ "SysSignalName" SG_ 194 TARVL_GTIN_DRAWAY_RPM_CLT "TARVL_GTIN_DRAWAY_RPM_CLT";
BA_ "CompuMethodName" SG_ 194 CTR_ACUS_STAG "CTR_ACUS_STAG";
BA_ "ISignalName" SG_ 194 CTR_ACUS_STAG "CTR_ACUS_STAG";
BA_ "LongName" SG_ 194 CTR_ACUS_STAG "Steuerung_Akustisch_Inszenierung";
BA_ "SysSignalName" SG_ 194 CTR_ACUS_STAG "CTR_ACUS_STAG";
BA_ "CompuMethodName" SG_ 194 QU_AVL_TORQ_CRSH "QU_AVL_TORQ_CRSH";
BA_ "ISignalName" SG_ 194 QU_AVL_TORQ_CRSH "QU_AVL_TORQ_CRSH";
BA_ "LongName" SG_ 194 QU_AVL_TORQ_CRSH "Qualifier_Ist_Drehmoment_Kurbelwelle";
BA_ "SysSignalName" SG_ 194 QU_AVL_TORQ_CRSH "QU_AVL_TORQ_CRSH";
BA_ "CompuMethodName" SG_ 194 StatusDriveDestination2 "StatusDriveDestination2";
BA_ "ISignalName" SG_ 194 StatusDriveDestination2 "StatusDriveDestination2";
BA_ "LongName" SG_ 194 StatusDriveDestination2 "StatusDriveDestination2";
BA_ "SysSignalName" SG_ 194 StatusDriveDestination2 "StatusDriveDestination2";
BA_ "CompuMethodName" SG_ 194 StatusDriveTarget2 "StatusDriveDestination2";
BA_ "ISignalName" SG_ 194 StatusDriveTarget2 "StatusDriveTarget2";
BA_ "LongName" SG_ 194 StatusDriveTarget2 "StatusDriveTarget2";
BA_ "SysSignalName" SG_ 194 StatusDriveTarget2 "StatusDriveTarget2";
BA_ "CompuMethodName" SG_ 760 DISP_HR "DISP_HR";
BA_ "ISignalName" SG_ 760 DISP_HR "DISP_HR";
BA_ "LongName" SG_ 760 DISP_HR "Anzeige_Stunde";
BA_ "SysSignalName" SG_ 760 DISP_HR "DISP_HR";
BA_ "CompuMethodName" SG_ 760 DISP_MN "DISP_MN";
BA_ "ISignalName" SG_ 760 DISP_MN "DISP_MN";
BA_ "LongName" SG_ 760 DISP_MN "Anzeige_Minute";
BA_ "SysSignalName" SG_ 760 DISP_MN "DISP_MN";
BA_ "CompuMethodName" SG_ 760 DISP_SEC "DISP_SEC";
BA_ "ISignalName" SG_ 760 DISP_SEC "DISP_SEC";
BA_ "LongName" SG_ 760 DISP_SEC "Anzeige_Sekunde";
BA_ "SysSignalName" SG_ 760 DISP_SEC "DISP_SEC";
BA_ "CompuMethodName" SG_ 760 DISP_DATE_DAY "DISP_DATE_DAY";
BA_ "GenSigStartValue" SG_ 760 DISP_DATE_DAY 1;
BA_ "ISignalName" SG_ 760 DISP_DATE_DAY "DISP_DATE_DAY";
BA_ "LongName" SG_ 760 DISP_DATE_DAY "Anzeige_Datum_Tag";
BA_ "SysSignalName" SG_ 760 DISP_DATE_DAY "DISP_DATE_DAY";
BA_ "CompuMethodName" SG_ 760 DISP_DATE_WDAY "DISP_DATE_WDAY";
BA_ "ISignalName" SG_ 760 DISP_DATE_WDAY "DISP_DATE_WDAY";
BA_ "LongName" SG_ 760 DISP_DATE_WDAY "Anzeige_Datum_Wochentag";
BA_ "SysSignalName" SG_ 760 DISP_DATE_WDAY "DISP_DATE_WDAY";
BA_ "CompuMethodName" SG_ 760 DISP_DATE_MON "DISP_DATE_MON";
BA_ "GenSigStartValue" SG_ 760 DISP_DATE_MON 1;
BA_ "ISignalName" SG_ 760 DISP_DATE_MON "DISP_DATE_MON";
BA_ "LongName" SG_ 760 DISP_DATE_MON "Anzeige_Datum_Monat";
BA_ "SysSignalName" SG_ 760 DISP_DATE_MON "DISP_DATE_MON";
BA_ "CompuMethodName" SG_ 760 DISP_DATE_YR "DISP_DATE_YR";
BA_ "GenSigStartValue" SG_ 760 DISP_DATE_YR 1;
BA_ "ISignalName" SG_ 760 DISP_DATE_YR "DISP_DATE_YR";
BA_ "LongName" SG_ 760 DISP_DATE_YR "Anzeige_Datum_Jahr";
BA_ "SysSignalName" SG_ 760 DISP_DATE_YR "DISP_DATE_YR";
BA_ "CompuMethodName" SG_ 760 ST_DISP_CTI_DATE "ST_DISP_CTI_DATE";
BA_ "ISignalName" SG_ 760 ST_DISP_CTI_DATE "ST_DISP_CTI_DATE";
BA_ "LongName" SG_ 760 ST_DISP_CTI_DATE "Status_Anzeige_Uhrzeit_Datum";
BA_ "SysSignalName" SG_ 760 ST_DISP_CTI_DATE "ST_DISP_CTI_DATE";
BA_ "CompuMethodName" SG_ 826 HR_UTC "HR_UTC";
BA_ "ISignalName" SG_ 826 HR_UTC "HR_UTC";
BA_ "LongName" SG_ 826 HR_UTC "Stunde_UTC";
BA_ "SysSignalName" SG_ 826 HR_UTC "HR_UTC";
BA_ "CompuMethodName" SG_ 826 MN_UTC "MN_UTC";
BA_ "ISignalName" SG_ 826 MN_UTC "MN_UTC";
BA_ "LongName" SG_ 826 MN_UTC "Minute_UTC";
BA_ "SysSignalName" SG_ 826 MN_UTC "MN_UTC";
BA_ "CompuMethodName" SG_ 826 SEC_UTC "SEC_UTC";
BA_ "ISignalName" SG_ 826 SEC_UTC "SEC_UTC";
BA_ "LongName" SG_ 826 SEC_UTC "second_UTC";
BA_ "SysSignalName" SG_ 826 SEC_UTC "SEC_UTC";
BA_ "CompuMethodName" SG_ 826 DATE_DAY_UTC "DATE_DAY_UTC";
BA_ "GenSigStartValue" SG_ 826 DATE_DAY_UTC 1;
BA_ "ISignalName" SG_ 826 DATE_DAY_UTC "DATE_DAY_UTC";
BA_ "LongName" SG_ 826 DATE_DAY_UTC "Datum_Tag_UTC";
BA_ "SysSignalName" SG_ 826 DATE_DAY_UTC "DATE_DAY_UTC";
BA_ "CompuMethodName" SG_ 826 ST_CTI_DATE_UTC "ST_CTI_DATE_UTC";
BA_ "ISignalName" SG_ 826 ST_CTI_DATE_UTC "ST_CTI_DATE_UTC";
BA_ "LongName" SG_ 826 ST_CTI_DATE_UTC "Status_Uhrzeit_Datum_UTC";
BA_ "SysSignalName" SG_ 826 ST_CTI_DATE_UTC "ST_CTI_DATE_UTC";
BA_ "CompuMethodName" SG_ 826 DATE_MON_UTC "DATE_MON_UTC";
BA_ "GenSigStartValue" SG_ 826 DATE_MON_UTC 1;
BA_ "ISignalName" SG_ 826 DATE_MON_UTC "DATE_MON_UTC";
BA_ "LongName" SG_ 826 DATE_MON_UTC "Datum_Monat_UTC";
BA_ "SysSignalName" SG_ 826 DATE_MON_UTC "DATE_MON_UTC";
BA_ "CompuMethodName" SG_ 826 DATE_YR_UTC "DATE_YR_UTC";
BA_ "GenSigStartValue" SG_ 826 DATE_YR_UTC 1;
BA_ "ISignalName" SG_ 826 DATE_YR_UTC "DATE_YR_UTC";
BA_ "LongName" SG_ 826 DATE_YR_UTC "Datum_Jahr_UTC";
BA_ "SysSignalName" SG_ 826 DATE_YR_UTC "DATE_YR_UTC";
BA_ "CompuMethodName" SG_ 826 TZS_OFFS_AUTOMLY_UTC "TZS_OFFS";
BA_ "GenSigStartValue" SG_ 826 TZS_OFFS_AUTOMLY_UTC -20;
BA_ "ISignalName" SG_ 826 TZS_OFFS_AUTOMLY_UTC "TZS_OFFS_AUTOMLY_UTC";
BA_ "LongName" SG_ 826 TZS_OFFS_AUTOMLY_UTC "Zeitzonen_Offset_Automatisch_UTC";
BA_ "SysSignalName" SG_ 826 TZS_OFFS_AUTOMLY_UTC "TZS_OFFS_AUTOMLY_UTC";
BA_ "CompuMethodName" SG_ 826 OFFS_WIT_SUT_UTC "OFFS_WIT_SUT_UTC";
BA_ "GenSigStartValue" SG_ 826 OFFS_WIT_SUT_UTC -3;
BA_ "ISignalName" SG_ 826 OFFS_WIT_SUT_UTC "OFFS_WIT_SUT_UTC";
BA_ "LongName" SG_ 826 OFFS_WIT_SUT_UTC "Offset_Winterzeit_Sommerzeit_UTC";
BA_ "SysSignalName" SG_ 826 OFFS_WIT_SUT_UTC "OFFS_WIT_SUT_UTC";
BA_ "CompuMethodName" SG_ 772 U_IBS "U_IBS";
BA_ "ISignalName" SG_ 772 U_IBS "U_IBS";
BA_ "LongName" SG_ 772 U_IBS "Spannung_IBS";
BA_ "SysSignalName" SG_ 772 U_IBS "U_IBS";
BA_ "CompuMethodName" SG_ 772 ST_STRY_U_PWMG "ST_STRY_U_PWMG";
BA_ "ISignalName" SG_ 772 ST_STRY_U_PWMG "ST_STRY_U_PWMG";
BA_ "LongName" SG_ 772 ST_STRY_U_PWMG "Status_Strategie_Spannung_Powermanagement";
BA_ "SysSignalName" SG_ 772 ST_STRY_U_PWMG "ST_STRY_U_PWMG";
BA_ "CompuMethodName" SG_ 415 CRC_VYAW_VEH "CRC8";
BA_ "ISignalName" SG_ 415 CRC_VYAW_VEH "CRC_VYAW_VEH";
BA_ "LongName" SG_ 415 CRC_VYAW_VEH "CRC_Giergeschwindigkeit_Fahrzeug";
BA_ "SysSignalName" SG_ 415 CRC_VYAW_VEH "CRC_VYAW_VEH";
BA_ "CompuMethodName" SG_ 415 ALIV_VYAW_VEH "Aliv_4";
BA_ "ISignalName" SG_ 415 ALIV_VYAW_VEH "ALIV_VYAW_VEH";
BA_ "LongName" SG_ 415 ALIV_VYAW_VEH "Alive_Giergeschwindigkeit_Fahrzeug";
BA_ "SysSignalName" SG_ 415 ALIV_VYAW_VEH "ALIV_VYAW_VEH";
BA_ "ISignalName" SG_ 415 VYAW_VEH_dummy_12_15 "VYAW_VEH_dummy_12_15";
BA_ "LongName" SG_ 415 VYAW_VEH_dummy_12_15 "VYAW_VEH_dummy_12_15";
BA_ "SysSignalName" SG_ 415 VYAW_VEH_dummy_12_15 "VYAW_VEH_dummy_12_15";
BA_ "CompuMethodName" SG_ 415 VYAW_VEH "VYAW_VEH";
BA_ "GenSigStartValue" SG_ 415 VYAW_VEH -164;
BA_ "ISignalName" SG_ 415 VYAW_VEH "VYAW_VEH";
BA_ "LongName" SG_ 415 VYAW_VEH "Giergeschwindigkeit_Fahrzeug";
BA_ "SysSignalName" SG_ 415 VYAW_VEH "VYAW_VEH";
BA_ "CompuMethodName" SG_ 415 VYAW_VEH_ERR_AMP "VYAW_VEH_ERR_AMP";
BA_ "ISignalName" SG_ 415 VYAW_VEH_ERR_AMP "VYAW_VEH_ERR_AMP";
BA_ "LongName" SG_ 415 VYAW_VEH_ERR_AMP "Giergeschwindigkeit_Fahrzeug_Fehler_Amplitude";
BA_ "SysSignalName" SG_ 415 VYAW_VEH_ERR_AMP "VYAW_VEH_ERR_AMP";
BA_ "CompuMethodName" SG_ 415 QU_VYAW_VEH "QU_VYAW_VEH";
BA_ "ISignalName" SG_ 415 QU_VYAW_VEH "QU_VYAW_VEH";
BA_ "LongName" SG_ 415 QU_VYAW_VEH "Qualifier_Giergeschwindigkeit_Fahrzeug";
BA_ "SysSignalName" SG_ 415 QU_VYAW_VEH "QU_VYAW_VEH";
BA_ "CompuMethodName" SG_ 417 CRC_V_VEH "CRC_V_VEH";
BA_ "ISignalName" SG_ 417 CRC_V_VEH "CRC_V_VEH";
BA_ "LongName" SG_ 417 CRC_V_VEH "CRC_Geschwindigkeit_Fahrzeug";
BA_ "SysSignalName" SG_ 417 CRC_V_VEH "CRC_V_VEH";
BA_ "CompuMethodName" SG_ 417 ALIV_V_VEH "Aliv_4";
BA_ "ISignalName" SG_ 417 ALIV_V_VEH "ALIV_V_VEH";
BA_ "LongName" SG_ 417 ALIV_V_VEH "Alive_Geschwindigkeit_Fahrzeug";
BA_ "SysSignalName" SG_ 417 ALIV_V_VEH "ALIV_V_VEH";
BA_ "CompuMethodName" SG_ 417 ST_V_VEH_NSS "ST_V_VEH_NSS";
BA_ "ISignalName" SG_ 417 ST_V_VEH_NSS "ST_V_VEH_NSS";
BA_ "LongName" SG_ 417 ST_V_VEH_NSS "Status_Geschwindigkeit_Fahrzeug_Stillstandsnah";
BA_ "SysSignalName" SG_ 417 ST_V_VEH_NSS "ST_V_VEH_NSS";
BA_ "CompuMethodName" SG_ 417 V_VEH_COG "V_VEH_COG";
BA_ "ISignalName" SG_ 417 V_VEH_COG "V_VEH_COG";
BA_ "LongName" SG_ 417 V_VEH_COG "Geschwindigkeit_Fahrzeug_Schwerpunkt";
BA_ "SysSignalName" SG_ 417 V_VEH_COG "V_VEH_COG";
BA_ "CompuMethodName" SG_ 417 QU_V_VEH_COG "QU_V_VEH_COG";
BA_ "ISignalName" SG_ 417 QU_V_VEH_COG "QU_V_VEH_COG";
BA_ "LongName" SG_ 417 QU_V_VEH_COG "Qualifier_Geschwindigkeit_Fahrzeug_Schwerpunkt";
BA_ "SysSignalName" SG_ 417 QU_V_VEH_COG "QU_V_VEH_COG";
BA_ "CompuMethodName" SG_ 417 DVCO_VEH "DVCO_VEH";
BA_ "ISignalName" SG_ 417 DVCO_VEH "DVCO_VEH";
BA_ "LongName" SG_ 417 DVCO_VEH "Fahrzustand_Fahrzeug";
BA_ "SysSignalName" SG_ 417 DVCO_VEH "DVCO_VEH";
BA_ "ISignalName" SG_ 417 V_VEH_dummy_39_39 "V_VEH_dummy_39_39";
BA_ "LongName" SG_ 417 V_VEH_dummy_39_39 "V_VEH_dummy_39_39";
BA_ "SysSignalName" SG_ 417 V_VEH_dummy_39_39 "V_VEH_dummy_39_39";
BA_ "CompuMethodName" SG_ 373 DRVDIR_VEH_CFD "DRVDIR_VEH_CFD";
BA_ "ISignalName" SG_ 373 DRVDIR_VEH_CFD "DRVDIR_VEH_CFD";
BA_ "LongName" SG_ 373 DRVDIR_VEH_CFD "Fahrtrichtung_Fahrzeug_Bestätigt";
BA_ "SysSignalName" SG_ 373 DRVDIR_VEH_CFD "DRVDIR_VEH_CFD";
BA_ "CompuMethodName" SG_ 373 ST_DYNOMOD "ST_DYNOMOD";
BA_ "ISignalName" SG_ 373 ST_DYNOMOD "ST_DYNOMOD";
BA_ "LongName" SG_ 373 ST_DYNOMOD "Status_Rollenmodus";
BA_ "SysSignalName" SG_ 373 ST_DYNOMOD "ST_DYNOMOD";
BA_ "CompuMethodName" SG_ 373 ST_EOLMOD "ST_EOLMOD";
BA_ "ISignalName" SG_ 373 ST_EOLMOD "ST_EOLMOD";
BA_ "LongName" SG_ 373 ST_EOLMOD "Status_Bandendemodus";
BA_ "SysSignalName" SG_ 373 ST_EOLMOD "ST_EOLMOD";
BA_ "ISignalName" SG_ 373 V_VEH_2_dummy_12_15 "V_VEH_2_dummy_12_15";
BA_ "LongName" SG_ 373 V_VEH_2_dummy_12_15 "V_VEH_2_dummy_12_15";
BA_ "SysSignalName" SG_ 373 V_VEH_2_dummy_12_15 "V_VEH_2_dummy_12_15";
BA_ "CompuMethodName" SG_ 373 DRVDIR_VEH_UCNFR "DRVDIR_VEH_UCNFR";
BA_ "ISignalName" SG_ 373 DRVDIR_VEH_UCNFR "DRVDIR_VEH_UCNFR";
BA_ "LongName" SG_ 373 DRVDIR_VEH_UCNFR "Fahrtrichtung_Fahrzeug_Unbestätigt";
BA_ "SysSignalName" SG_ 373 DRVDIR_VEH_UCNFR "DRVDIR_VEH_UCNFR";
BA_ "CompuMethodName" SG_ 373 QU_VelocityVehicleLowDynamics "Qualifier_VelocityVehicleLowDynamics";
BA_ "ISignalName" SG_ 373 QU_VelocityVehicleLowDynamics "QU_VelocityVehicleLowDynamics";
BA_ "LongName" SG_ 373 QU_VelocityVehicleLowDynamics "Qualifier_VelocityVehicleLowDynamics";
BA_ "SysSignalName" SG_ 373 QU_VelocityVehicleLowDynamics "QU_VelocityVehicleLowDynamics";
BA_ "CompuMethodName" SG_ 373 StatusVelocityCalculation "StatusVelocityCalculation";
BA_ "ISignalName" SG_ 373 StatusVelocityCalculation "StatusVelocityCalculation";
BA_ "LongName" SG_ 373 StatusVelocityCalculation "StatusVelocityCalculation";
BA_ "SysSignalName" SG_ 373 StatusVelocityCalculation "StatusVelocityCalculation";
BA_ "ISignalName" SG_ 373 V_VEH_2_dummy_30_31 "V_VEH_2_dummy_30_31";
BA_ "LongName" SG_ 373 V_VEH_2_dummy_30_31 "V_VEH_2_dummy_30_31";
BA_ "SysSignalName" SG_ 373 V_VEH_2_dummy_30_31 "V_VEH_2_dummy_30_31";
BA_ "CompuMethodName" SG_ 373 VelocityVehicleLowDynamics "VelocityVehicleLowDynamics";
BA_ "ISignalName" SG_ 373 VelocityVehicleLowDynamics "VelocityVehicleLowDynamics";
BA_ "LongName" SG_ 373 VelocityVehicleLowDynamics "VelocityVehicleLowDynamics";
BA_ "SysSignalName" SG_ 373 VelocityVehicleLowDynamics "VelocityVehicleLowDynamics";
BA_ "ISignalName" SG_ 373 V_VEH_2_dummy_48_51 "V_VEH_2_dummy_48_51";
BA_ "LongName" SG_ 373 V_VEH_2_dummy_48_51 "V_VEH_2_dummy_48_51";
BA_ "SysSignalName" SG_ 373 V_VEH_2_dummy_48_51 "V_VEH_2_dummy_48_51";
BA_ "CompuMethodName" SG_ 373 ALIV_V_VEH_2 "Aliv_4";
BA_ "ISignalName" SG_ 373 ALIV_V_VEH_2 "ALIV_V_VEH_2";
BA_ "LongName" SG_ 373 ALIV_V_VEH_2 "Alive_Geschwindigkeit_Fahrzeug_2";
BA_ "SysSignalName" SG_ 373 ALIV_V_VEH_2 "ALIV_V_VEH_2";
BA_ "CompuMethodName" SG_ 373 CRC_V_VEH_2 "CRC8";
BA_ "ISignalName" SG_ 373 CRC_V_VEH_2 "CRC_V_VEH_2";
BA_ "LongName" SG_ 373 CRC_V_VEH_2 "CRC_Geschwindigkeit_Fahrzeug_2";
BA_ "SysSignalName" SG_ 373 CRC_V_VEH_2 "CRC_V_VEH_2";
BA_ "CompuMethodName" SG_ 1037 ST_STAGMST "ST_STAGMST";
BA_ "ISignalName" SG_ 1037 ST_STAGMST "ST_STAGMST";
BA_ "LongName" SG_ 1037 ST_STAGMST "Status_Inszenierungsmaster";
BA_ "SysSignalName" SG_ 1037 ST_STAGMST "ST_STAGMST";
BA_ "CompuMethodName" SG_ 1037 TR_STAG_HU "TR_STAG_HU";
BA_ "ISignalName" SG_ 1037 TR_STAG_HU "TR_STAG_HU";
BA_ "LongName" SG_ 1037 TR_STAG_HU "Trigger_Inszenierung_Head-Unit";
BA_ "SysSignalName" SG_ 1037 TR_STAG_HU "TR_STAG_HU";
BA_ "CompuMethodName" SG_ 550 INT_RN "INT_RN";
BA_ "ISignalName" SG_ 550 INT_RN "INT_RN";
BA_ "LongName" SG_ 550 INT_RN "Intensität_Regen";
BA_ "SysSignalName" SG_ 550 INT_RN "INT_RN";
BA_ "CompuMethodName" SG_ 550 V_WI "V_WI";
BA_ "GenSigStartValue" SG_ 550 V_WI 35;
BA_ "ISignalName" SG_ 550 V_WI "V_WI";
BA_ "LongName" SG_ 550 V_WI "Geschwindigkeit_Wischer";
BA_ "SysSignalName" SG_ 550 V_WI "V_WI";
BA_ "CompuMethodName" SG_ 550 ST_RNSE "ST_RNSE";
BA_ "ISignalName" SG_ 550 ST_RNSE "ST_RNSE";
BA_ "LongName" SG_ 550 ST_RNSE "Status_Regensensor";
BA_ "SysSignalName" SG_ 550 ST_RNSE "ST_RNSE";
BA_ "CompuMethodName" SG_ 143 CRC_WMOM_DRV_1 "CRC8";
BA_ "ISignalName" SG_ 143 CRC_WMOM_DRV_1 "CRC_WMOM_DRV_1";
BA_ "LongName" SG_ 143 CRC_WMOM_DRV_1 "CRC_Radmoment_Antrieb_1";
BA_ "SysSignalName" SG_ 143 CRC_WMOM_DRV_1 "CRC_WMOM_DRV_1";
BA_ "CompuMethodName" SG_ 143 ALIV_WMOM_DRV_1 "ALIV_COU_4";
BA_ "ISignalName" SG_ 143 ALIV_WMOM_DRV_1 "ALIV_WMOM_DRV_1";
BA_ "LongName" SG_ 143 ALIV_WMOM_DRV_1 "Alive_Radmoment_Antrieb_1";
BA_ "SysSignalName" SG_ 143 ALIV_WMOM_DRV_1 "ALIV_WMOM_DRV_1";
BA_ "CompuMethodName" SG_ 143 DV_AVAI_FAST "DV_AVAI_FAST";
BA_ "ISignalName" SG_ 143 DV_AVAI_FAST "DV_AVAI_FAST";
BA_ "LongName" SG_ 143 DV_AVAI_FAST "Fahrer_Verfügbarkeit_Schnell";
BA_ "SysSignalName" SG_ 143 DV_AVAI_FAST "DV_AVAI_FAST";
BA_ "CompuMethodName" SG_ 143 AVL_WMOM_PT_SUM "UI_16_noIniVal_noDflVal_65535_1_MI_32000_noEnc_hasRng";
BA_ "GenSigStartValue" SG_ 143 AVL_WMOM_PT_SUM 32000;
BA_ "ISignalName" SG_ 143 AVL_WMOM_PT_SUM "AVL_WMOM_PT_SUM";
BA_ "LongName" SG_ 143 AVL_WMOM_PT_SUM "Ist_Radmoment_Antriebsstrang_Summe";
BA_ "SysSignalName" SG_ 143 AVL_WMOM_PT_SUM "AVL_WMOM_PT_SUM";
BA_ "CompuMethodName" SG_ 143 QU_AVL_WMOM_PT_SUM "QU_AVL_WMOM_PT_SUM";
BA_ "ISignalName" SG_ 143 QU_AVL_WMOM_PT_SUM "QU_AVL_WMOM_PT_SUM";
BA_ "LongName" SG_ 143 QU_AVL_WMOM_PT_SUM "Qualifier_Ist_Radmoment_Antriebsstrang_Summe";
BA_ "SysSignalName" SG_ 143 QU_AVL_WMOM_PT_SUM "QU_AVL_WMOM_PT_SUM";
BA_ "CompuMethodName" SG_ 143 AVL_WMOM_PT_SUM_ERR_AMP "AVL_WMOM_PT_SUM_ERR_AMP";
BA_ "ISignalName" SG_ 143 AVL_WMOM_PT_SUM_ERR_AMP "AVL_WMOM_PT_SUM_ERR_AMP";
BA_ "LongName" SG_ 143 AVL_WMOM_PT_SUM_ERR_AMP "Ist_Radmoment_Antriebsstrang_Summe_Fehler_Amplitude";
BA_ "SysSignalName" SG_ 143 AVL_WMOM_PT_SUM_ERR_AMP "AVL_WMOM_PT_SUM_ERR_AMP";
BA_ "CompuMethodName" SG_ 143 REIN_PT "REIN_PT";
BA_ "ISignalName" SG_ 143 REIN_PT "REIN_PT";
BA_ "LongName" SG_ 143 REIN_PT "Verstärkung_Antriebsstrang";
BA_ "SysSignalName" SG_ 143 REIN_PT "REIN_PT";
BA_ "CompuMethodName" SG_ 143 QU_REIN_PT "QU_REIN_PT";
BA_ "ISignalName" SG_ 143 QU_REIN_PT "QU_REIN_PT";
BA_ "LongName" SG_ 143 QU_REIN_PT "Qualifier_Verstärkung_Antriebsstrang";
BA_ "SysSignalName" SG_ 143 QU_REIN_PT "QU_REIN_PT";
BA_ "CompuMethodName" SG_ 220 CRC_WMOM_DRV_4 "CRC8";
BA_ "ISignalName" SG_ 220 CRC_WMOM_DRV_4 "CRC_WMOM_DRV_4";
BA_ "LongName" SG_ 220 CRC_WMOM_DRV_4 "CRC_Radmoment_Antrieb_4";
BA_ "SysSignalName" SG_ 220 CRC_WMOM_DRV_4 "CRC_WMOM_DRV_4";
BA_ "CompuMethodName" SG_ 220 ALIV_WMOM_DRV_4 "Aliv_4";
BA_ "ISignalName" SG_ 220 ALIV_WMOM_DRV_4 "ALIV_WMOM_DRV_4";
BA_ "LongName" SG_ 220 ALIV_WMOM_DRV_4 "Alive_Radmoment_Antrieb_4";
BA_ "SysSignalName" SG_ 220 ALIV_WMOM_DRV_4 "ALIV_WMOM_DRV_4";
BA_ "CompuMethodName" SG_ 220 ST_INTF_DRASY_TAR_LIM "ST_INTF_DRASY_TAR_LIM";
BA_ "ISignalName" SG_ 220 ST_INTF_DRASY_TAR_LIM "ST_INTF_DRASY_TAR_LIM";
BA_ "LongName" SG_ 220 ST_INTF_DRASY_TAR_LIM "Status_Schnittstelle_Fahrerassistenzsystem_Soll_Begrenzung";
BA_ "SysSignalName" SG_ 220 ST_INTF_DRASY_TAR_LIM "ST_INTF_DRASY_TAR_LIM";
BA_ "CompuMethodName" SG_ 220 ST_DRVDIR_DVCH "ST_DRVDIR_DVCH";
BA_ "ISignalName" SG_ 220 ST_DRVDIR_DVCH "ST_DRVDIR_DVCH";
BA_ "LongName" SG_ 220 ST_DRVDIR_DVCH "Status_Fahrtrichtung_Fahrerwunsch";
BA_ "SysSignalName" SG_ 220 ST_DRVDIR_DVCH "ST_DRVDIR_DVCH";
BA_ "CompuMethodName" SG_ 220 QU_AVL_RPM_BAX_RED "QU_AVL_RPM_BAX_RED";
BA_ "ISignalName" SG_ 220 QU_AVL_RPM_BAX_RED "QU_AVL_RPM_BAX_RED";
BA_ "LongName" SG_ 220 QU_AVL_RPM_BAX_RED "Qualifier_Ist_Drehzahl_Hinterachse_Redundant";
BA_ "SysSignalName" SG_ 220 QU_AVL_RPM_BAX_RED "QU_AVL_RPM_BAX_RED";
BA_ "CompuMethodName" SG_ 220 AVL_RPM_BAX_RED "RPM_GRB_NEGL_2";
BA_ "GenSigStartValue" SG_ 220 AVL_RPM_BAX_RED 2000;
BA_ "ISignalName" SG_ 220 AVL_RPM_BAX_RED "AVL_RPM_BAX_RED";
BA_ "LongName" SG_ 220 AVL_RPM_BAX_RED "Ist_Drehzahl_Hinterachse_Redundant";
BA_ "SysSignalName" SG_ 220 AVL_RPM_BAX_RED "AVL_RPM_BAX_RED";
BA_ "CompuMethodName" SG_ 220 ST_PENG_PT "ST_PENG_PT";
BA_ "ISignalName" SG_ 220 ST_PENG_PT "ST_PENG_PT";
BA_ "LongName" SG_ 220 ST_PENG_PT "Status_Kraftschluss_Antriebsstrang";
BA_ "SysSignalName" SG_ 220 ST_PENG_PT "ST_PENG_PT";
BA_ "CompuMethodName" SG_ 220 ST_AVAI_INTV_PT_DRS "ST_AVAI_INTV_PT_DRS";
BA_ "ISignalName" SG_ 220 ST_AVAI_INTV_PT_DRS "ST_AVAI_INTV_PT_DRS";
BA_ "LongName" SG_ 220 ST_AVAI_INTV_PT_DRS "Status_Verfügbarkeit_Eingriff_Antriebsstrang_FAS";
BA_ "SysSignalName" SG_ 220 ST_AVAI_INTV_PT_DRS "ST_AVAI_INTV_PT_DRS";
BA_ "CompuMethodName" SG_ 220 CTR_ACTVN_PWHOP "CTR_ACTVN_PWHOP";
BA_ "ISignalName" SG_ 220 CTR_ACTVN_PWHOP "CTR_ACTVN_PWHOP";
BA_ "LongName" SG_ 220 CTR_ACTVN_PWHOP "Steuerung_Aktivierung_Power-Hop";
BA_ "SysSignalName" SG_ 220 CTR_ACTVN_PWHOP "CTR_ACTVN_PWHOP";
BA_ "CompuMethodName" SG_ 1985 XCPDummysignalIFMDAQ1 "XCPDummysignalIFMDAQ";
BA_ "ISignalName" SG_ 1985 XCPDummysignalIFMDAQ1 "XCPDummysignalIFMDAQ1";
BA_ "LongName" SG_ 1985 XCPDummysignalIFMDAQ1 "XCPDummysignalIFMDAQ1";
BA_ "SysSignalName" SG_ 1985 XCPDummysignalIFMDAQ1 "XCPDummysignalIFMDAQ1";
BA_ "CompuMethodName" SG_ 1986 XCPDummysignalIFMDAQ2 "XCPDummysignalIFMDAQ";
BA_ "ISignalName" SG_ 1986 XCPDummysignalIFMDAQ2 "XCPDummysignalIFMDAQ2";
BA_ "LongName" SG_ 1986 XCPDummysignalIFMDAQ2 "XCPDummysignalIFMDAQ2";
BA_ "SysSignalName" SG_ 1986 XCPDummysignalIFMDAQ2 "XCPDummysignalIFMDAQ2";
BA_ "CompuMethodName" SG_ 1987 XCPDummysignalIFMDAQ3 "XCPDummysignalIFMDAQ";
BA_ "ISignalName" SG_ 1987 XCPDummysignalIFMDAQ3 "XCPDummysignalIFMDAQ3";
BA_ "LongName" SG_ 1987 XCPDummysignalIFMDAQ3 "XCPDummysignalIFMDAQ3";
BA_ "SysSignalName" SG_ 1987 XCPDummysignalIFMDAQ3 "XCPDummysignalIFMDAQ3";
BA_ "CompuMethodName" SG_ 1974 XCPDummysignalIFMRequest "XCPDummysignalIFMDAQ";
BA_ "ISignalName" SG_ 1974 XCPDummysignalIFMRequest "XCPDummysignalIFMRequest";
BA_ "LongName" SG_ 1974 XCPDummysignalIFMRequest "XCPDummysignalIFMRequest";
BA_ "SysSignalName" SG_ 1974 XCPDummysignalIFMRequest "XCPDummysignalIFMRequest";
BA_ "CompuMethodName" SG_ 1984 XCPDummysignalIFMResponse "XCPDummysignalIFMDAQ";
BA_ "ISignalName" SG_ 1984 XCPDummysignalIFMResponse "XCPDummysignalIFMResponse";
BA_ "LongName" SG_ 1984 XCPDummysignalIFMResponse "XCPDummysignalIFMResponse";
BA_ "SysSignalName" SG_ 1984 XCPDummysignalIFMResponse "XCPDummysignalIFMResponse";
BA_ "CompuMethodName" SG_ 1148 ZF_EGS_DIAG_1_BYTE1 "ZF_DIAG";
BA_ "ISignalName" SG_ 1148 ZF_EGS_DIAG_1_BYTE1 "ZF_EGS_DIAG_1_BYTE1";
BA_ "LongName" SG_ 1148 ZF_EGS_DIAG_1_BYTE1 "ZF_EGS_Diagnose_1_BYTE1";
BA_ "SysSignalName" SG_ 1148 ZF_EGS_DIAG_1_BYTE1 "ZF_EGS_DIAG_1_BYTE1";
BA_ "CompuMethodName" SG_ 1148 ZF_EGS_DIAG_1_BYTE2 "ZF_DIAG";
BA_ "ISignalName" SG_ 1148 ZF_EGS_DIAG_1_BYTE2 "ZF_EGS_DIAG_1_BYTE2";
BA_ "LongName" SG_ 1148 ZF_EGS_DIAG_1_BYTE2 "ZF_EGS_Diagnose_1_BYTE2";
BA_ "SysSignalName" SG_ 1148 ZF_EGS_DIAG_1_BYTE2 "ZF_EGS_DIAG_1_BYTE2";
BA_ "CompuMethodName" SG_ 1148 ZF_EGS_DIAG_1_BYTE3 "ZF_DIAG";
BA_ "ISignalName" SG_ 1148 ZF_EGS_DIAG_1_BYTE3 "ZF_EGS_DIAG_1_BYTE3";
BA_ "LongName" SG_ 1148 ZF_EGS_DIAG_1_BYTE3 "ZF_EGS_Diagnose_1_BYTE3";
BA_ "SysSignalName" SG_ 1148 ZF_EGS_DIAG_1_BYTE3 "ZF_EGS_DIAG_1_BYTE3";
BA_ "CompuMethodName" SG_ 1148 ZF_EGS_DIAG_1_BYTE4 "ZF_DIAG";
BA_ "ISignalName" SG_ 1148 ZF_EGS_DIAG_1_BYTE4 "ZF_EGS_DIAG_1_BYTE4";
BA_ "LongName" SG_ 1148 ZF_EGS_DIAG_1_BYTE4 "ZF_EGS_Diagnose_1_BYTE4";
BA_ "SysSignalName" SG_ 1148 ZF_EGS_DIAG_1_BYTE4 "ZF_EGS_DIAG_1_BYTE4";
BA_ "CompuMethodName" SG_ 1148 ZF_EGS_DIAG_1_BYTE5 "ZF_DIAG";
BA_ "ISignalName" SG_ 1148 ZF_EGS_DIAG_1_BYTE5 "ZF_EGS_DIAG_1_BYTE5";
BA_ "LongName" SG_ 1148 ZF_EGS_DIAG_1_BYTE5 "ZF_EGS_Diagnose_1_BYTE5";
BA_ "SysSignalName" SG_ 1148 ZF_EGS_DIAG_1_BYTE5 "ZF_EGS_DIAG_1_BYTE5";
BA_ "CompuMethodName" SG_ 1148 ZF_EGS_DIAG_1_BYTE6 "ZF_DIAG";
BA_ "ISignalName" SG_ 1148 ZF_EGS_DIAG_1_BYTE6 "ZF_EGS_DIAG_1_BYTE6";
BA_ "LongName" SG_ 1148 ZF_EGS_DIAG_1_BYTE6 "ZF_EGS_Diagnose_1_BYTE6";
BA_ "SysSignalName" SG_ 1148 ZF_EGS_DIAG_1_BYTE6 "ZF_EGS_DIAG_1_BYTE6";
BA_ "CompuMethodName" SG_ 1148 ZF_EGS_DIAG_1_BYTE7 "ZF_DIAG";
BA_ "ISignalName" SG_ 1148 ZF_EGS_DIAG_1_BYTE7 "ZF_EGS_DIAG_1_BYTE7";
BA_ "LongName" SG_ 1148 ZF_EGS_DIAG_1_BYTE7 "ZF_EGS_Diagnose_1_BYTE7";
BA_ "SysSignalName" SG_ 1148 ZF_EGS_DIAG_1_BYTE7 "ZF_EGS_DIAG_1_BYTE7";
BA_ "CompuMethodName" SG_ 1148 ZF_EGS_DIAG_1_BYTE8 "ZF_DIAG";
BA_ "ISignalName" SG_ 1148 ZF_EGS_DIAG_1_BYTE8 "ZF_EGS_DIAG_1_BYTE8";
BA_ "LongName" SG_ 1148 ZF_EGS_DIAG_1_BYTE8 "ZF_EGS_Diagnose_1_BYTE8";
BA_ "SysSignalName" SG_ 1148 ZF_EGS_DIAG_1_BYTE8 "ZF_EGS_DIAG_1_BYTE8";
BA_ "CompuMethodName" SG_ 1149 ZF_EGS_DIAG_2_BYTE1 "ZF_DIAG";
BA_ "ISignalName" SG_ 1149 ZF_EGS_DIAG_2_BYTE1 "ZF_EGS_DIAG_2_BYTE1";
BA_ "LongName" SG_ 1149 ZF_EGS_DIAG_2_BYTE1 "ZF_EGS_Diagnose_2_BYTE1";
BA_ "SysSignalName" SG_ 1149 ZF_EGS_DIAG_2_BYTE1 "ZF_EGS_DIAG_2_BYTE1";
BA_ "CompuMethodName" SG_ 1149 ZF_EGS_DIAG_2_BYTE2 "ZF_DIAG";
BA_ "ISignalName" SG_ 1149 ZF_EGS_DIAG_2_BYTE2 "ZF_EGS_DIAG_2_BYTE2";
BA_ "LongName" SG_ 1149 ZF_EGS_DIAG_2_BYTE2 "ZF_EGS_Diagnose_2_BYTE2";
BA_ "SysSignalName" SG_ 1149 ZF_EGS_DIAG_2_BYTE2 "ZF_EGS_DIAG_2_BYTE2";
BA_ "CompuMethodName" SG_ 1149 ZF_EGS_DIAG_2_BYTE3 "ZF_DIAG";
BA_ "ISignalName" SG_ 1149 ZF_EGS_DIAG_2_BYTE3 "ZF_EGS_DIAG_2_BYTE3";
BA_ "LongName" SG_ 1149 ZF_EGS_DIAG_2_BYTE3 "ZF_EGS_Diagnose_2_BYTE3";
BA_ "SysSignalName" SG_ 1149 ZF_EGS_DIAG_2_BYTE3 "ZF_EGS_DIAG_2_BYTE3";
BA_ "CompuMethodName" SG_ 1149 ZF_EGS_DIAG_2_BYTE4 "ZF_DIAG";
BA_ "ISignalName" SG_ 1149 ZF_EGS_DIAG_2_BYTE4 "ZF_EGS_DIAG_2_BYTE4";
BA_ "LongName" SG_ 1149 ZF_EGS_DIAG_2_BYTE4 "ZF_EGS_Diagnose_2_BYTE4";
BA_ "SysSignalName" SG_ 1149 ZF_EGS_DIAG_2_BYTE4 "ZF_EGS_DIAG_2_BYTE4";
BA_ "CompuMethodName" SG_ 1149 ZF_EGS_DIAG_2_BYTE5 "ZF_DIAG";
BA_ "ISignalName" SG_ 1149 ZF_EGS_DIAG_2_BYTE5 "ZF_EGS_DIAG_2_BYTE5";
BA_ "LongName" SG_ 1149 ZF_EGS_DIAG_2_BYTE5 "ZF_EGS_Diagnose_2_BYTE5";
BA_ "SysSignalName" SG_ 1149 ZF_EGS_DIAG_2_BYTE5 "ZF_EGS_DIAG_2_BYTE5";
BA_ "CompuMethodName" SG_ 1149 ZF_EGS_DIAG_2_BYTE6 "ZF_DIAG";
BA_ "ISignalName" SG_ 1149 ZF_EGS_DIAG_2_BYTE6 "ZF_EGS_DIAG_2_BYTE6";
BA_ "LongName" SG_ 1149 ZF_EGS_DIAG_2_BYTE6 "ZF_EGS_Diagnose_2_BYTE6";
BA_ "SysSignalName" SG_ 1149 ZF_EGS_DIAG_2_BYTE6 "ZF_EGS_DIAG_2_BYTE6";
BA_ "CompuMethodName" SG_ 1149 ZF_EGS_DIAG_2_BYTE7 "ZF_DIAG";
BA_ "ISignalName" SG_ 1149 ZF_EGS_DIAG_2_BYTE7 "ZF_EGS_DIAG_2_BYTE7";
BA_ "LongName" SG_ 1149 ZF_EGS_DIAG_2_BYTE7 "ZF_EGS_Diagnose_2_BYTE7";
BA_ "SysSignalName" SG_ 1149 ZF_EGS_DIAG_2_BYTE7 "ZF_EGS_DIAG_2_BYTE7";
BA_ "CompuMethodName" SG_ 1149 ZF_EGS_DIAG_2_BYTE8 "ZF_DIAG";
BA_ "ISignalName" SG_ 1149 ZF_EGS_DIAG_2_BYTE8 "ZF_EGS_DIAG_2_BYTE8";
BA_ "LongName" SG_ 1149 ZF_EGS_DIAG_2_BYTE8 "ZF_EGS_Diagnose_2_BYTE8";
BA_ "SysSignalName" SG_ 1149 ZF_EGS_DIAG_2_BYTE8 "ZF_EGS_DIAG_2_BYTE8";
BA_ "CompuMethodName" SG_ 1147 ZF_EGS_DIAG_3_BYTE1 "ZF_DIAG";
BA_ "ISignalName" SG_ 1147 ZF_EGS_DIAG_3_BYTE1 "ZF_EGS_DIAG_3_BYTE1";
BA_ "LongName" SG_ 1147 ZF_EGS_DIAG_3_BYTE1 "ZF_EGS_Diagnose_3_BYTE1";
BA_ "SysSignalName" SG_ 1147 ZF_EGS_DIAG_3_BYTE1 "ZF_EGS_DIAG_3_BYTE1";
BA_ "CompuMethodName" SG_ 1147 ZF_EGS_DIAG_3_BYTE2 "ZF_DIAG";
BA_ "ISignalName" SG_ 1147 ZF_EGS_DIAG_3_BYTE2 "ZF_EGS_DIAG_3_BYTE2";
BA_ "LongName" SG_ 1147 ZF_EGS_DIAG_3_BYTE2 "ZF_EGS_Diagnose_3_BYTE2";
BA_ "SysSignalName" SG_ 1147 ZF_EGS_DIAG_3_BYTE2 "ZF_EGS_DIAG_3_BYTE2";
BA_ "CompuMethodName" SG_ 1147 ZF_EGS_DIAG_3_BYTE3 "ZF_DIAG";
BA_ "ISignalName" SG_ 1147 ZF_EGS_DIAG_3_BYTE3 "ZF_EGS_DIAG_3_BYTE3";
BA_ "LongName" SG_ 1147 ZF_EGS_DIAG_3_BYTE3 "ZF_EGS_Diagnose_3_BYTE3";
BA_ "SysSignalName" SG_ 1147 ZF_EGS_DIAG_3_BYTE3 "ZF_EGS_DIAG_3_BYTE3";
BA_ "CompuMethodName" SG_ 1147 ZF_EGS_DIAG_3_BYTE4 "ZF_DIAG";
BA_ "ISignalName" SG_ 1147 ZF_EGS_DIAG_3_BYTE4 "ZF_EGS_DIAG_3_BYTE4";
BA_ "LongName" SG_ 1147 ZF_EGS_DIAG_3_BYTE4 "ZF_EGS_Diagnose_3_BYTE4";
BA_ "SysSignalName" SG_ 1147 ZF_EGS_DIAG_3_BYTE4 "ZF_EGS_DIAG_3_BYTE4";
BA_ "CompuMethodName" SG_ 1147 ZF_EGS_DIAG_3_BYTE5 "ZF_DIAG";
BA_ "ISignalName" SG_ 1147 ZF_EGS_DIAG_3_BYTE5 "ZF_EGS_DIAG_3_BYTE5";
BA_ "LongName" SG_ 1147 ZF_EGS_DIAG_3_BYTE5 "ZF_EGS_Diagnose_3_BYTE5";
BA_ "SysSignalName" SG_ 1147 ZF_EGS_DIAG_3_BYTE5 "ZF_EGS_DIAG_3_BYTE5";
BA_ "CompuMethodName" SG_ 1147 ZF_EGS_DIAG_3_BYTE6 "ZF_DIAG";
BA_ "ISignalName" SG_ 1147 ZF_EGS_DIAG_3_BYTE6 "ZF_EGS_DIAG_3_BYTE6";
BA_ "LongName" SG_ 1147 ZF_EGS_DIAG_3_BYTE6 "ZF_EGS_Diagnose_3_BYTE6";
BA_ "SysSignalName" SG_ 1147 ZF_EGS_DIAG_3_BYTE6 "ZF_EGS_DIAG_3_BYTE6";
BA_ "CompuMethodName" SG_ 1147 ZF_EGS_DIAG_3_BYTE7 "ZF_DIAG";
BA_ "ISignalName" SG_ 1147 ZF_EGS_DIAG_3_BYTE7 "ZF_EGS_DIAG_3_BYTE7";
BA_ "LongName" SG_ 1147 ZF_EGS_DIAG_3_BYTE7 "ZF_EGS_Diagnose_3_BYTE7";
BA_ "SysSignalName" SG_ 1147 ZF_EGS_DIAG_3_BYTE7 "ZF_EGS_DIAG_3_BYTE7";
BA_ "CompuMethodName" SG_ 1147 ZF_EGS_DIAG_3_BYTE8 "ZF_DIAG";
BA_ "ISignalName" SG_ 1147 ZF_EGS_DIAG_3_BYTE8 "ZF_EGS_DIAG_3_BYTE8";
BA_ "LongName" SG_ 1147 ZF_EGS_DIAG_3_BYTE8 "ZF_EGS_Diagnose_3_BYTE8";
BA_ "SysSignalName" SG_ 1147 ZF_EGS_DIAG_3_BYTE8 "ZF_EGS_DIAG_3_BYTE8";
BA_ "CompuMethodName" SG_ 1151 ZF_EGS_DIAG_4_BYTE1 "ZF_DIAG";
BA_ "ISignalName" SG_ 1151 ZF_EGS_DIAG_4_BYTE1 "ZF_EGS_DIAG_4_BYTE1";
BA_ "LongName" SG_ 1151 ZF_EGS_DIAG_4_BYTE1 "ZF_EGS_Diagnose_4_BYTE1";
BA_ "SysSignalName" SG_ 1151 ZF_EGS_DIAG_4_BYTE1 "ZF_EGS_DIAG_4_BYTE1";
BA_ "CompuMethodName" SG_ 1151 ZF_EGS_DIAG_4_BYTE2 "ZF_DIAG";
BA_ "ISignalName" SG_ 1151 ZF_EGS_DIAG_4_BYTE2 "ZF_EGS_DIAG_4_BYTE2";
BA_ "LongName" SG_ 1151 ZF_EGS_DIAG_4_BYTE2 "ZF_EGS_Diagnose_4_BYTE2";
BA_ "SysSignalName" SG_ 1151 ZF_EGS_DIAG_4_BYTE2 "ZF_EGS_DIAG_4_BYTE2";
BA_ "CompuMethodName" SG_ 1151 ZF_EGS_DIAG_4_BYTE3 "ZF_DIAG";
BA_ "ISignalName" SG_ 1151 ZF_EGS_DIAG_4_BYTE3 "ZF_EGS_DIAG_4_BYTE3";
BA_ "LongName" SG_ 1151 ZF_EGS_DIAG_4_BYTE3 "ZF_EGS_Diagnose_4_BYTE3";
BA_ "SysSignalName" SG_ 1151 ZF_EGS_DIAG_4_BYTE3 "ZF_EGS_DIAG_4_BYTE3";
BA_ "CompuMethodName" SG_ 1151 ZF_EGS_DIAG_4_BYTE4 "ZF_DIAG";
BA_ "ISignalName" SG_ 1151 ZF_EGS_DIAG_4_BYTE4 "ZF_EGS_DIAG_4_BYTE4";
BA_ "LongName" SG_ 1151 ZF_EGS_DIAG_4_BYTE4 "ZF_EGS_Diagnose_4_BYTE4";
BA_ "SysSignalName" SG_ 1151 ZF_EGS_DIAG_4_BYTE4 "ZF_EGS_DIAG_4_BYTE4";
BA_ "CompuMethodName" SG_ 1151 ZF_EGS_DIAG_4_BYTE5 "ZF_DIAG";
BA_ "ISignalName" SG_ 1151 ZF_EGS_DIAG_4_BYTE5 "ZF_EGS_DIAG_4_BYTE5";
BA_ "LongName" SG_ 1151 ZF_EGS_DIAG_4_BYTE5 "ZF_EGS_Diagnose_4_BYTE5";
BA_ "SysSignalName" SG_ 1151 ZF_EGS_DIAG_4_BYTE5 "ZF_EGS_DIAG_4_BYTE5";
BA_ "CompuMethodName" SG_ 1151 ZF_EGS_DIAG_4_BYTE6 "ZF_DIAG";
BA_ "ISignalName" SG_ 1151 ZF_EGS_DIAG_4_BYTE6 "ZF_EGS_DIAG_4_BYTE6";
BA_ "LongName" SG_ 1151 ZF_EGS_DIAG_4_BYTE6 "ZF_EGS_Diagnose_4_BYTE6";
BA_ "SysSignalName" SG_ 1151 ZF_EGS_DIAG_4_BYTE6 "ZF_EGS_DIAG_4_BYTE6";
BA_ "CompuMethodName" SG_ 1151 ZF_EGS_DIAG_4_BYTE7 "ZF_DIAG";
BA_ "ISignalName" SG_ 1151 ZF_EGS_DIAG_4_BYTE7 "ZF_EGS_DIAG_4_BYTE7";
BA_ "LongName" SG_ 1151 ZF_EGS_DIAG_4_BYTE7 "ZF_EGS_diagnosis_4_BYTE7";
BA_ "SysSignalName" SG_ 1151 ZF_EGS_DIAG_4_BYTE7 "ZF_EGS_DIAG_4_BYTE7";
BA_ "CompuMethodName" SG_ 1151 ZF_EGS_DIAG_4_BYTE8 "ZF_DIAG";
BA_ "ISignalName" SG_ 1151 ZF_EGS_DIAG_4_BYTE8 "ZF_EGS_DIAG_4_BYTE8";
BA_ "LongName" SG_ 1151 ZF_EGS_DIAG_4_BYTE8 "ZF_EGS_Diagnose_4_BYTE8";
BA_ "SysSignalName" SG_ 1151 ZF_EGS_DIAG_4_BYTE8 "ZF_EGS_DIAG_4_BYTE8";
BA_ "CompuMethodName" SG_ 1150 ZF_DIAG_EGS_1_BYTE1 "ZF_DIAG";
BA_ "ISignalName" SG_ 1150 ZF_DIAG_EGS_1_BYTE1 "ZF_DIAG_EGS_1_BYTE1";
BA_ "LongName" SG_ 1150 ZF_DIAG_EGS_1_BYTE1 "ZF_Diagnose_EGS_1_BYTE1";
BA_ "SysSignalName" SG_ 1150 ZF_DIAG_EGS_1_BYTE1 "ZF_DIAG_EGS_1_BYTE1";
BA_ "CompuMethodName" SG_ 1150 ZF_DIAG_EGS_1_BYTE2 "ZF_DIAG";
BA_ "ISignalName" SG_ 1150 ZF_DIAG_EGS_1_BYTE2 "ZF_DIAG_EGS_1_BYTE2";
BA_ "LongName" SG_ 1150 ZF_DIAG_EGS_1_BYTE2 "ZF_Diagnose_EGS_1_BYTE2";
BA_ "SysSignalName" SG_ 1150 ZF_DIAG_EGS_1_BYTE2 "ZF_DIAG_EGS_1_BYTE2";
BA_ "CompuMethodName" SG_ 1150 ZF_DIAG_EGS_1_BYTE3 "ZF_DIAG";
BA_ "ISignalName" SG_ 1150 ZF_DIAG_EGS_1_BYTE3 "ZF_DIAG_EGS_1_BYTE3";
BA_ "LongName" SG_ 1150 ZF_DIAG_EGS_1_BYTE3 "ZF_Diagnose_EGS_1_BYTE3";
BA_ "SysSignalName" SG_ 1150 ZF_DIAG_EGS_1_BYTE3 "ZF_DIAG_EGS_1_BYTE3";
BA_ "CompuMethodName" SG_ 1150 ZF_DIAG_EGS_1_BYTE4 "ZF_DIAG";
BA_ "ISignalName" SG_ 1150 ZF_DIAG_EGS_1_BYTE4 "ZF_DIAG_EGS_1_BYTE4";
BA_ "LongName" SG_ 1150 ZF_DIAG_EGS_1_BYTE4 "ZF_Diagnose_EGS_1_BYTE4";
BA_ "SysSignalName" SG_ 1150 ZF_DIAG_EGS_1_BYTE4 "ZF_DIAG_EGS_1_BYTE4";
BA_ "CompuMethodName" SG_ 1150 ZF_DIAG_EGS_1_BYTE5 "ZF_DIAG";
BA_ "ISignalName" SG_ 1150 ZF_DIAG_EGS_1_BYTE5 "ZF_DIAG_EGS_1_BYTE5";
BA_ "LongName" SG_ 1150 ZF_DIAG_EGS_1_BYTE5 "ZF_Diagnose_EGS_1_BYTE5";
BA_ "SysSignalName" SG_ 1150 ZF_DIAG_EGS_1_BYTE5 "ZF_DIAG_EGS_1_BYTE5";
BA_ "CompuMethodName" SG_ 1150 ZF_DIAG_EGS_1_BYTE6 "ZF_DIAG";
BA_ "ISignalName" SG_ 1150 ZF_DIAG_EGS_1_BYTE6 "ZF_DIAG_EGS_1_BYTE6";
BA_ "LongName" SG_ 1150 ZF_DIAG_EGS_1_BYTE6 "ZF_Diagnose_EGS_1_BYTE6";
BA_ "SysSignalName" SG_ 1150 ZF_DIAG_EGS_1_BYTE6 "ZF_DIAG_EGS_1_BYTE6";
BA_ "CompuMethodName" SG_ 1150 ZF_DIAG_EGS_1_BYTE7 "ZF_DIAG";
BA_ "ISignalName" SG_ 1150 ZF_DIAG_EGS_1_BYTE7 "ZF_DIAG_EGS_1_BYTE7";
BA_ "LongName" SG_ 1150 ZF_DIAG_EGS_1_BYTE7 "ZF_Diagnose_EGS_1_BYTE7";
BA_ "SysSignalName" SG_ 1150 ZF_DIAG_EGS_1_BYTE7 "ZF_DIAG_EGS_1_BYTE7";
BA_ "CompuMethodName" SG_ 1150 ZF_DIAG_EGS_1_BYTE8 "ZF_DIAG";
BA_ "ISignalName" SG_ 1150 ZF_DIAG_EGS_1_BYTE8 "ZF_DIAG_EGS_1_BYTE8";
BA_ "LongName" SG_ 1150 ZF_DIAG_EGS_1_BYTE8 "ZF_Diagnose_EGS_1_BYTE8";
BA_ "SysSignalName" SG_ 1150 ZF_DIAG_EGS_1_BYTE8 "ZF_DIAG_EGS_1_BYTE8";
VAL_ 888 ALIV_ST_PMA 15 "Signal ungültig";
VAL_ 888 QU_FN_PMA_POU 32 "Funktion verfügbar - Bereit PLV aktiv (SAA Aktivierung nicht möglich)" 33 "Funktion verfügbar - Bereit PLV aktiv (SAA Aktivierung durch Fahrer möglich)" 34 "Funktion verfügbar - Bereit PLV aktiv (SAA Aktivierung durch Fahrer erfolgt)" 96 "Fehler im PMA-SG" 97 "PMA wurde aufgrund eines externen Ereignisses nur vorübergehend deaktiviert" 160 "SAA aktiv" 176 "PMA-Funktionsabbruch während Einparkvorgang und Wiederaufnahme in Prüfung" 177 "PMA-Funktionsabbruch während Einparkvorgang und Wiederaufnahme möglich" 178 "PMA-Funktionsabbruch während Einparkvorgang und Wiederaufnahme erfolgt" 224 "PMA ist nicht aktiv (z.B. Geschwindigkeit Fahrzeug über 36km/h oder Rückwärtsfahren ohne Aktivierung oder endgültiger Abbruch und Wiederaufnahme nicht möglich)," 225 "Wird gesetzt solang die Funktion hochfährt" 255 "Funktion nicht vorhanden";
VAL_ 888 CTR_SUP_RSTG_DI_PMA 0 "Blinkerrückstellung unterdrücken" 2 "Keine Anforderung" 3 "Signal ungültig";
VAL_ 888 QU_FN_RVAS 16 "Funktion nicht aktiv, kein Tastenglow" 17 "unktion nicht aktiv, Aktivierungswunsch" 18 "Funktion nicht aktiv, Tastenglow" 96 "Fehler" 144 "unktion aktiv (regelnd), RFK_RFA_Linien_nicht_angezeigt" 145 "Funktion aktiv (regelnd), nicht deaktivierbar" 146 "Funktion aktiv (regelnd), RFK_RFA_Linien_angezeigt" 160 "Funktion aktiv (nicht regelnd), RFK_RFA_Linien_nicht_angezeigt" 161 "Funktion aktiv (nicht regelnd), nicht deaktivierbar" 162 "Funktion aktiv (nicht regelnd), RFK_RFA_Linien_angezeigt" 224 "Funktion_nicht_verfuegbar" 240 "Signal_unbefuellt";
VAL_ 888 QU_FN_TRAS 16 "Funktion nicht aktiv, Keine Anforderung erhoehte Frequenz Knickwinkelsuche" 17 "Funktion nicht aktiv, Aktivierungswunsch" 18 "Funktion nicht aktiv, Tastenglow" 20 "Funktion nicht aktiv, Anforderung erhoehte Frequenz Knickwinkelsuche" 111 "Sendefunktion in Betrieb, meldet Fehler" 144 "Funktion aktiv (regelnd), RFK_AHA_Linien_nicht_angezeigt" 145 "Funktion aktiv (regelnd), nicht deaktivierbar" 146 "Funktion aktiv (regelnd), RFK_AHA_Linien_angezeigt" 160 "Funktion aktiv (nicht regelnd), RFK_AHA_Linien_nicht_angezeigt" 161 "Funktion aktiv (nicht regelnd), nicht deaktivierbar" 162 "Funktion aktiv (nicht regelnd), RFK_AHA_Linien_angezeigt" 239 "Sendefunktion in Betrieb, Werte nicht verfügbar" 255 "Sendefunktion nicht in Betrieb";
VAL_ 888 QU_FN_LCL_FAS_PKG 16 "Funktion nicht aktiv, kein Tastenglow" 17 "Funktion nicht aktiv, Aktivierungswunsch" 18 "Funktion nicht aktiv, Tastenglow" 111 "Sendefunktion in Betrieb, meldet Fehler" 144 "Funktion aktiv (regelnd), deaktivierbar" 145 "Funktion aktiv (regelnd), nicht deaktivierbar" 239 "Sendefunktion in Betrieb, Werte nicht verfügbar" 255 "Sendefunktion nicht in Betrieb";
VAL_ 1159 ST_PWF_SWO_LVG_CKM 0 "Keine Angabe" 1 "Nicht aktiv" 2 "Aktiv" 3 "Signal ungültig";
VAL_ 669 RequestSBRandPreDriveCheck 0 "NoRequest" 1 "requestSBR" 2 "requestPreDriveCheck" 13 "SIGNALTAG_FCTIF_NOT_AVAILABLE" 14 "SIGNALTAG_FCT_ERROR" 15 "Sendefunktion nicht in Betrieb";
VAL_ 924 ST_RLS_ENGSTA_CARS 0 "Motorstartfreigabe_nicht_erteilt" 1 "Motorstartfreigabe_erteilt" 13 "Hinweis: Reserviert für funktionale Kennung Signal-Tag." 14 "Hinweis: Reserviert für funktionale Kennung Signal-Tag." 15 "Sendefunktion nicht in Betrieb";
VAL_ 767 ST_MONI_RN 0 "Regenschwelle überschritten" 1 "Regenschwelle nicht überschritten" 2 "Vordefinierte Zeit erreicht" 3 "Signal ungültig";
VAL_ 767 ST_ERR_RNLISE 0 "kein Regen-Licht-Sensor-Fehler detektiert" 1 "Regen-Licht-Sensor-Fehler detektiert" 3 "Signal ungültig";
VAL_ 767 ST_RN_CLO 0 "Fehler_beim_Regenschliessen" 1 "Regenschliessen_aktiviert" 2 "Kein_Fehler_beim_Regenschliessen" 13 "SIGNALTAG_FCTIF_NOT_AVAILABLE" 14 "SIGNALTAG_FCT_ERROR" 15 "Sendefunktion nicht in Betrieb";
VAL_ 619 ST_RSP_2 1 "Heckspoiler verfährt nicht - Endposition erreicht" 2 "Heckspoiler verfährt nicht - keine Endposition erreicht" 3 "Heckspoiler fährt aus - keine Endposition erreicht" 4 "Heckspoiler verfährt nicht - Endposition erreicht" 6 "Heckspoiler fährt ein - keine Endposition erreicht" 7 "Heckspoiler meldet Fehler - Diese Kodierung führt zu einer Zwangsaktivierung der dynamischen Stabilitäts Control (DSC)" 15 "Diese Kodierung führt zu einer Zwangsaktivierung der dynamischen Stabilitäts Control (DSC)";
VAL_ 619 ST_MOD_RSP 0 "Bei Verwendung Taster: Funktionsbeleuchtung AUS" 1 "Bei Verwendung Taster: Funktionsbeleuchtung EIN" 3 "Signal ungültig";
VAL_ 1101 RSU_DWA_ARM 0 "DWA_nicht_schaerfen" 1 "DWA_schaerfen" 3 "Sendefunktion nicht in Betrieb";
VAL_ 693 ST_RBKR 0 "Keine Rückrollgefahr entgegen Fahrtrichtung Fahrerwunsch beim Lösen der Bremse" 1 "Rückrollgefahr entgegen der Fahrtrichtung Fahrerwunsch beim Lösen der Bremse" 3 "Signal_unbefuellt";
VAL_ 693 ST_HHASS 0 "Anfahrassistent hält Fahrzeug nicht" 1 "Anfahrassistent hält Fahrzeug" 3 "Signal_unbefuellt";
VAL_ 693 ST_AH 0 "AutoH nicht aktiviert" 1 "AutoH aktiviert und hält Fahrzeug nicht" 2 "AutoH aktiviert und hält Fahrzeug" 3 "Signal_unbefuellt";
VAL_ 693 ST_HYD_DYN_BRKFN 0 "Hydraulisches_Dynamisches_Abbremsen_nicht_aktiv" 1 "Hydraulisches_Dynamisches_Abbremsen_aktiv" 3 "Sendefunktion nicht in Betrieb";
VAL_ 693 ST_PBRK 0 "Parkbremse mechanisch nicht festgestellt" 1 "Parkbremse mechanisch festgestellt" 2 "Parkbremse im Stellvorgang lösen" 4 "Parkbremse im Stellvorgang feststellen" 13 "SIGNALTAG_FCTIF_NOT_AVAILABLE" 14 "SIGNALTAG_FCT_ERROR" 15 "Sendefunktion nicht in Betrieb (z.B. bei nicht verbauter EPB oder Netzwerkfehlern)";
VAL_ 693 RQ_DTR_SSFN 0 "Keine Anforderung Antriebsmomentenreduzierung" 1 "Anforderung Antriebsmomentenreduzierung" 3 "Signal_unbefuellt";
VAL_ 693 ControlLedAutoHold 0 "LED_Aus" 1 "LED_Ein" 2 "AutoHold_nicht_verbaut" 3 "Sendefunktion nicht in Betrieb";
VAL_ 693 OP_PUBU_EPB 0 "Taster_nicht_betaetigt" 1 "Taster_gezogen" 2 "Taster_gedrueckt" 4 "Taster_defekt" 13 "SIGNALTAG_FCTIF_NOT_AVAILABLE" 14 "SIGNALTAG_FCT_ERROR" 15 "Sendefunktion nicht in Betrieb";
VAL_ 693 QU_FN_PCR_IBK 1 "Funktion i.O. - nicht aktiv" 6 "Sendefunktion in Betrieb, meldet Fehler" 9 "Funktion i.O. – aktiv. Fahrzeug wird verzögert oder im Stillstand gehalten durch PCiB." 14 "Sendefunktion in Betrieb, Werte nicht verfügbar. (z.B. Funktion in Sicherheitsfahrzeugen nicht verfügbar.)" 15 "Sendefunktion nicht in Betrieb";
VAL_ 371 ST_ECU_ST_STAB_DSC 0 "Normal_by_wire" 1 "Hydraulische_RFE" 2 "ACS" 3 "WAP_ok_SHP" 4 "WAP_ohne_ZPD" 5 "Reserviert" 6 "Reserviert" 7 "Reserviert" 8 "Reserviert" 9 "Reserviert" 10 "Reserviert" 11 "Reserviert" 12 "Reserviert" 13 "Reserviert" 14 "Reserviert" 15 "Signal ungültig";
VAL_ 371 QU_FN_FDR 0 "Verwendung ab SP2021 für interne Zusatzinformationen." 512 "Funktion verfügbar und bereit, nicht aktiv, Schlupfschwellen normal" 520 "Funktion verfügbar und bereit, nicht aktiv, Schlupfschwellen aufgeweitet" 768 "reserviert" 776 "reserviert" 1536 "Funktion nicht verfügbar: Fehler" 2048 "reserviert" 2560 "Funktion verfügbar und aktiv, Schlupfschwellen normal" 2568 "Funktion verfügbar und aktiv, Schlupfschwellen aufgeweitet" 2576 "Funktion verfügbar und aktiv, FDR Regeleingriff VL" 2592 "Funktion verfügbar und aktiv, FDR Regeleingriff VR" 2624 "Funktion verfügbar und aktiv, FDR Regeleingriff HL" 2688 "Funktion verfügbar und aktiv, FDR Regeleingriff HR" 3584 "Diese Codierung wird versendet wenn mind. eine dieser Bedingungen erfüllt ist: Initialisierungsphase des SG (Vorbefüllung), Zündung=aus, Motorstart, INITAusblendung aktiv, Funktion über DTC-Taster deaktiviert" 4095 "Nutzung nur vom Gateway, nicht seitens Sender-SG";
VAL_ 371 ST_BRG_MSA 0 "Diese Codierung wird erst ab MSA 2.3 verwendet" 1 "Prädiktion: Fahrzeug wird bei V = 0 gehalten" 2 "Diese Codierung wird erst ab MSA 2.3 verwendet" 4 "Diese Codierung wird erst ab MSA 2.3 verwendet" 13 "SIGNALTAG_FCTIF_NOT_AVAILABLE" 14 "SIGNALTAG_FCT_ERROR" 15 "Sendefunktion nicht in Betrieb";
VAL_ 371 ST_UNRU_DSC 0 "DSC-Aggregat im Standby" 1 "DSC-Aggregat im Hartanlauf oder im stationären Betrieb mit hoher Dynamik" 2 "DSC-Aggregat im Softanlauf oder im stationären Betrieb mit niedriger Dynamik" 3 "Signal ungültig";
VAL_ 1050 ST_ACTVN_KI_BC 0 "Keine Anzeige" 1 "Anzeige Haken Navigation Ankunftszeit und Entfernung zum Ziel" 2 "Anzeige Haken Reichweite Verbrenner" 4 "Anzeige Haken Gesamt-Reichweite" 8 "Anzeige Haken Reichweite elektrisch (Vorhalt BEV)" 16 "Anzeige Haken Reichweite elektrisch und Reichweite Verbrenner" 32 "Anzeige Haken Reichweitenpotential" 64 "Anzeige Haken Momentanverbrauch Verbrenner und Durchschnittsverbrauch Verbrenner" 128 "Anzeige Haken KVA/EVA eDrive abhaengig" 256 "Anzeige Haken Durchschnittsgeschwindigkeit und Durchschnittsverbrauch" 512 "Anzeige Haken Motortemperatur" 1024 "Anzeige Haken Efficient Dynamics Anzeige" 2048 "Anzeige M-GmbH M-Panel" 131072 "Anzeige Haken State of Charge, SOC" 1048576 "Anzeige Haken Kompass" 2097152 "Anzeige Haken eCounter und Durchschnittsverbrauch Verbrenner" 4194304 "Lifetime_Durchschnitts_und_Momentan_Verbrauch" 1073741824 "Nur in Bedienrichtung verwenden" 4294967295 "Signal ungültig";
VAL_ 1050 ST_ACTVN_KI_CONT 0 "Keine Anzeige" 1 "Anzeige Haken Fahrmodusansicht" 2 "Anzeige Haken Navigation Streckenübersicht" 4 "Anzeige Haken Zusatzschild Verkehrszeichenerkennung" 8 "Anzeige Haken Tachozeigerband für Tempolimit" 16 "Anzeige Haken Lupen Effekt Tacho" 32 "Anzeige Haken SPA" 64 "Popup" 128 "Anzeige Haken Digital-Geschwindigkeit" 256 "Anzeige Haken Analoge Uhr" 512 "Anzeige_Haken_Shiftlights" 1024 "Anzeige_Haken_Navigation" 2048 "Anzeige_Haken_Verkehrszeichenerkennung" 4096 "Anzeige_Haken_M_Drive_Inszenierung" 16384 "Nur in Bedienrichtung verwenden" 65535 "Signal ungültig";
VAL_ 1050 ST_ACTVN_PRESL_KI 0 "Diesen Radiobutton als ausgewählt darstellen" 1 "Diesen Radiobutton als ausgewählt darstellen" 2 "Diesen Radiobutton als ausgewählt darstellen" 14 "Nur in Bedienrichtung verwenden" 15 "Signal ungültig";
VAL_ 1050 ST_BRIG_OFFS_KI 0 "Nur in Bedienrichtung verwenden" 1 "minimaler Helligkeitsoffset" 2 "Helligkeitsstufe -9" 3 "Helligkeitsstufe -8" 4 "Helligkeitsstufe -7" 5 "Helligkeitsstufe -6" 6 "Helligkeitsstufe -5" 7 "Helligkeitsstufe -4" 8 "Helligkeitsstufe -3" 9 "Helligkeitsstufe -2" 10 "Helligkeitsstufe -1" 11 "kein Helligkeitsoffset" 12 "Helligkeitsstufe 1" 13 "Helligkeitsstufe 2" 14 "Helligkeitsstufe 3" 15 "Helligkeitsstufe 4" 16 "Helligkeitsstufe 5" 17 "Helligkeitsstufe 6" 18 "Helligkeitsstufe 7" 19 "Helligkeitsstufe 8" 20 "Helligkeitsstufe 9" 21 "maximaler Helligkeitsoffset" 31 "Signal ungültig";
VAL_ 1013 ST_NAVI_DISP_TYP 0 "Diesen Radiobutton als ausgewählt darstellen" 1 "Diesen Radiobutton als ausgewählt darstellen" 2 "Diesen Radiobutton als ausgewählt darstellen" 3 "Diesen Radiobutton als ausgewählt darstellen" 14 "Nur in Bedienrichtung verwenden" 15 "Sendefunktion nicht in Betrieb";
VAL_ 1013 ST_BRIG_OFFS_KI_2 0 "Nur in Bedienrichtung verwenden" 1 "minimaler Helligkeitsoffset" 2 "Helligkeitsstufe_Minus_9" 3 "Helligkeitsstufe_Minus_8" 4 "Helligkeitsstufe_Minus_7" 5 "Helligkeitsstufe_Minus_6" 6 "Helligkeitsstufe_Minus_5" 7 "Helligkeitsstufe_Minus_4" 8 "Helligkeitsstufe_Minus_3" 9 "Helligkeitsstufe_Minus_2" 10 "Helligkeitsstufe_Minus_1" 11 "kein Helligkeitsoffset" 12 "Helligkeitsstufe_Plus_1" 13 "Helligkeitsstufe_Plus_2" 14 "Helligkeitsstufe_Plus_3" 15 "Helligkeitsstufe_Plus_4" 16 "Helligkeitsstufe_Plus_5" 17 "Helligkeitsstufe_Plus_6" 18 "Helligkeitsstufe_Plus_7" 19 "Helligkeitsstufe_Plus_8" 20 "Helligkeitsstufe_Plus_9" 21 "maximaler Helligkeitsoffset" 31 "Sendefunktion nicht in Betrieb";
VAL_ 1013 ST_ENTAI_ECU_DISP 0 "Diesen Radiobutton als ausgewählt darstellen" 1 "Diesen Radiobutton als ausgewählt darstellen" 6 "Nur in Bedienrichtung verwenden" 7 "Sendefunktion nicht in Betrieb";
VAL_ 1013 StatusDZMorPowermeterDisplay 0 "Nur in Bedienrichtung verwenden" 1 "Diesen Radiobutton als ausgewählt darstellen Drehzahlmesser" 2 "Diesen Radiobutton als ausgewählt darstellen Powermeter" 15 "Signal_unbefuellt";
VAL_ 905 ST_CSOV_AIC 0 "OK" 1 "Kurzschluss nach Masse" 2 "Für SP2018BEV gilt: Leitungsunterbrechung_oder_Kurzschluss_nach_Batterie" 3 "Gilt nicht für SP2018BEV." 10 "Gilt nur für SP2018BEV." 11 "Gilt nur für SP2018BEV." 12 "Gilt nur für SP2018BEV." 13 "SIGNALTAG_FCTIF_NOT_AVAILABLE" 14 "SIGNALTAG_FCT_ERROR" 15 "Signal ungültig";
VAL_ 905 ST_PO_CSOV_AIC 0 "Diagnose noch nicht abgelaufen" 1 "Kühlventil nicht bestromt" 2 "Kühlventil bestromt" 3 "Signal_unbefuellt";
VAL_ 895 ST_ACY_VEH_TONE 0 "Außensound inaktiv" 1 "Default-Wert" 3 "Signal ungültig";
VAL_ 838 ALIV_ST_VIB_STW 15 "Signal ungültig";
VAL_ 838 QU_HOFF_RCOG_SEN 1 "Überwachung läuft, es wurde keine Hands-Off erkannt" 5 "STA Funktion ausgeschaltet" 9 "Überwachung läuft, Hands-Off wurde erkannt" 13 "Erkennung nicht verfügbar (z.B. während der Initialisierung, HOD Sensor nicht codiert)" 14 "Fehler, keine Erkennung möglich" 15 "Signal unbefüllt";
VAL_ 838 QU_SER_VIB_STW 32 "Service verfügbar: keine Anforderung erkannt" 33 "LRE i.o., Aktuator i.O." 40 "Service verfügbar: Anforderung erkannt" 42 "LRE i.O., Aktuator i.O." 48 "Reserved" 100 "Fehler Aktuator, führt zu CC-Meldung" 101 "Fehler Aktuator, Aktuator temporär nicht verfügbar (Überhitzung LRE)" 102 "Fehler Aktuator (Kurzschluß, Openload, ...),  Aktuator dauerhaft nicht verfügbar" 112 "Wird versendet, wenn die Funktion nicht codiert und daher deaktiviert ist." 128 "Tritt während der Initialisierungsphase auf bis Ist Wert verfügbar (Vorbefüllung)" 176 "Reserved" 224 "Keine Kommunikation zu Line Slave durch Unter- Überspannung bzw. Kurzschluß der LIN Versorgungsspannung" 255 "Wird versendet, wenn vom LRE Slave keine gültigen Daten im Signal ST_RQ_VIB_STW_LIN empfangen werden.";
VAL_ 838 AVL_AMP_VIB_STW 15 "Signal ungültig";
VAL_ 889 SU_FN_FRSG_ASST_DXP 0 "Verzögerungsassistent nicht aktiv" 1 "Verzögerungsassistent aktiv" 3 "Signal ungültig";
VAL_ 889 SU_VL_THO_ECS_DXP 0 "Eco Limit nicht aktiv" 255 "Sendefunktion nicht in Betrieb";
VAL_ 804 SU_CLU_TORQ_PA_DXP 1 "Sport" 2 "Sport+" 3 "Basis" 4 "Comfort" 5 "ECO" 13 "SIGNALTAG_FCTIF_NOT_AVAILABLE" 14 "SIGNALTAG_FCT_ERROR" 15 "Sendefunktion nicht in Betrieb";
VAL_ 804 SU_FN_SAIL_DXP 0 "Segeln nicht zulassen" 1 "Segeln zulassen" 13 "SIGNALTAG_FCTIF_NOT_AVAILABLE" 14 "SIGNALTAG_FCT_ERROR" 15 "Sendefunktion nicht in Betrieb";
VAL_ 804 RequestSportDrivingModeReduction 13 "SIGNALTAG_FCTIF_NOT_AVAILABLE" 14 "SIGNALTAG_FCT_ERROR" 15 "Signal_unbefuellt";
VAL_ 975 DISP_RDO_BUT 0 "Keine_Anzeige" 1 "Anzeige_Standard" 2 "Anzeige_Beruhigt" 4 "Anzeige_Individual" 8 "Anzeige_M_View" 255 "Sendefunktion nicht in Betrieb";
VAL_ 975 DISP_SCTRL 0 "Keine_Anzeige" 1 "Anzeige_Slider_Helligkeit" 2 "Anzeige_Slider_Hoehe" 4 "Anzeige_Slider_Rotation" 255 "Sendefunktion nicht in Betrieb";
VAL_ 975 DISP_LNK 0 "Keine_Anzeige" 1 "Reitersystem / Benachrichtigungen / Pop-ups anpassen" 2 "Anzeige_Link_Individual_konfigurieren" 4 "Anzeige_Link_Geschwindigkeitsassistenz" 255 "Sendefunktion nicht in Betrieb";
VAL_ 975 LST_REGI_S_DISP_HUD 0 "Keine_Anzeige" 1 "Listeneintrag \"aus\" anzeigen" 2 "Listeneintrag \"im SPORT-Modus\" anzeigen" 4 "Listeneintrag \"in der S-Gasse\" anzeigen" 8 "Listeneintrag \"in SPORT-Modus & S-Gasse\" anzeigen" 16 "Listeneintrag \"permanent\" anzeigen" 255 "Sendefunktion nicht in Betrieb";
VAL_ 1028 SU_MDRV_3_IDX 0 "M1 Konfiguration" 1 "M2 Konfiguration" 3 "Keine Konfiguration" 15 "Sendefunktion nicht in Betrieb";
VAL_ 1028 SU_MDRV_3_DRVGMOD 0 "Keine Aenderung" 1 "Fahrmodus 1 in Mx Konfiguration" 2 "Fahrmodus 2 in Mx Konfiguration" 3 "Fahrmodus 3 in Mx Konfiguration" 15 "Sendefunktion nicht in Betrieb";
VAL_ 1028 SU_MDRV_3_SOU 0 "Keine Aenderung" 1 "Soundmodus Leise aus in Mx Konfiguration" 2 "Soundmodus Leise an in Mx Konfiguration" 3 "Sendefunktion nicht in Betrieb";
VAL_ 1028 SU_MDRV_3_MSA 0 "Keine Aenderung" 1 "MSA Modus aus in Mx Konfiguration" 2 "MSA Modus an in Mx Konfiguration" 3 "Sendefunktion nicht in Betrieb";
VAL_ 1028 SU_MDRV_3_ASR 0 "Keine Aenderung" 1 "ASR Modus aus in Mx Konfiguration" 2 "ASR Modus an in Mx Konfiguration" 3 "Sendefunktion nicht in Betrieb";
VAL_ 1028 SU_MDRV_3_BRPD 0 "Keine_Aenderung" 1 "Kennlinie_1" 2 "Kennlinie_2" 3 "Kennlinie_3" 15 "Sendefunktion nicht in Betrieb";
VAL_ 1028 SetupMDrive3MControlPlusTraction 0 "Keine_Aenderung" 1 "Traktion_Level_0" 2 "Traktion_Level_1" 3 "Traktion_Level_2" 4 "Traktion_Level_3" 5 "Traktion_Level_4" 6 "Traktion_Level_5" 7 "Traktion_Level_6" 8 "Traktion_Level_7" 9 "Traktion_Level_8" 10 "Traktion_Level_9" 11 "Traktion_Level_10" 13 "SIGNALTAG_FCTIF_NOT_AVAILABLE" 14 "SIGNALTAG_FCT_ERROR" 15 "Sendefunktion nicht in Betrieb";
VAL_ 1028 SetupMDrive3MControlPlusBrakeBal 0 "Keine_Aenderung" 1 "Bremsbalance_Level_0" 2 "Bremsbalance_Level_1" 3 "Bremsbalance_Level_2" 4 "Bremsbalance_Level_3" 5 "Bremsbalance_Level_4" 6 "Bremsbalance_Level_5" 7 "Bremsbalance_Level_6" 8 "Bremsbalance_Level_7" 9 "Bremsbalance_Level_8" 10 "Bremsbalance_Level_9" 11 "Bremsbalance_Level_10" 13 "SIGNALTAG_FCTIF_NOT_AVAILABLE" 14 "SIGNALTAG_FCT_ERROR" 15 "Sendefunktion nicht in Betrieb";
VAL_ 1049 SU_PWF_SWO_LVG_CKM 0 "Keine Angabe" 1 "Nicht aktiv" 2 "Aktiv" 3 "Signal ungültig";
VAL_ 717 OP_SCHRG_DFT_CHRGS_KEY 0 "Keine gültige Auswahl für Lademodus auf Abfahrtszeit (nur bei Werksauslieferung)" 1 "Sofort Laden aktiv" 2 "Günstig Laden aktiv (wenn \"Laden_auf_Abfahrtszeit\" aktiv; andernfalls in HMI nur vorausgewählt)" 4 "Intelligent Laden aktiv, wenn \"Lademodus auf Abfahrtszeit\" aktiv; andernfalls in HMI nur vorausgewählt" 13 "Hinweis: Reserviert für funktionale Kennung Signal-Tag." 14 "Hinweis: Reserviert für funktionale Kennung Signal-Tag." 15 "Sendefunktion nicht in Betrieb";
VAL_ 717 OP_SCHRG_ILYCH_KEY 0 "Einmaliges_Sofortladen_inaktiv" 1 "Einmaliges_Sofortladen_aktiv" 3 "Sendefunktion nicht in Betrieb.";
VAL_ 692 OP_SCHRG_DFT_CHRGS_REM 0 "Keine gültige Auswahl für Lademodus auf Abfahrtszeit (nur bei Werksauslieferung)" 1 "Sofort Laden aktiv" 2 "Günstig Laden aktiv (wenn \"Laden_auf_Abfahrtszeit\" aktiv; andernfalls in HMI nur vorausgewählt)" 4 "Intelligent Laden aktiv, wenn \"Lademodus auf Abfahrtszeit\" aktiv; andernfalls in HMI nur vorausgewählt" 8 "Max eDrive aktiv" 9 "Keine_Aktion" 15 "Sendefunktion nicht in Betrieb";
VAL_ 692 OP_SCHRG_ADJU_REM 1 "Optimierung nach Preisinformationen aktiviert (Default)/aktivieren." 2 "Optimierung nach Anteil erneuerbarer Energie aktiviert/aktivieren." 3 "Optimierung nach CO2-Anteil aktiviert/aktivieren." 4 "Keine_Aktion" 13 "SIGNALTAG_FCTIF_NOT_AVAILABLE" 14 "SIGNALTAG_FCT_ERROR" 15 "Sendefunktion nicht in Betrieb";
VAL_ 692 OP_SCHRG_ILYCH_REM 0 "Einmaliges_Sofortladen_inaktiv" 1 "Einmaliges_Sofortladen_aktiv" 2 "Keine_Aktion" 3 "Sendefunktion nicht in Betrieb.";
VAL_ 692 OperationAcCurrentLimitRemote 0 "Ladebegrenzung_nicht_ausgewaehlt" 1 "Ladebegrenzung_ausgewaehlt" 2 "Keine_Aktion" 13 "SIGNALTAG_FCTIF_NOT_AVAILABLE" 14 "SIGNALTAG_FCT_ERROR" 15 "Sendefunktion nicht in Betrieb";
VAL_ 692 OperationChargingCurrentLimitMod 253 "SIGNALTAG_FCTIF_NOT_AVAILABLE" 254 "SIGNALTAG_FCT_ERROR" 255 "Sendefunktion nicht in Betrieb";
VAL_ 848 ST_SU_SAMD_EVEH 0 "MaxEDrive_nicht_als_Aufstartmodus_gewaehlt" 1 "MaxEDrive_als_Aufstartmodus_gewaehlt" 3 "Sendefunktion nicht in Betrieb";
VAL_ 848 ST_ADJU_VEM_VEH 0 "VEM_nicht_aktiv_uebernommen" 1 "VEM_aktiv_uebernommen" 3 "Sendefunktion nicht in Betrieb";
VAL_ 848 SU_DSTN_SOC_BAS 253 "SIGNALTAG_FCTIF_NOT_AVAILABLE" 254 "SIGNALTAG_FCT_ERROR" 255 "Sendefunktion nicht in Betrieb";
VAL_ 848 ST_SU_RECUP_LEV 0 "Keine_Option_ausgewaehlt" 1 "Automatische_Einstellung" 2 "Darf nur in Bedienrichtung verwendet werden." 3 "Beschreibung G08BEV und F56BEV: Rekuperationsniveau 1 mit betraglich geringste Verzögerung" 4 "Beschreibung G08BEV und F56BEV: Rekuperationsniveau 2 mit betraglich höherer Verzögerung als Rekuniveau 1, Jedes weitere Rekuniveau bedeutet betragliche Erhöhrung der Verzögerung" 5 "Rekuniveau_3" 13 "SIGNALTAG_FCTIF_NOT_AVAILABLE" 14 "SIGNALTAG_FCT_ERROR" 15 "Sendefunktion nicht in Betrieb";
VAL_ 848 AVAI_OPTS_RECUP 0 "Keine Einschränkung anliegend" 1 "Traktionsmodus oder DSCoff aktiviert" 2 "Zum Beispiel DSC in Rückfallebene" 3 "Fahrmodus Sport aktiv, keine Adaption der Reku in Sportmodus" 4 "Fahrstufe D nicht eingelegt" 5 "Anhänger am Fahrzeug angehängt" 6 "Zum Beispiel bei verdreckter Radarsenorik" 7 "Verfügbarkeit E-Antrieb eingeschränkt" 8 "automated cruise control is active" 13 "SIGNALTAG_FCTIF_NOT_AVAILABLE" 14 "SIGNALTAG_FCT_ERROR" 15 "Sendefunktion nicht in Betrieb";
VAL_ 848 ACTVN_USC_VEM 1 "Gefaellevorhalt" 2 "Langsamfahrzone_Geschwindigkeitsbegrenzung" 4 "Langsamfahrzone_Strassentyp" 8 "Effiziente_E_Fahrzone_EEFZ" 16 "Stau_LFZ" 32 "Strategische_E_Fahrzone" 64 "Zielzone" 128 "E_Assist" 256 "Deaktivierung_durch_Kunde" 16384 "Freischaltung_vEM_durch_Kartenqualitaet" 65533 "SIGNALTAG_FCTIF_NOT_AVAILABLE" 65534 "SIGNALTAG_FCT_ERROR" 65535 "Sendefunktion nicht in Betrieb";
VAL_ 776 AVL_DRV_EVEH 0 "Modus EV ON nicht gesetzt" 1 "Modus EV ON gesetzt" 15 "Signal ungültig";
VAL_ 776 DISP_DRV_EVEH_KI 0 "AUTO EDRIVE anzeigen" 1 "MAX E DRIVE anzeigen" 2 "BATTERY SAVE anzeigen" 13 "SIGNALTAG_FCTIF_NOT_AVAILABLE" 14 "SIGNALTAG_FCT_ERROR" 15 "Sendefunktion nicht in Betrieb";
VAL_ 776 RQ_SW_EVEH_UD_KI_LST 0 "keine Liste anzeigen" 1 "Listen Update Trigger 1" 2 "Listen Update Trigger 2" 3 "Signal ungültig";
VAL_ 776 ST_EVEH_MOD_AVAI_KI_LST 0 "reserve Modus 3 - nicht verfügbar anzeigen" 1 "AutoEDrive - verfügbar anzeigen" 2 "MaxEDrive - verfügbar anzeigen" 4 "BatterySave - Verfügbar anzeigen" 8 "reserve Modus 1 - verfügbar anzeigen" 16 "reserve Modus 2 - verfügbar anzeigen" 32 "reserve Modus 3 - verfügbar anzeigen" 253 "SIGNALTAG_FCTIF_NOT_AVAILABLE" 254 "SIGNALTAG_FCT_ERROR" 255 "Sendefunktion nicht in Betrieb";
VAL_ 776 ST_EVEH_DISP_PO_KI_LST 0 "Wird bei Fahrzeugen ohne Toggle Taster verschickt" 1 "Auto-EDrive in Mittelposition" 2 "MaxEDrive in Mittelposition" 3 "BatterySave in Mittelposition" 4 "reserve Modus 1 in Mittelposition" 5 "reserve Modus 2 in Mittelposition" 6 "reserve Modus 3 in Mittelposition" 13 "SIGNALTAG_FCTIF_NOT_AVAILABLE" 14 "SIGNALTAG_FCT_ERROR" 15 "Sendefunktion nicht in Betrieb";
VAL_ 776 AVL_SU_SOC_HLD_ACTVN_2 0 "SOC_hold_nicht_aktiviert" 1 "SOC_hold_aktiviert" 3 "Signal_unbefuellt";
VAL_ 309 StatusRPMSyncASD 0 "Kein Drehzahlangleich." 1 "Drehzahlangleich aktiv." 3 "Sendefunktion nicht in Betrieb";
VAL_ 309 StatusShiftASD 0 "Keine Schaltung aktiv." 1 "Rückschaltung aktiv." 2 "Hochschaltung aktiv." 3 "Sendefunktion nicht in Betrieb";
VAL_ 309 IntensityShiftASD 13 "SIGNALTAG_FCTIF_NOT_AVAILABLE" 14 "SIGNALTAG_FCT_ERROR" 15 "Sendefunktion nicht in Betrieb";
VAL_ 750 FunctionBrake 0 "Kein Taster gedrückt/ Trigger abschließen" 2 "Trigger: Ermöglicht einen Tausch der Bremsflüssigkeit ohne Diagnosetester" 4 "Trigger: EPB in den Montagemodus versetzen und IB in den Modus für einen Bremsenservice versetzen" 5 "Trigger: Bei EPB den Montagemodus beenden und bei IB den Modus für den Bremsenservice beenden so wie eine Initialisierung durchführen." 13 "SIGNALTAG_FCTIF_NOT_AVAILABLE" 14 "SIGNALTAG_FCT_ERROR" 15 "Sendefunktion nicht in Betrieb";
VAL_ 1106 VoltageSensorCoolantLevel 4093 "SIGNALTAG_FCTIF_NOT_AVAILABLE" 4094 "SIGNALTAG_FCT_ERROR" 4095 "Sendefunktion nicht in Betrieb";
VAL_ 1196 StatusDiagnosticValveHighVoltage0 0 "Es liegt kein elektrischer Fehler vor." 1 "Verbindungsleitung zwischen Ausgangstreiber und Ventil: Kurzschluss nach Masse (Überstrom) erkannt." 2 "Verbindungsleitung zwischen Ausgangstreiber und Ventil: Kurzschluss nach Versorgungsspannung (zu kleiner Ausgangsstrom) erkannt." 3 "Verbindungsleitung zwischen Ausgangstreiber und Ventil: offene Leitung (kein Ausgangsstrom) erkannt." 4 "Hardwarefehler im Steuergerät am Ausgangstreiber erkannt." 13 "SIGNALTAG_FCTIF_NOT_AVAILABLE" 14 "SIGNALTAG_FCT_ERROR" 15 "Sendefunktion nicht in Betrieb";
VAL_ 1196 StatusDiagnosticValveHighVoltage1 0 "Es liegt kein elektrischer Fehler vor." 1 "Verbindungsleitung zwischen Ausgangstreiber und Ventil: Kurzschluss nach Masse (Überstrom) erkannt." 2 "Verbindungsleitung zwischen Ausgangstreiber und Ventil: Kurzschluss nach Versorgungsspannung (zu kleiner Ausgangsstrom) erkannt." 3 "Verbindungsleitung zwischen Ausgangstreiber und Ventil: offene Leitung (kein Ausgangsstrom) erkannt." 4 "Hardwarefehler im Steuergerät am Ausgangstreiber erkannt." 13 "SIGNALTAG_FCTIF_NOT_AVAILABLE" 14 "SIGNALTAG_FCT_ERROR" 15 "Sendefunktion nicht in Betrieb";
VAL_ 1196 StatusControlValveHighVoltageSto0 0 "System befindet sich in der Initialisierungsphase, keine Aussage über Zustand möglich." 1 "Ventil ist funktional geschlossen (tatsächlicher Bestromungszustand abhängig vom Ventiltyp \"Öffner\" oder \"Schließer\")." 2 "Ventil ist funktional geöffnet (tatsächlicher Bestromungszustand abhängig vom Ventiltyp \"Öffner\" oder \"Schließer\")." 3 "Sendefunktion nicht in Betrieb";
VAL_ 1196 StatusControlValveHighVoltageSto1 0 "System befindet sich in der Initialisierungsphase, keine Aussage über Zustand möglich." 1 "Ventil ist funktional geschlossen (tatsächlicher Bestromungszustand abhängig vom Ventiltyp \"Öffner\" oder \"Schließer\")." 2 "Ventil ist funktional geöffnet (tatsächlicher Bestromungszustand abhängig vom Ventiltyp \"Öffner\" oder \"Schließer\")." 3 "Sendefunktion nicht in Betrieb";
VAL_ 1095 StatusKeyFunction 0 "A key search for the interior vehicle was executed." 1 "A key activation was executed" 2 "A key deactivation was executed" 253 "SIGNALTAG_FCTIF_NOT_AVAILABLE" 254 "SIGNALTAG_FCT_ERROR" 255 "Send function not in operation";
VAL_ 1095 StatusKeyId 0 "Key 0 found or activated" 1 "Key 1 found or activated" 2 "Key 2 found or activated" 3 "Key 3 found or activated" 4 "Key 4 found or activated" 5 "Key 5 found or activated" 6 "Key 6 found or activated" 7 "Key 7 found or activated" 8 "Key 8 found or activated" 9 "Key 9 found or activated" 16 "Key 10 found or activated" 17 "Key 11 found or activated" 18 "Key 12 found or activated" 19 "Key 13 found or activated" 20 "Key 14 found or activated" 21 "Key 15 found or activated" 22 "Key 16 found or activated" 23 "Key 17 found or activated" 24 "Key 18 found or activated" 25 "Key 19 found or activated" 16777213 "SIGNALTAG_FCTIF_NOT_AVAILABLE" 16777214 "SIGNALTAG_FCT_ERROR" 16777215 "Send function not in operation";
VAL_ 1197 StatusDiagnosisFunctionalValve1S0 0 "Diagnose läuft aktuell nicht." 1 "Diagnose läuft aktuell." 2 "Ergebnis aus Diagnosestufe 1" 4 "Ergebnis aus Diagnosestufe 2" 6 "Ergebnis aus Diagnosestufe 3" 8 "Neues Diagnose-Ergebnis vorhanden." 16 "Diagnose abgebrochen ohne Ergebnis" 32 "Diagnose abgeschlossen, kein Fehler gefunden" 48 "Diagnose abgeschlossen, Fehler gefunden" 64 "Diagnose im aktuellen Betriebslauf mind. 1x mit Fehler beendet." 253 "SIGNALTAG_FCTIF_NOT_AVAILABLE" 254 "SIGNALTAG_FCT_ERROR" 255 "Sendefunktion nicht in Betrieb";
VAL_ 1197 StatusDiagnosisFunctionalValve1S1 0 "Diagnose läuft aktuell nicht." 1 "Diagnose läuft aktuell." 2 "Ergebnis aus Diagnosestufe 1" 4 "Ergebnis aus Diagnosestufe 2" 6 "Ergebnis aus Diagnosestufe 3" 8 "Neues Diagnose-Ergebnis vorhanden." 16 "Diagnose abgebrochen ohne Ergebnis" 32 "Diagnose abgeschlossen, kein Fehler gefunden" 48 "Diagnose abgeschlossen, Fehler gefunden" 64 "Diagnose im aktuellen Betriebslauf mind. 1x mit Fehler beendet." 253 "SIGNALTAG_FCTIF_NOT_AVAILABLE" 254 "SIGNALTAG_FCT_ERROR" 255 "Sendefunktion nicht in Betrieb";
VAL_ 1197 StatusDiagnosisFunctionalCPIHigh 0 "Diagnose läuft aktuell nicht." 1 "Diagnose läuft aktuell." 2 "Ergebnis aus Diagnosestufe 1" 4 "Ergebnis aus Diagnosestufe 2" 6 "Ergebnis aus Diagnosestufe 3" 8 "Neues Diagnose-Ergebnis vorhanden." 16 "Diagnose abgebrochen ohne Ergebnis" 32 "Diagnose abgeschlossen, kein Fehler gefunden" 48 "Diagnose abgeschlossen, Fehler gefunden" 64 "Diagnose im aktuellen Betriebslauf mind. 1x mit Fehler beendet." 253 "SIGNALTAG_FCTIF_NOT_AVAILABLE" 254 "SIGNALTAG_FCT_ERROR" 255 "Sendefunktion nicht in Betrieb";
VAL_ 1197 ActualValueTemperatureHighVoltag0 253 "SIGNALTAG_FCTIF_NOT_AVAILABLE" 254 "SIGNALTAG_FCT_ERROR" 255 "Sendefunktion nicht in Betrieb";
VAL_ 1197 ActualValueTemperatureHighVoltag1 253 "SIGNALTAG_FCTIF_NOT_AVAILABLE" 254 "SIGNALTAG_FCT_ERROR" 255 "Sendefunktion nicht in Betrieb";
VAL_ 1197 ActualValueTemperatureHighVoltag2 253 "SIGNALTAG_FCTIF_NOT_AVAILABLE" 254 "SIGNALTAG_FCT_ERROR" 255 "Sendefunktion nicht in Betrieb";
VAL_ 1197 ActualValueTemperatureHeatExchan 1021 "SIGNALTAG_FCTIF_NOT_AVAILABLE" 1022 "SIGNALTAG_FCT_ERROR" 1023 "Sendefunktion nicht in Betrieb";
VAL_ 1197 RequestValveHighVoltageStorage1 0 "Keine Anforderung des Kältemittelabsperrventils." 1 "eTXV_oeffnen" 2 "eTXV_oeffnen_erweitern" 3 "Sendefunktion nicht in Betrieb";
VAL_ 1194 StatusDiagnosisFunctionalValve2S0 0 "Diagnose läuft aktuell nicht." 1 "Diagnose läuft aktuell." 2 "Ergebnis aus Diagnosestufe 1" 4 "Ergebnis aus Diagnosestufe 2" 6 "Ergebnis aus Diagnosestufe 3" 8 "Neues Diagnose-Ergebnis vorhanden." 16 "Diagnose abgebrochen ohne Ergebnis" 32 "Diagnose abgeschlossen, kein Fehler gefunden" 48 "Diagnose abgeschlossen, Fehler gefunden" 64 "Diagnose im aktuellen Betriebslauf mind. 1x mit Fehler beendet." 253 "SIGNALTAG_FCTIF_NOT_AVAILABLE" 254 "SIGNALTAG_FCT_ERROR" 255 "Sendefunktion nicht in Betrieb";
VAL_ 1194 StatusDiagnosisFunctionalValve2S1 0 "Diagnose läuft aktuell nicht." 1 "Diagnose läuft aktuell." 2 "Ergebnis aus Diagnosestufe 1" 4 "Ergebnis aus Diagnosestufe 2" 6 "Ergebnis aus Diagnosestufe 3" 8 "Neues Diagnose-Ergebnis vorhanden." 16 "Diagnose abgebrochen ohne Ergebnis" 32 "Diagnose abgeschlossen, kein Fehler gefunden" 48 "Diagnose abgeschlossen, Fehler gefunden" 64 "Diagnose im aktuellen Betriebslauf mind. 1x mit Fehler beendet." 253 "SIGNALTAG_FCTIF_NOT_AVAILABLE" 254 "SIGNALTAG_FCT_ERROR" 255 "Sendefunktion nicht in Betrieb";
VAL_ 1194 StatusDiagnosisFunctionalCPIHigh 0 "Diagnose läuft aktuell nicht." 1 "Diagnose läuft aktuell." 2 "Ergebnis aus Diagnosestufe 1" 4 "Ergebnis aus Diagnosestufe 2" 6 "Ergebnis aus Diagnosestufe 3" 8 "Neues Diagnose-Ergebnis vorhanden." 16 "Diagnose abgebrochen ohne Ergebnis" 32 "Diagnose abgeschlossen, kein Fehler gefunden" 48 "Diagnose abgeschlossen, Fehler gefunden" 64 "Diagnose im aktuellen Betriebslauf mind. 1x mit Fehler beendet." 253 "SIGNALTAG_FCTIF_NOT_AVAILABLE" 254 "SIGNALTAG_FCT_ERROR" 255 "Sendefunktion nicht in Betrieb";
VAL_ 1194 ActualValueTemperatureHighVoltag0 253 "SIGNALTAG_FCTIF_NOT_AVAILABLE" 254 "SIGNALTAG_FCT_ERROR" 255 "Sendefunktion nicht in Betrieb";
VAL_ 1194 ActualValueTemperatureHighVoltag1 253 "SIGNALTAG_FCTIF_NOT_AVAILABLE" 254 "SIGNALTAG_FCT_ERROR" 255 "Sendefunktion nicht in Betrieb";
VAL_ 1194 ActualValueTemperatureHighVoltag2 253 "SIGNALTAG_FCTIF_NOT_AVAILABLE" 254 "SIGNALTAG_FCT_ERROR" 255 "Sendefunktion nicht in Betrieb";
VAL_ 1194 ActualValueTemperatureHeatExchan 1021 "SIGNALTAG_FCTIF_NOT_AVAILABLE" 1022 "SIGNALTAG_FCT_ERROR" 1023 "Sendefunktion nicht in Betrieb";
VAL_ 1194 RequestValveHighVoltageStorage2 0 "Keine Anforderung des Kältemittelabsperrventils." 1 "eTXV_oeffnen" 2 "eTXV_oeffnen_erweitern" 3 "Sendefunktion nicht in Betrieb";
VAL_ 883 FLLV_FUTA_2 4093 "Hinweis: Reserviert für funktionale Kennung Signal-Tag." 4094 "Hinweis: Reserviert für funktionale Kennung Signal-Tag." 4095 "Sendefunktion nicht in Betrieb";
VAL_ 883 RNG_BT 4093 "Hinweis: Reserviert für funktionale Kennung Signal-Tag." 4094 "Hinweis: Reserviert für funktionale Kennung Signal-Tag." 4095 "Sendefunktion nicht in Betrieb";
VAL_ 883 RNG_REX 4093 "Hinweis: Reserviert für funktionale Kennung Signal-Tag." 4094 "Hinweis: Reserviert für funktionale Kennung Signal-Tag." 4095 "Sendefunktion nicht in Betrieb";
VAL_ 858 YR_CBS 255 "Signal ungültig";
VAL_ 858 MON_CBS 15 "Signal ungültig";
VAL_ 858 DayCBS 253 "SIGNALTAG_FCTIF_NOT_AVAILABLE" 254 "SIGNALTAG_FCT_ERROR" 255 "Sendefunktion nicht in Betrieb";
VAL_ 355 AVL_LOGR_RW_FAST 4093 "SIGNALTAG_FCTIF_NOT_AVAILABLE" 4094 "SIGNALTAG_FCT_ERROR" 4095 "Sendefunktion nicht in Betrieb";
VAL_ 165 ST_SAIL_DRV_2 0 "Segeln nicht möglich" 1 "Segeln möglich, passiv" 2 "Übergang in Segeln" 3 "Segeln aktiv" 4 "Übergang aus Segeln" 13 "SIGNALTAG_FCTIF_NOT_AVAILABLE" 14 "SIGNALTAG_FCT_ERROR" 15 "Sendefunktion nicht in Betrieb";
VAL_ 165 QU_AVL_RPM_ENG_CRSH 1 "Signalwert ist gültig und abgesichert und plausibilisiert" 2 "Nockenwellennotlauf. Dynamischer Signalwert wird verschickt" 6 "Fehler (Kurbelwellensensor)" 8 "Diese Kodierung wird nicht nur bei Aufstart gesendet sondern kann auch beim Beenden der Fahrbereitschaft gesendet werden." 14 "Reserviert für Wert_nicht_verfuegbar (Änderungen sind abzustimmen mit den Empfänger-Komponenten und dem LH-Verantwortlichen)" 15 "Signal_unbefuellt";
VAL_ 165 RQ_BL_RECUP 0 "Keine Rekuperation" 1 "Rekuperation Stufe 1 aktiv" 3 "Signal ungültig";
VAL_ 165 VRFD_RLS_TORQ_FAST 0 "INIT" 1 "Momentenaufbau/Kl. 50 nicht erlauben" 2 "Momentenaufbau/Kl. 50 erlauben" 3 "Signal_unbefuellt";
VAL_ 194 TARVL_GTIN_DRAWAY_RPM_CLT 253 "SIGNALTAG_FCTIF_NOT_AVAILABLE" 254 "SIGNALTAG_FCT_ERROR" 255 "Sendefunktion nicht in Betrieb";
VAL_ 194 CTR_ACUS_STAG 4093 "Momentan nicht benutzt" 4094 "Momentan nicht benutzt" 4095 "Sendefunktion nicht in Betrieb";
VAL_ 194 QU_AVL_TORQ_CRSH 0 "Motordrehmoment_mit_voller_Genauigkeit" 1 "Motordrehmoment_mit_eingeschraenkter_Genauigkeit" 3 "Sendefunktion nicht in Betrieb";
VAL_ 194 StatusDriveDestination2 0 "VM_aus_K0_offen_KS_offen_KEM2_offen" 1 "VM_an" 2 "K0_geschlossen" 4 "Kraftschluss_Getriebe_1_geschlossen" 8 "Kraftschluss_Getriebe_1_Getriebestrategie" 29 "SIGNALTAG_FCTIF_NOT_AVAILABLE" 30 "SIGNALTAG_FCT_ERROR" 31 "Sendefunktion nicht in Betrieb";
VAL_ 194 StatusDriveTarget2 0 "VM_aus_K0_offen_KS_offen_KEM2_offen" 1 "VM_an" 2 "K0_geschlossen" 4 "Kraftschluss_Getriebe_1_geschlossen" 8 "Kraftschluss_Getriebe_1_Getriebestrategie" 29 "SIGNALTAG_FCTIF_NOT_AVAILABLE" 30 "SIGNALTAG_FCT_ERROR" 31 "Sendefunktion nicht in Betrieb";
VAL_ 760 DISP_DATE_WDAY 1 "Montag" 2 "Dienstag" 3 "Mittwoch" 4 "Donnerstag" 5 "Freitag" 6 "Samstag" 7 "Sonntag" 15 "Signal ungültig";
VAL_ 826 HR_UTC 253 "SIGNALTAG_FCTIF_NOT_AVAILABLE" 254 "Hinweis: Reserviert für funktionale Kennung Signal-Tag." 255 "Sendefunktion nicht in Betrieb";
VAL_ 826 MN_UTC 253 "SIGNALTAG_FCTIF_NOT_AVAILABLE" 254 "Hinweis: Reserviert für funktionale Kennung Signal-Tag." 255 "Sendefunktion nicht in Betrieb";
VAL_ 826 SEC_UTC 253 "SIGNALTAG_FCTIF_NOT_AVAILABLE" 254 "Hinweis: Reserviert für funktionale Kennung Signal-Tag." 255 "Sendefunktion nicht in Betrieb";
VAL_ 826 DATE_DAY_UTC 253 "SIGNALTAG_FCTIF_NOT_AVAILABLE" 254 "SIGNALTAG_FCT_ERROR" 255 "Sendefunktion nicht in Betrieb";
VAL_ 826 ST_CTI_DATE_UTC 0 "Daten von der angezeigten Uhrzeit abgeleitet, keine UTC-basierte Uhrzeit!" 1 "Ortszeit Werk (keine UTC-Zeit)" 2 "UTC-Uhrzeit und UTC-Datum verfügbar und über Quarz <= 4h weitergezählt, Offsets nicht verfügbar" 3 "UTC-Uhrzeit und UTC-Datum verfügbar und über Quarz > 4h weitergezählt, Offsets nicht verfügbar" 4 "nur UTC-Zeit verfügbar und über Quarz weitergezählt, Datum ggf. aus dem EEPROM restauriert und nicht aktuell, Offsets nicht verfügbar" 5 "nur UTC-Datum verfügbar und über Quarz weitergezählt, Offsets nicht verfügbar" 6 "Uhrzeit_vom_Werk_mit_UTC_gestellt_und_ueber_Quarz_weitergezaehlt" 8 "Aufgrund der Rahmenbedingungen kann nicht sichergestellt werden, dass die Uhrzeit und das Datum noch die Toleranzen einhalten ( z. B. nach einem Software-Update )" 13 "SIGNALTAG_FCTIF_NOT_AVAILABLE" 14 "SIGNALTAG_FCT_ERROR" 15 "Sendefunktion nicht in Betrieb";
VAL_ 826 DATE_MON_UTC 13 "SIGNALTAG_FCTIF_NOT_AVAILABLE" 14 "SIGNALTAG_FCT_ERROR" 15 "Sendefunktion nicht in Betrieb";
VAL_ 826 DATE_YR_UTC 253 "SIGNALTAG_FCTIF_NOT_AVAILABLE" 254 "SIGNALTAG_FCT_ERROR" 255 "Sendefunktion nicht in Betrieb";
VAL_ 826 TZS_OFFS_AUTOMLY_UTC 253 "SIGNALTAG_FCTIF_NOT_AVAILABLE" 254 "Hinweis: Reserviert für funktionale Kennung Signal-Tag." 255 "Sendefunktion nicht in Betrieb";
VAL_ 826 OFFS_WIT_SUT_UTC 13 "SIGNALTAG_FCTIF_NOT_AVAILABLE" 14 "Hinweis: Reserviert für funktionale Kennung Signal-Tag." 15 "Sendefunktion nicht in Betrieb";
VAL_ 772 U_IBS 65533 "Hinweis: Reserviert für funktionale Kennung Signal-Tag." 65534 "Hinweis: Reserviert für funktionale Kennung Signal-Tag." 65535 "Sendefunktion nicht in Betrieb";
VAL_ 772 ST_STRY_U_PWMG 0 "Lademodus Prio1" 1 "Lademodus Prio2" 2 "Lademodus Prio3" 3 "IGR-BalanceHold - Nullstromregelung" 4 "IGR-Discharge - Entladefunktion" 5 "IGR-Recuperation" 6 "Stabilisierung" 7 "Generatorabschaltung" 8 "Steuerung durch Clientanforderung" 13 "SIGNALTAG_FCTIF_NOT_AVAILABLE" 14 "SIGNALTAG_FCT_ERROR" 15 "Sendefunktion nicht in Betrieb";
VAL_ 417 QU_V_VEH_COG 1 "Signalwert ist gültig und abgesichert und plausibilisiert" 2 "Reserved" 3 "Reserved" 4 "Reserved" 6 "Reserved" 7 "Reserved" 8 "Tritt während der Initialisierungsphase auf bis Ist-Wert verfügbar (Vorbefüllung). Nutzsignal wird permanent mit Nutzwert 0 befüllt." 9 "Reserved" 10 "FUSI: Eine für die Berechnung der Geschwindigkeit notwendige Größe fehlt (z.B. Längsbeschleunigung, Raddrehzahl,...). Signalqualität bei instabiler Fahrt eingeschränkt. (Für sicherheitsrelevante Funktionen Anwendbarkeit des Signals prüfen.)" 11 "FUSI: Mehr als eine für die Berechnung der Geschwindigkeit notwendige Größe fehlt (z.B. Längsbeschleunigung, Raddrehzahl,...). Signalqualität bei instabiler Fahrt eingeschränkt. (Für sicherheitsrelevante Funktionen Anwendbarkeit des Signals prüfen.)" 12 "Reserved" 14 "Keine Raddrehzahlen verfügbar, Berechnung der Geschwindigkeit nicht möglich. Das zugehörige Nutzsignal wird permanent mit der Ungültigkeitskennung befüllt." 15 "Kann nur vom Gateway gesetzt werden";
VAL_ 373 DRVDIR_VEH_CFD 0 "Fahrzeug steht" 1 "Fahrzeug fährt vorwärts" 2 "Fahrzeug fährt rückwärts" 3 "Fahrzeug fährt" 13 "Reserviert für funktionale Kennung Signal-Tag" 14 "SIGNALTAG_FCT_ERROR" 15 "Sendefunktion nicht in Betrieb";
VAL_ 373 ST_DYNOMOD 0 "Kein Rollprüfstand" 1 "Fahrzeug auf Vorderachs-Ein-Achs-Rollenprüfstand." 2 "Fahrzeug auf Hinterachs-Ein-Achs-Rollenprüfstand." 3 "Fahrzeug auf Zwei -Achs- Rollenprüfstand." 13 "Reserviert für funktionale Kennung Signal-Tag" 14 "SIGNALTAG_FCT_ERROR" 15 "Sendefunktion nicht in Betrieb";
VAL_ 373 ST_EOLMOD 0 "Bandendemodus nicht gesetzt" 1 "Fahrzeug auf Zwei-Achs-Bandendeprüfstandsrolle" 13 "Reserviert für funktionale Kennung Signal-Tag" 14 "SIGNALTAG_FCT_ERROR" 15 "Sendefunktion nicht in Betrieb";
VAL_ 373 DRVDIR_VEH_UCNFR 0 "Initialbefüllung" 1 "Fahrzeug fährt vorwärts" 2 "Fahrzeug fährt rückwärts" 3 "Bei Fahrzeug-Bewegung, jedoch nicht eindeutig zuzuordnender Fahrtrichtung" 13 "Reserviert für funktionale Kennung Signal-Tag" 14 "SIGNALTAG_FCT_ERROR" 15 "Sendefunktion nicht in Betrieb";
VAL_ 1037 ST_STAGMST 1 "Inszenierungsmaster hat noch keine Informationen (da z.B. Fahrzeug in Standfunktionen)." 2 "Dieser Wert liegt an, wenn ein Übergang nach Wohnen ohne Inszenierung erfolgt. Die HU kann gleich auf  Bereitschaftscreen wechseln (bzw. Splashscreen anzeigen, wenn Sie noch booten muss)." 3 "Dieser Wert liegt an, wenn ein Übergang nach Wohnen mit Inszenierung erfolgt. Die HU wartet bis sie den Trigger zum Starten des Films erhält." 255 "Sendefunktion nicht in Betrieb";
VAL_ 1037 TR_STAG_HU 1 "Defaultwert - Solange die HU diesen Wert empfängt, wird in der HU keine Inszenierung gestartet." 2 "Sobald dieser Wert versendet wird, kann die Head Unit mit dem Abspielen des Filmes beginnen." 3 "Info von Inszenierungsmaster an HU, dass Inszenierung im Kombi abgebrochen wurde." 255 "Sendefunktion nicht in Betrieb";
VAL_ 550 V_WI 0 "Wischer muss in der Ruhelage bleiben" 15 "Wischer muss in der Ruhelage bleiben";
VAL_ 550 ST_RNSE 0 "Regensensor in Ordnung" 1 "Wischgeschwindigkeit sofort übernehmen!" 2 "Nur E65" 4 "Notlauf = Intervall Stellung 3" 15 "Letzter Stand";
VAL_ 143 ALIV_WMOM_DRV_1 15 "Signal ungültig";
VAL_ 143 QU_AVL_WMOM_PT_SUM 1 "reserviert" 2 "Normalzustand" 3 "Sensor oder Aktorfehler (z.B. Raddrehzahl) beeinträchtigen die Signalqualität." 4 "reserviert" 6 "Fehlerfall" 7 "reserviert" 8 "Initialisierung" 9 "reserviert" 10 "Motor kann kein Schleppmoment aufnehmen" 11 "reserviert" 12 "Signalwert nicht ermittelbar. Abgleichwert wird versandt." 14 "reserviert" 15 "Darf ausschließlich durch ein Gateway gesetzt werden";
VAL_ 143 QU_REIN_PT 1 "Normalzustand Automatisches Getriebe" 2 "Normalzustand manuelles Getriebe (Handschalter)" 4 "Ersatzwerte aus in der DME hinterlegten Tabelle (nur bei Hybrid mit EVT-Getriebe)" 6 "Fehlerzustand Nmot/Nrad nicht bestimmbar" 8 "Initialisierung" 9 "WK geöffnet/geregelt oder Zustandsübergang zum öffnen/regeln" 11 "Strangverstärkung aus Ersatzfunktion beim Automatischen Getriebe" 12 "Im Steuergeräte-Nachlauf" 15 "Darf ausschließlich durch ein Gateway gesetzt werden";
VAL_ 220 ST_INTF_DRASY_TAR_LIM 0 "Fahrpedal nicht getreten, keine FAS-Anforderung" 1 "Fahrpedal nicht getreten, Fahreranforderung kleiner FAS-Sollmoment-TAR" 2 "Fahrpedal nicht getreten, Fahreranforderung größer FAS-Sollmoment-TAR UND/ODER Fahreranforderung kleiner FAS-Sollmoment-LIM" 3 "Fahrpedal nicht getreten, Fahreranforderung größer FAS-Sollmoment-LIM" 4 "Fahrpedal getreten, keine FAS-Anforderung" 5 "Fahrpedal getreten, Fahreranforderung kleiner FAS-Sollmoment-TAR" 6 "Fahrpedal getreten, Fahreranforderung größer FAS-Sollmoment-TAR UND/ODER Fahreranforderung kleiner FAS-Sollmoment-LIM" 7 "Fahrpedal getreten, Fahreranforderung größer FAS-Sollmoment-LIM" 13 "SIGNALTAG_FCTIF_NOT_AVAILABLE" 14 "SIGNALTAG_FCT_ERROR" 15 "Sendefunktion nicht in Betrieb";
VAL_ 220 ST_DRVDIR_DVCH 0 "Initialisierung" 2 "Park oder Neutral, beim Handschalter: kein Kraftschluss" 4 "CVT, Gang 1-9, Handschalter: kein Rückwärtsgang und Kraftschluss erkannt" 5 "Rückwärtsgang" 15 "Signal ungültig";
VAL_ 220 QU_AVL_RPM_BAX_RED 2 "Normalzustand" 6 "Fehler" 7 "Handschalter" 8 "Beim Erststart des Steuergeräts: Bis gelernte Hinterachsübersetzung > 0" 15 "Darf ausschließlich durch ein Gateway gesetzt werden";
VAL_ 220 ST_AVAI_INTV_PT_DRS 0 "Eingriff nicht erlaubt wegen GWS-Betätigung" 1 "Eingriff erlaubt" 2 "Eingriff nicht erlaubt" 3 "Wird funktional nicht versendet.";
VAL_ 220 CTR_ACTVN_PWHOP 0 "Power Hop - Keine Bremsunterstützung angefordert" 1 "Power Hop aktiv - Anforderung Bremsunterstützung Schwelle 1" 2 "Power Hop aktiv - Anforderung Bremsunterstützung Schwelle 2" 3 "Wird gesetzt wenn die Funktion nicht verbaut ist.";
SIG_GROUP_ 888 e2eGrp_ST_PMA 1 : CRC_ST_PMA ALIV_ST_PMA ST_PMA_dummy_12_15 QU_FN_PMA QU_FN_PMA_POU CTR_SUP_RSTG_DI_PMA ST_PMA_dummy_34_39 QU_FN_RVAS QU_FN_TRAS QU_FN_LCL_FAS_PKG;
SIG_GROUP_ 619 e2eGrp_ST_RSP_BN2020 1 : CRC_ST_RSP_BN2020 ALIV_ST_RSP_BN2020 ST_RSP_2 ST_MOD_RSP ST_RSP_BN2020_dummy_18_31 ST_RSP_BN2020_dummy_32_63;
SIG_GROUP_ 544 e2eGrp_ST_RSU_CON 1 : CRC_ST_RSU_CON ALIV_ST_RSU_CON CHL_ST_RSU_CON ST_RSU_ACY ST_RSU_CON_dummy_21_31 ST_RSU_CON_dummy_32_63;
SIG_GROUP_ 1101 e2eGrp_ST_RSU_MST 1 : CRC_ST_RSU_MST ALIV_ST_RSU_MST CHL_ST_RSU_MST RSU_CON_PWF RSU_DWA_ARM ST_RSU_MST_dummy_21_31 ST_RSU_MST_dummy_32_63;
SIG_GROUP_ 693 e2eGrp_ST_SSFN_DSC 1 : CRC_ST_SSFN_DSC ALIV_ST_SSFN_DSC CHL_ST_SSFN_DSC ST_RBKR ST_HHASS ST_AH ST_HYD_DYN_BRKFN ST_PBRK RQ_DTR_SSFN ControlLedAutoHold OP_PUBU_EPB QU_FN_PCR_IBK ST_SSFN_DSC_dummy_40_63;
SIG_GROUP_ 371 e2eGrp_ST_STAB_DSC 1 : CRC_ST_STAB_DSC ALIV_ST_STAB_DSC ST_ECU_ST_STAB_DSC QU_FN_FDR QU_FN_ABS QU_FN_ASC ST_BRG_MSA ST_BRG_DV ST_UNRU_DSC;
SIG_GROUP_ 873 e2eGrp_ST_TYR 1 : CRC_ST_TYR ALIV_ST_TYR ST_TYR_dummy_12_15 QU_FN_TYR_INFO QU_TPL QU_TFAI;
SIG_GROUP_ 838 e2eGrp_ST_VIB_STW 1 : CRC_ST_VIB_STW ALIV_ST_VIB_STW QU_HOFF_RCOG_SEN QU_SER_VIB_STW AVL_AMP_VIB_STW ST_VIB_STW_dummy_28_31;
SIG_GROUP_ 355 e2eGrp_TLT_RW 1 : CRC_TLT_RW ALIV_TLT_RW TLT_RW_dummy_12_15 AVL_LOGR_RW QU_AVL_LOGR_RW AVL_TRGR_RW QU_AVL_TRGR_RW AVL_LOGR_RW_FAST TLT_RW_dummy_60_63;
SIG_GROUP_ 165 e2eGrp_TORQ_CRSH_1 1 : CRC_TORQ_CRSH_1 ALIV_TORQ_CRSH_1 ST_SAIL_DRV_2 AVL_TORQ_CRSH AVL_TORQ_CRSH_DMEE AVL_RPM_ENG_CRSH QU_AVL_RPM_ENG_CRSH RQ_BL_RECUP VRFD_RLS_TORQ_FAST;
SIG_GROUP_ 194 e2eGrp_TORQ_CRSH_4 1 : CRC_TORQ_CRSH_4 ALIV_TORQ_CRSH_4 CHL_TORQ_CRSH_4 AVL_RPM_ENG_CRSH_LOW_EPL TARVL_GTIN_DRAWAY_RPM_CLT CTR_ACUS_STAG QU_AVL_TORQ_CRSH StatusDriveDestination2 StatusDriveTarget2;
SIG_GROUP_ 760 signalGrp_UHRZEIT_DATUM 1 : DISP_HR DISP_MN DISP_SEC DISP_DATE_DAY DISP_DATE_WDAY DISP_DATE_MON DISP_DATE_YR ST_DISP_CTI_DATE;
SIG_GROUP_ 415 e2eGrp_VYAW_VEH 1 : CRC_VYAW_VEH ALIV_VYAW_VEH VYAW_VEH_dummy_12_15 VYAW_VEH VYAW_VEH_ERR_AMP QU_VYAW_VEH;
SIG_GROUP_ 417 e2eGrp_V_VEH 1 : CRC_V_VEH ALIV_V_VEH ST_V_VEH_NSS V_VEH_COG QU_V_VEH_COG DVCO_VEH V_VEH_dummy_39_39;
SIG_GROUP_ 373 e2eGrp_V_VEH_2 1 : DRVDIR_VEH_CFD ST_DYNOMOD ST_EOLMOD V_VEH_2_dummy_12_15 DRVDIR_VEH_UCNFR QU_VelocityVehicleLowDynamics StatusVelocityCalculation V_VEH_2_dummy_30_31 VelocityVehicleLowDynamics V_VEH_2_dummy_48_51 ALIV_V_VEH_2 CRC_V_VEH_2;
SIG_GROUP_ 143 e2eGrp_WMOM_DRV_1 1 : CRC_WMOM_DRV_1 ALIV_WMOM_DRV_1 DV_AVAI_FAST AVL_WMOM_PT_SUM QU_AVL_WMOM_PT_SUM AVL_WMOM_PT_SUM_ERR_AMP REIN_PT QU_REIN_PT;
SIG_GROUP_ 220 e2eGrp_WMOM_DRV_4 1 : CRC_WMOM_DRV_4 ALIV_WMOM_DRV_4 ST_INTF_DRASY_TAR_LIM ST_DRVDIR_DVCH QU_AVL_RPM_BAX_RED AVL_RPM_BAX_RED ST_PENG_PT ST_AVAI_INTV_PT_DRS CTR_ACTVN_PWHOP;
